VERSION ""

NS_ :

BS_:

BU_:

BO_ 2364677630 HVESP7MS1: 8 Vector__XXX
 SG_ Hvesp7Module1OperationalStatus : 0|2@1+ (1,0) [0|3] "" Vector__XXX
 SG_ Hvesp7Module2OperationalStatus : 2|2@1+ (1,0) [0|3] "" Vector__XXX
 SG_ Hvesp7Module3OperationalStatus : 4|2@1+ (1,0) [0|3] "" Vector__XXX
 SG_ Hvesp7Module4OperationalStatus : 6|2@1+ (1,0) [0|3] "" Vector__XXX
 SG_ Hvesp7Module5OperationalStatus : 8|2@1+ (1,0) [0|3] "" Vector__XXX
 SG_ Hvesp7Module6OperationalStatus : 10|2@1+ (1,0) [0|3] "" Vector__XXX
 SG_ Hvesp7Module7OperationalStatus : 12|2@1+ (1,0) [0|3] "" Vector__XXX
 SG_ Hvesp7Module8OperationalStatus : 14|2@1+ (1,0) [0|3] "" Vector__XXX
 SG_ Hvesp7Module9OperationalStatus : 16|2@1+ (1,0) [0|3] "" Vector__XXX
 SG_ Hvesp7Module10OperationalStatus : 18|2@1+ (1,0) [0|3] "" Vector__XXX
 SG_ Hvesp7Module11OperationalStatus : 20|2@1+ (1,0) [0|3] "" Vector__XXX
 SG_ Hvesp7Module12OperationalStatus : 22|2@1+ (1,0) [0|3] "" Vector__XXX
 SG_ Hvesp7Module13OperationalStatus : 24|2@1+ (1,0) [0|3] "" Vector__XXX
 SG_ Hvesp7Module14OperationalStatus : 26|2@1+ (1,0) [0|3] "" Vector__XXX
 SG_ Hvesp7Module15OperationalStatus : 28|2@1+ (1,0) [0|3] "" Vector__XXX
 SG_ Hvesp7Module16OperationalStatus : 30|2@1+ (1,0) [0|3] "" Vector__XXX
 SG_ Hvesp7Module17OperationalStatus : 32|2@1+ (1,0) [0|3] "" Vector__XXX
 SG_ Hvesp7Module18OperationalStatus : 34|2@1+ (1,0) [0|3] "" Vector__XXX
 SG_ Hvesp7Module19OperationalStatus : 36|2@1+ (1,0) [0|3] "" Vector__XXX
 SG_ Hvesp7Module20OperationalStatus : 38|2@1+ (1,0) [0|3] "" Vector__XXX
 SG_ Hvesp7Module21OperationalStatus : 40|2@1+ (1,0) [0|3] "" Vector__XXX
 SG_ Hvesp7Module22OperationalStatus : 42|2@1+ (1,0) [0|3] "" Vector__XXX
 SG_ Hvesp7Module23OperationalStatus : 44|2@1+ (1,0) [0|3] "" Vector__XXX
 SG_ Hvesp7Module24OperationalStatus : 46|2@1+ (1,0) [0|3] "" Vector__XXX
 SG_ Hvesp7Module25OperationalStatus : 48|2@1+ (1,0) [0|3] "" Vector__XXX
 SG_ Hvesp7Module26OperationalStatus : 50|2@1+ (1,0) [0|3] "" Vector__XXX
 SG_ Hvesp7Module27OperationalStatus : 52|2@1+ (1,0) [0|3] "" Vector__XXX
 SG_ Hvesp7Module28OperationalStatus : 54|2@1+ (1,0) [0|3] "" Vector__XXX
 SG_ Hvesp7Module29OperationalStatus : 56|2@1+ (1,0) [0|3] "" Vector__XXX
 SG_ Hvesp7Module30OperationalStatus : 58|2@1+ (1,0) [0|3] "" Vector__XXX
 SG_ Hvesp7Module31OperationalStatus : 60|2@1+ (1,0) [0|3] "" Vector__XXX
 SG_ Hvesp7Module32OperationalStatus : 62|2@1+ (1,0) [0|3] "" Vector__XXX

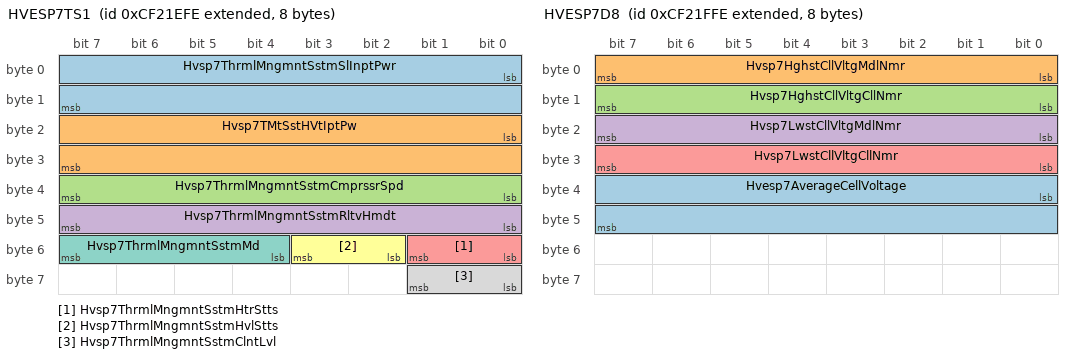
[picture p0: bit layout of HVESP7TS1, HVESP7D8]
BO_ 2364677886 HVESP7TS1: 8 Vector__XXX
 SG_ Hvsp7ThrmlMngmntSstmSlInptPwr : 0|16@1+ (0.5,0) [0|32127.5] "W" Vector__XXX
 SG_ Hvsp7TMtSstHVtIptPw : 16|16@1+ (0.5,0) [0|32127.5] "W" Vector__XXX
 SG_ Hvsp7ThrmlMngmntSstmCmprssrSpd : 32|8@1+ (32,0) [0|8000] "rpm" Vector__XXX
 SG_ Hvsp7ThrmlMngmntSstmRltvHmdt : 40|8@1+ (0.4,0) [0|100] "%" Vector__XXX
 SG_ Hvsp7ThrmlMngmntSstmHtrStts : 48|2@1+ (1,0) [0|3] "" Vector__XXX
 SG_ Hvsp7ThrmlMngmntSstmHvlStts : 50|2@1+ (1,0) [0|3] "" Vector__XXX
 SG_ Hvsp7ThrmlMngmntSstmMd : 52|4@1+ (1,0) [0|15] "" Vector__XXX
 SG_ Hvsp7ThrmlMngmntSstmClntLvl : 56|2@1+ (1,0) [0|3] "" Vector__XXX

BO_ 2364678142 HVESP7D8: 8 Vector__XXX
 SG_ Hvesp7AverageCellVoltage : 32|16@1+ (0.001,0) [0|64.255] "V" Vector__XXX
 SG_ Hvsp7HghstCllVltgMdlNmr : 0|8@1+ (1,0) [0|250] "count" Vector__XXX
 SG_ Hvsp7HghstCllVltgCllNmr : 8|8@1+ (1,0) [0|250] "count" Vector__XXX
 SG_ Hvsp7LwstCllVltgMdlNmr : 16|8@1+ (1,0) [0|250] "count" Vector__XXX
 SG_ Hvsp7LwstCllVltgCllNmr : 24|8@1+ (1,0) [0|250] "count" Vector__XXX

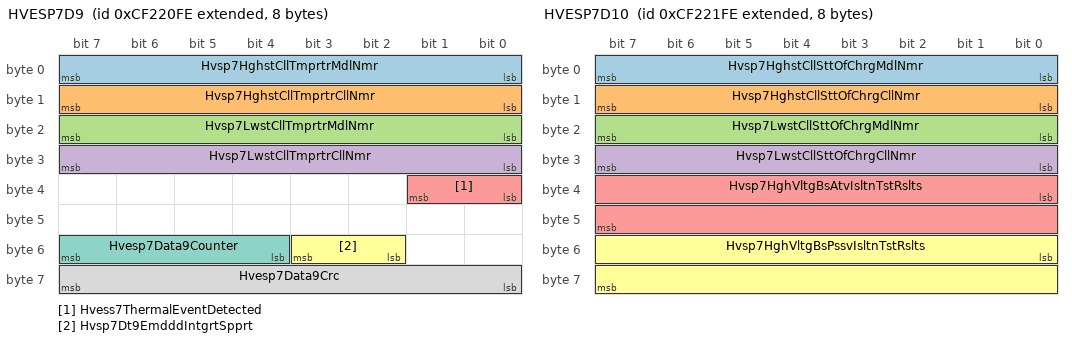
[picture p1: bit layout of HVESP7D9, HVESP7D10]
BO_ 2364678398 HVESP7D9: 8 Vector__XXX
 SG_ Hvsp7HghstCllTmprtrMdlNmr : 0|8@1+ (1,0) [0|250] "count" Vector__XXX
 SG_ Hvsp7HghstCllTmprtrCllNmr : 8|8@1+ (1,0) [0|250] "count" Vector__XXX
 SG_ Hvsp7LwstCllTmprtrMdlNmr : 16|8@1+ (1,0) [0|250] "count" Vector__XXX
 SG_ Hvsp7LwstCllTmprtrCllNmr : 24|8@1+ (1,0) [0|250] "count" Vector__XXX
 SG_ Hvess7ThermalEventDetected : 32|2@1+ (1,0) [0|3] "" Vector__XXX
 SG_ Hvsp7Dt9EmdddIntgrtSpprt : 50|2@1+ (1,0) [0|3] "" Vector__XXX
 SG_ Hvesp7Data9Counter : 52|4@1+ (1,0) [0|15] "" Vector__XXX
 SG_ Hvesp7Data9Crc : 56|8@1+ (1,0) [0|250] "count" Vector__XXX

BO_ 2364678654 HVESP7D10: 8 Vector__XXX
 SG_ Hvsp7HghstCllSttOfChrgMdlNmr : 0|8@1+ (1,0) [0|250] "count" Vector__XXX
 SG_ Hvsp7HghstCllSttOfChrgCllNmr : 8|8@1+ (1,0) [0|250] "count" Vector__XXX
 SG_ Hvsp7LwstCllSttOfChrgMdlNmr : 16|8@1+ (1,0) [0|250] "count" Vector__XXX
 SG_ Hvsp7LwstCllSttOfChrgCllNmr : 24|8@1+ (1,0) [0|250] "count" Vector__XXX
 SG_ Hvsp7HghVltgBsAtvIsltnTstRslts : 32|16@1+ (0.1,0) [0|6425.5] "OhmPerV" Vector__XXX
 SG_ Hvsp7HghVltgBsPssvIsltnTstRslts : 48|16@1+ (0.1,0) [0|6425.5] "OhmPerV" Vector__XXX

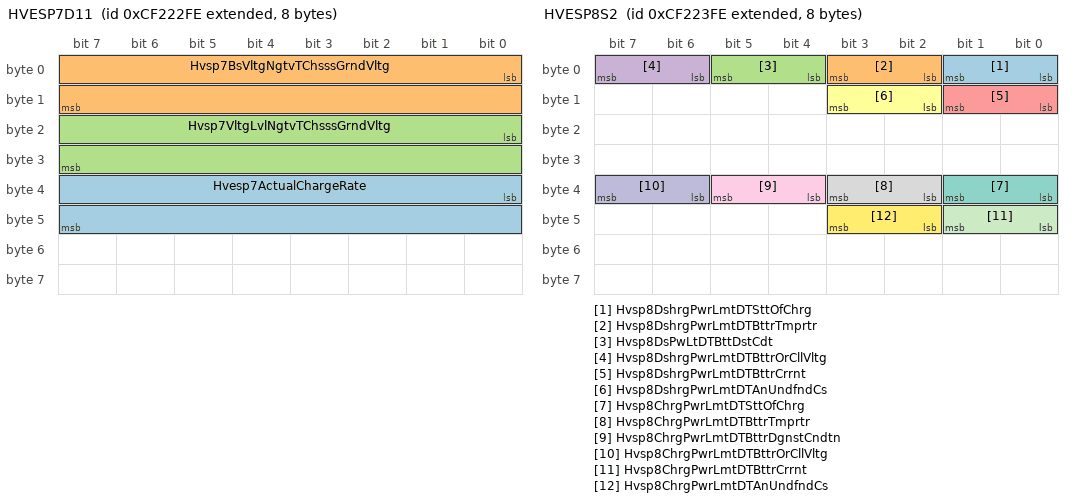
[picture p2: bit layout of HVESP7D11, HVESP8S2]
BO_ 2364678910 HVESP7D11: 8 Vector__XXX
 SG_ Hvesp7ActualChargeRate : 32|16@1+ (0.05,0) [0|3212.75] "kW" Vector__XXX
 SG_ Hvsp7BsVltgNgtvTChsssGrndVltg : 0|16@1+ (0.05,0) [0|3212.75] "V" Vector__XXX
 SG_ Hvsp7VltgLvlNgtvTChsssGrndVltg : 16|16@1+ (0.05,0) [0|3212.75] "V" Vector__XXX

BO_ 2364679166 HVESP8S2: 8 Vector__XXX
 SG_ Hvsp8DshrgPwrLmtDTSttOfChrg : 0|2@1+ (1,0) [0|3] "" Vector__XXX
 SG_ Hvsp8DshrgPwrLmtDTBttrTmprtr : 2|2@1+ (1,0) [0|3] "" Vector__XXX
 SG_ Hvsp8DsPwLtDTBttDstCdt : 4|2@1+ (1,0) [0|3] "" Vector__XXX
 SG_ Hvsp8DshrgPwrLmtDTBttrOrCllVltg : 6|2@1+ (1,0) [0|3] "" Vector__XXX
 SG_ Hvsp8DshrgPwrLmtDTBttrCrrnt : 8|2@1+ (1,0) [0|3] "" Vector__XXX
 SG_ Hvsp8DshrgPwrLmtDTAnUndfndCs : 10|2@1+ (1,0) [0|3] "" Vector__XXX
 SG_ Hvsp8ChrgPwrLmtDTSttOfChrg : 32|2@1+ (1,0) [0|3] "" Vector__XXX
 SG_ Hvsp8ChrgPwrLmtDTBttrTmprtr : 34|2@1+ (1,0) [0|3] "" Vector__XXX
 SG_ Hvsp8ChrgPwrLmtDTBttrDgnstCndtn : 36|2@1+ (1,0) [0|3] "" Vector__XXX
 SG_ Hvsp8ChrgPwrLmtDTBttrOrCllVltg : 38|2@1+ (1,0) [0|3] "" Vector__XXX
 SG_ Hvsp8ChrgPwrLmtDTBttrCrrnt : 40|2@1+ (1,0) [0|3] "" Vector__XXX
 SG_ Hvsp8ChrgPwrLmtDTAnUndfndCs : 42|2@1+ (1,0) [0|3] "" Vector__XXX

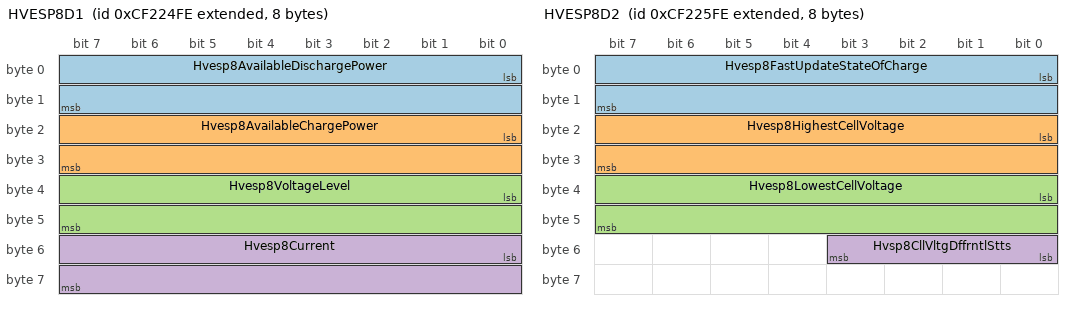
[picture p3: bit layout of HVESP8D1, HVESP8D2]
BO_ 2364679422 HVESP8D1: 8 Vector__XXX
 SG_ Hvesp8AvailableDischargePower : 0|16@1+ (0.05,0) [0|3212.75] "kW" Vector__XXX
 SG_ Hvesp8AvailableChargePower : 16|16@1+ (0.05,0) [0|3212.75] "kW" Vector__XXX
 SG_ Hvesp8VoltageLevel : 32|16@1+ (0.05,0) [0|3212.75] "V" Vector__XXX
 SG_ Hvesp8Current : 48|16@1+ (0.05,-1600) [-1600|1612.75] "A" Vector__XXX

BO_ 2364679678 HVESP8D2: 8 Vector__XXX
 SG_ Hvesp8FastUpdateStateOfCharge : 0|16@1+ (0.0015625,0) [0|100.3984375] "%" Vector__XXX
 SG_ Hvesp8HighestCellVoltage : 16|16@1+ (0.001,0) [0|64.255] "V" Vector__XXX
 SG_ Hvesp8LowestCellVoltage : 32|16@1+ (0.001,0) [0|64.255] "V" Vector__XXX
 SG_ Hvsp8CllVltgDffrntlStts : 48|4@1+ (1,0) [0|15] "" Vector__XXX

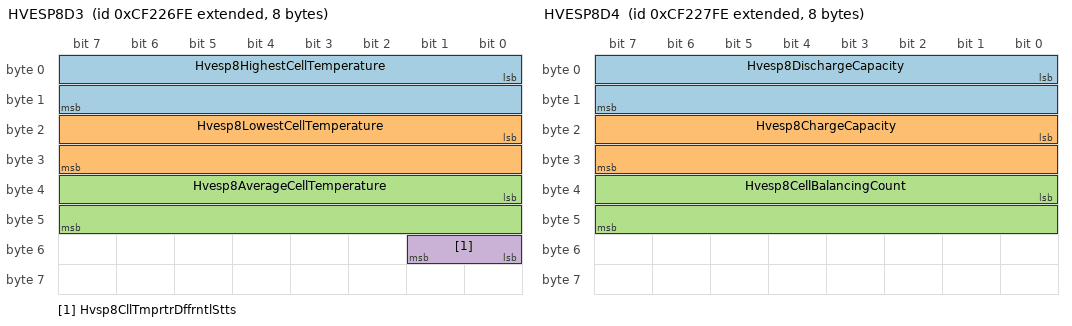
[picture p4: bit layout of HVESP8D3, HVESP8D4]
BO_ 2364679934 HVESP8D3: 8 Vector__XXX
 SG_ Hvesp8HighestCellTemperature : 0|16@1+ (0.03125,-273) [-273|1734.96875] "degC" Vector__XXX
 SG_ Hvesp8LowestCellTemperature : 16|16@1+ (0.03125,-273) [-273|1734.96875] "degC" Vector__XXX
 SG_ Hvesp8AverageCellTemperature : 32|16@1+ (0.03125,-273) [-273|1734.96875] "degC" Vector__XXX
 SG_ Hvsp8CllTmprtrDffrntlStts : 48|2@1+ (1,0) [0|3] "" Vector__XXX

BO_ 2364680190 HVESP8D4: 8 Vector__XXX
 SG_ Hvesp8DischargeCapacity : 0|16@1+ (0.01,0) [0|642.55] "Ah" Vector__XXX
 SG_ Hvesp8ChargeCapacity : 16|16@1+ (0.01,0) [0|642.55] "Ah" Vector__XXX
 SG_ Hvesp8CellBalancingCount : 32|16@1+ (1,0) [0|64255] "count" Vector__XXX

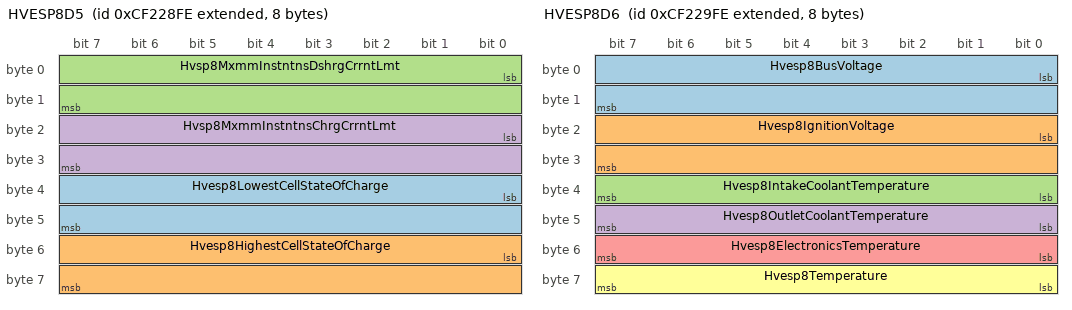
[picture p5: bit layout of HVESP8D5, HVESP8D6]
BO_ 2364680446 HVESP8D5: 8 Vector__XXX
 SG_ Hvesp8LowestCellStateOfCharge : 32|16@1+ (0.0015625,0) [0|100.3984375] "%" Vector__XXX
 SG_ Hvesp8HighestCellStateOfCharge : 48|16@1+ (0.0015625,0) [0|100.3984375] "%" Vector__XXX
 SG_ Hvsp8MxmmInstntnsDshrgCrrntLmt : 0|16@1+ (0.05,-1600) [-1600|0] "A" Vector__XXX
 SG_ Hvsp8MxmmInstntnsChrgCrrntLmt : 16|16@1+ (0.05,-1600) [0|1612.75] "A" Vector__XXX

BO_ 2364680702 HVESP8D6: 8 Vector__XXX
 SG_ Hvesp8BusVoltage : 0|16@1+ (0.05,0) [0|3212.75] "V" Vector__XXX
 SG_ Hvesp8IgnitionVoltage : 16|16@1+ (0.01,0) [0|642.55] "V" Vector__XXX
 SG_ Hvesp8IntakeCoolantTemperature : 32|8@1+ (1,-40) [-40|210] "degC" Vector__XXX
 SG_ Hvesp8OutletCoolantTemperature : 40|8@1+ (1,-40) [-40|210] "degC" Vector__XXX
 SG_ Hvesp8ElectronicsTemperature : 48|8@1+ (1,-40) [-40|210] "degC" Vector__XXX
 SG_ Hvesp8Temperature : 56|8@1+ (1,-40) [-40|210] "degC" Vector__XXX

BO_ 2364680958 HVESP8S1: 8 Vector__XXX
 SG_ Hvesp8HvilStatus : 20|2@1+ (1,0) [0|3] "" Vector__XXX
 SG_ Hvesp8InertiaSwitchStatus : 22|2@1+ (1,0) [0|3] "" Vector__XXX
 SG_ Hvesp8StateOfChargeStatus : 24|4@1+ (1,0) [0|15] "" Vector__XXX
 SG_ Hvesp8CellBalanceStatus : 28|2@1+ (1,0) [0|3] "" Vector__XXX
 SG_ Hvesp8CellBalancingActive : 30|2@1+ (1,0) [0|3] "" Vector__XXX
 SG_ Hvesp8InternalChargerStatus : 32|2@1+ (1,0) [0|3] "" Vector__XXX
 SG_ Hvesp8OperationalStatus : 44|4@1+ (1,0) [0|15] "" Vector__XXX
 SG_ Hvesp8Status1Counter : 52|4@1+ (1,0) [0|15] "" Vector__XXX
 SG_ Hvesp8Status1Crc : 56|8@1+ (1,0) [0|250] "count" Vector__XXX
 SG_ Hvsp8HghVltgBsPstvCnttrStt : 0|2@1+ (1,0) [0|3] "" Vector__XXX
 SG_ Hvsp8HghVltgBsNgtvCnttrStt : 2|2@1+ (1,0) [0|3] "" Vector__XXX
 SG_ Hvsp8HghVltgBsDsnntFrwrnng : 4|4@1+ (1,0) [0|15] "" Vector__XXX
 SG_ Hvsp8HghVltgBsPrChrgRlStt : 8|2@1+ (1,0) [0|3] "" Vector__XXX
 SG_ Hvsp8CntrOfPkCnttrStt : 10|2@1+ (1,0) [0|3] "" Vector__XXX
 SG_ Hvsp8HghVltgBsAtvIsltnTstStts : 12|4@1+ (1,0) [0|15] "" Vector__XXX
 SG_ Hvsp8HghVltgBsPssvIsltnTstStts : 16|4@1+ (1,0) [0|15] "" Vector__XXX
 SG_ Hvsp8HghVltgBsCnntnStts : 40|4@1+ (1,0) [0|15] "" Vector__XXX

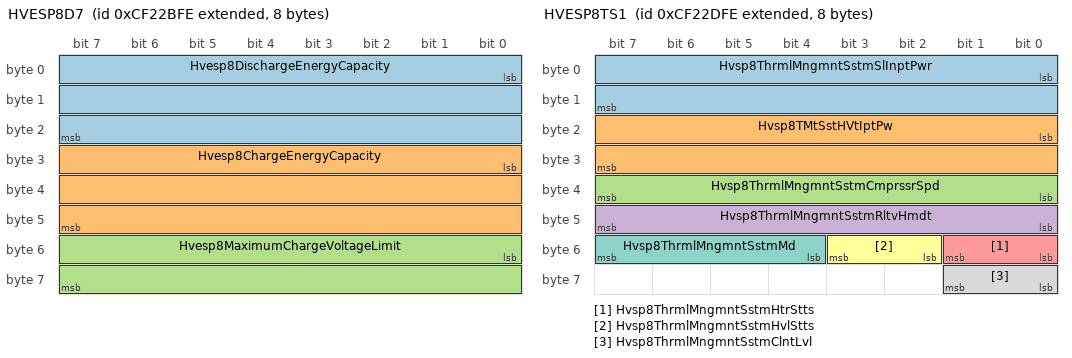
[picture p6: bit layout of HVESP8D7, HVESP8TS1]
BO_ 2364681214 HVESP8D7: 8 Vector__XXX
 SG_ Hvesp8DischargeEnergyCapacity : 0|24@1+ (0.001,0) [0|16449.535] "kWh" Vector__XXX
 SG_ Hvesp8ChargeEnergyCapacity : 24|24@1+ (0.001,0) [0|16449.535] "kWh" Vector__XXX
 SG_ Hvesp8MaximumChargeVoltageLimit : 48|16@1+ (0.05,0) [0|3212.75] "V" Vector__XXX

BO_ 2364681470 HVESP8MS1: 8 Vector__XXX
 SG_ Hvesp8Module1OperationalStatus : 0|2@1+ (1,0) [0|3] "" Vector__XXX
 SG_ Hvesp8Module2OperationalStatus : 2|2@1+ (1,0) [0|3] "" Vector__XXX
 SG_ Hvesp8Module3OperationalStatus : 4|2@1+ (1,0) [0|3] "" Vector__XXX
 SG_ Hvesp8Module4OperationalStatus : 6|2@1+ (1,0) [0|3] "" Vector__XXX
 SG_ Hvesp8Module5OperationalStatus : 8|2@1+ (1,0) [0|3] "" Vector__XXX
 SG_ Hvesp8Module6OperationalStatus : 10|2@1+ (1,0) [0|3] "" Vector__XXX
 SG_ Hvesp8Module7OperationalStatus : 12|2@1+ (1,0) [0|3] "" Vector__XXX
 SG_ Hvesp8Module8OperationalStatus : 14|2@1+ (1,0) [0|3] "" Vector__XXX
 SG_ Hvesp8Module9OperationalStatus : 16|2@1+ (1,0) [0|3] "" Vector__XXX
 SG_ Hvesp8Module10OperationalStatus : 18|2@1+ (1,0) [0|3] "" Vector__XXX
 SG_ Hvesp8Module11OperationalStatus : 20|2@1+ (1,0) [0|3] "" Vector__XXX
 SG_ Hvesp8Module12OperationalStatus : 22|2@1+ (1,0) [0|3] "" Vector__XXX
 SG_ Hvesp8Module13OperationalStatus : 24|2@1+ (1,0) [0|3] "" Vector__XXX
 SG_ Hvesp8Module14OperationalStatus : 26|2@1+ (1,0) [0|3] "" Vector__XXX
 SG_ Hvesp8Module15OperationalStatus : 28|2@1+ (1,0) [0|3] "" Vector__XXX
 SG_ Hvesp8Module16OperationalStatus : 30|2@1+ (1,0) [0|3] "" Vector__XXX
 SG_ Hvesp8Module17OperationalStatus : 32|2@1+ (1,0) [0|3] "" Vector__XXX
 SG_ Hvesp8Module18OperationalStatus : 34|2@1+ (1,0) [0|3] "" Vector__XXX
 SG_ Hvesp8Module19OperationalStatus : 36|2@1+ (1,0) [0|3] "" Vector__XXX
 SG_ Hvesp8Module20OperationalStatus : 38|2@1+ (1,0) [0|3] "" Vector__XXX
 SG_ Hvesp8Module21OperationalStatus : 40|2@1+ (1,0) [0|3] "" Vector__XXX
 SG_ Hvesp8Module22OperationalStatus : 42|2@1+ (1,0) [0|3] "" Vector__XXX
 SG_ Hvesp8Module23OperationalStatus : 44|2@1+ (1,0) [0|3] "" Vector__XXX
 SG_ Hvesp8Module24OperationalStatus : 46|2@1+ (1,0) [0|3] "" Vector__XXX
 SG_ Hvesp8Module25OperationalStatus : 48|2@1+ (1,0) [0|3] "" Vector__XXX
 SG_ Hvesp8Module26OperationalStatus : 50|2@1+ (1,0) [0|3] "" Vector__XXX
 SG_ Hvesp8Module27OperationalStatus : 52|2@1+ (1,0) [0|3] "" Vector__XXX
 SG_ Hvesp8Module28OperationalStatus : 54|2@1+ (1,0) [0|3] "" Vector__XXX
 SG_ Hvesp8Module29OperationalStatus : 56|2@1+ (1,0) [0|3] "" Vector__XXX
 SG_ Hvesp8Module30OperationalStatus : 58|2@1+ (1,0) [0|3] "" Vector__XXX
 SG_ Hvesp8Module31OperationalStatus : 60|2@1+ (1,0) [0|3] "" Vector__XXX
 SG_ Hvesp8Module32OperationalStatus : 62|2@1+ (1,0) [0|3] "" Vector__XXX

BO_ 2364681726 HVESP8TS1: 8 Vector__XXX
 SG_ Hvsp8ThrmlMngmntSstmSlInptPwr : 0|16@1+ (0.5,0) [0|32127.5] "W" Vector__XXX
 SG_ Hvsp8TMtSstHVtIptPw : 16|16@1+ (0.5,0) [0|32127.5] "W" Vector__XXX
 SG_ Hvsp8ThrmlMngmntSstmCmprssrSpd : 32|8@1+ (32,0) [0|8000] "rpm" Vector__XXX
 SG_ Hvsp8ThrmlMngmntSstmRltvHmdt : 40|8@1+ (0.4,0) [0|100] "%" Vector__XXX
 SG_ Hvsp8ThrmlMngmntSstmHtrStts : 48|2@1+ (1,0) [0|3] "" Vector__XXX
 SG_ Hvsp8ThrmlMngmntSstmHvlStts : 50|2@1+ (1,0) [0|3] "" Vector__XXX
 SG_ Hvsp8ThrmlMngmntSstmMd : 52|4@1+ (1,0) [0|15] "" Vector__XXX
 SG_ Hvsp8ThrmlMngmntSstmClntLvl : 56|2@1+ (1,0) [0|3] "" Vector__XXX

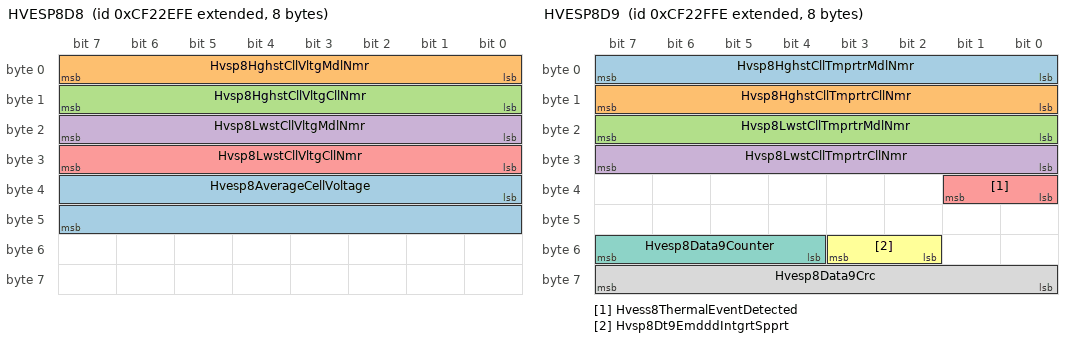
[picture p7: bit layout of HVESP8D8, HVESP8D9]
BO_ 2364681982 HVESP8D8: 8 Vector__XXX
 SG_ Hvesp8AverageCellVoltage : 32|16@1+ (0.001,0) [0|64.255] "V" Vector__XXX
 SG_ Hvsp8HghstCllVltgMdlNmr : 0|8@1+ (1,0) [0|250] "count" Vector__XXX
 SG_ Hvsp8HghstCllVltgCllNmr : 8|8@1+ (1,0) [0|250] "count" Vector__XXX
 SG_ Hvsp8LwstCllVltgMdlNmr : 16|8@1+ (1,0) [0|250] "count" Vector__XXX
 SG_ Hvsp8LwstCllVltgCllNmr : 24|8@1+ (1,0) [0|250] "count" Vector__XXX

BO_ 2364682238 HVESP8D9: 8 Vector__XXX
 SG_ Hvsp8HghstCllTmprtrMdlNmr : 0|8@1+ (1,0) [0|250] "count" Vector__XXX
 SG_ Hvsp8HghstCllTmprtrCllNmr : 8|8@1+ (1,0) [0|250] "count" Vector__XXX
 SG_ Hvsp8LwstCllTmprtrMdlNmr : 16|8@1+ (1,0) [0|250] "count" Vector__XXX
 SG_ Hvsp8LwstCllTmprtrCllNmr : 24|8@1+ (1,0) [0|250] "count" Vector__XXX
 SG_ Hvess8ThermalEventDetected : 32|2@1+ (1,0) [0|3] "" Vector__XXX
 SG_ Hvsp8Dt9EmdddIntgrtSpprt : 50|2@1+ (1,0) [0|3] "" Vector__XXX
 SG_ Hvesp8Data9Counter : 52|4@1+ (1,0) [0|15] "" Vector__XXX
 SG_ Hvesp8Data9Crc : 56|8@1+ (1,0) [0|250] "count" Vector__XXX

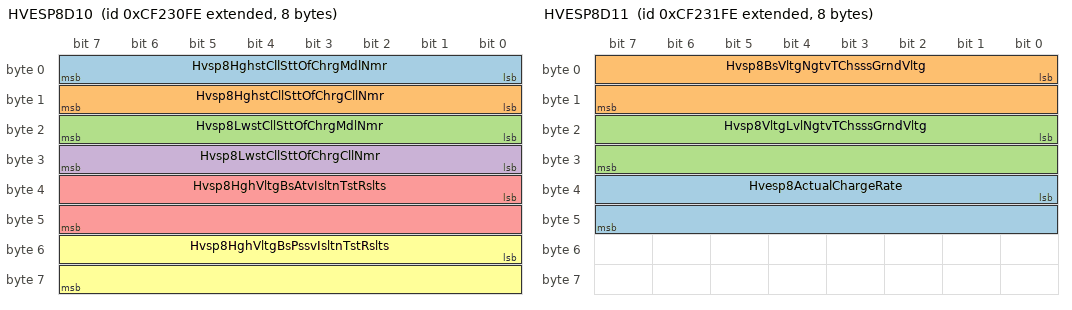
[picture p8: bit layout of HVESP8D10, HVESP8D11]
BO_ 2364682494 HVESP8D10: 8 Vector__XXX
 SG_ Hvsp8HghstCllSttOfChrgMdlNmr : 0|8@1+ (1,0) [0|250] "count" Vector__XXX
 SG_ Hvsp8HghstCllSttOfChrgCllNmr : 8|8@1+ (1,0) [0|250] "count" Vector__XXX
 SG_ Hvsp8LwstCllSttOfChrgMdlNmr : 16|8@1+ (1,0) [0|250] "count" Vector__XXX
 SG_ Hvsp8LwstCllSttOfChrgCllNmr : 24|8@1+ (1,0) [0|250] "count" Vector__XXX
 SG_ Hvsp8HghVltgBsAtvIsltnTstRslts : 32|16@1+ (0.1,0) [0|6425.5] "OhmPerV" Vector__XXX
 SG_ Hvsp8HghVltgBsPssvIsltnTstRslts : 48|16@1+ (0.1,0) [0|6425.5] "OhmPerV" Vector__XXX

BO_ 2364682750 HVESP8D11: 8 Vector__XXX
 SG_ Hvesp8ActualChargeRate : 32|16@1+ (0.05,0) [0|3212.75] "kW" Vector__XXX
 SG_ Hvsp8BsVltgNgtvTChsssGrndVltg : 0|16@1+ (0.05,0) [0|3212.75] "V" Vector__XXX
 SG_ Hvsp8VltgLvlNgtvTChsssGrndVltg : 16|16@1+ (0.05,0) [0|3212.75] "V" Vector__XXX

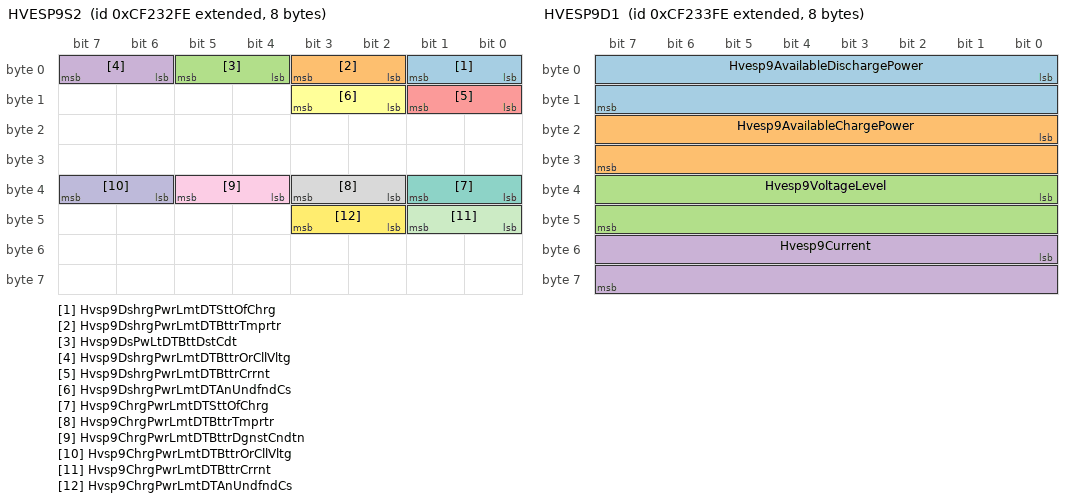
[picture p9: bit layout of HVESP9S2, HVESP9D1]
BO_ 2364683006 HVESP9S2: 8 Vector__XXX
 SG_ Hvsp9DshrgPwrLmtDTSttOfChrg : 0|2@1+ (1,0) [0|3] "" Vector__XXX
 SG_ Hvsp9DshrgPwrLmtDTBttrTmprtr : 2|2@1+ (1,0) [0|3] "" Vector__XXX
 SG_ Hvsp9DsPwLtDTBttDstCdt : 4|2@1+ (1,0) [0|3] "" Vector__XXX
 SG_ Hvsp9DshrgPwrLmtDTBttrOrCllVltg : 6|2@1+ (1,0) [0|3] "" Vector__XXX
 SG_ Hvsp9DshrgPwrLmtDTBttrCrrnt : 8|2@1+ (1,0) [0|3] "" Vector__XXX
 SG_ Hvsp9DshrgPwrLmtDTAnUndfndCs : 10|2@1+ (1,0) [0|3] "" Vector__XXX
 SG_ Hvsp9ChrgPwrLmtDTSttOfChrg : 32|2@1+ (1,0) [0|3] "" Vector__XXX
 SG_ Hvsp9ChrgPwrLmtDTBttrTmprtr : 34|2@1+ (1,0) [0|3] "" Vector__XXX
 SG_ Hvsp9ChrgPwrLmtDTBttrDgnstCndtn : 36|2@1+ (1,0) [0|3] "" Vector__XXX
 SG_ Hvsp9ChrgPwrLmtDTBttrOrCllVltg : 38|2@1+ (1,0) [0|3] "" Vector__XXX
 SG_ Hvsp9ChrgPwrLmtDTBttrCrrnt : 40|2@1+ (1,0) [0|3] "" Vector__XXX
 SG_ Hvsp9ChrgPwrLmtDTAnUndfndCs : 42|2@1+ (1,0) [0|3] "" Vector__XXX

BO_ 2364683262 HVESP9D1: 8 Vector__XXX
 SG_ Hvesp9AvailableDischargePower : 0|16@1+ (0.05,0) [0|3212.75] "kW" Vector__XXX
 SG_ Hvesp9AvailableChargePower : 16|16@1+ (0.05,0) [0|3212.75] "kW" Vector__XXX
 SG_ Hvesp9VoltageLevel : 32|16@1+ (0.05,0) [0|3212.75] "V" Vector__XXX
 SG_ Hvesp9Current : 48|16@1+ (0.05,-1600) [-1600|1612.75] "A" Vector__XXX

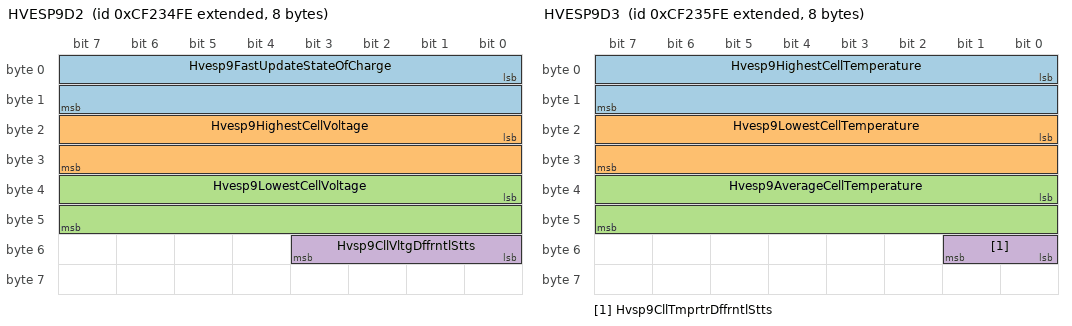
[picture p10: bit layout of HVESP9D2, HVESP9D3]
BO_ 2364683518 HVESP9D2: 8 Vector__XXX
 SG_ Hvesp9FastUpdateStateOfCharge : 0|16@1+ (0.0015625,0) [0|100.3984375] "%" Vector__XXX
 SG_ Hvesp9HighestCellVoltage : 16|16@1+ (0.001,0) [0|64.255] "V" Vector__XXX
 SG_ Hvesp9LowestCellVoltage : 32|16@1+ (0.001,0) [0|64.255] "V" Vector__XXX
 SG_ Hvsp9CllVltgDffrntlStts : 48|4@1+ (1,0) [0|15] "" Vector__XXX

BO_ 2364683774 HVESP9D3: 8 Vector__XXX
 SG_ Hvesp9HighestCellTemperature : 0|16@1+ (0.03125,-273) [-273|1734.96875] "degC" Vector__XXX
 SG_ Hvesp9LowestCellTemperature : 16|16@1+ (0.03125,-273) [-273|1734.96875] "degC" Vector__XXX
 SG_ Hvesp9AverageCellTemperature : 32|16@1+ (0.03125,-273) [-273|1734.96875] "degC" Vector__XXX
 SG_ Hvsp9CllTmprtrDffrntlStts : 48|2@1+ (1,0) [0|3] "" Vector__XXX

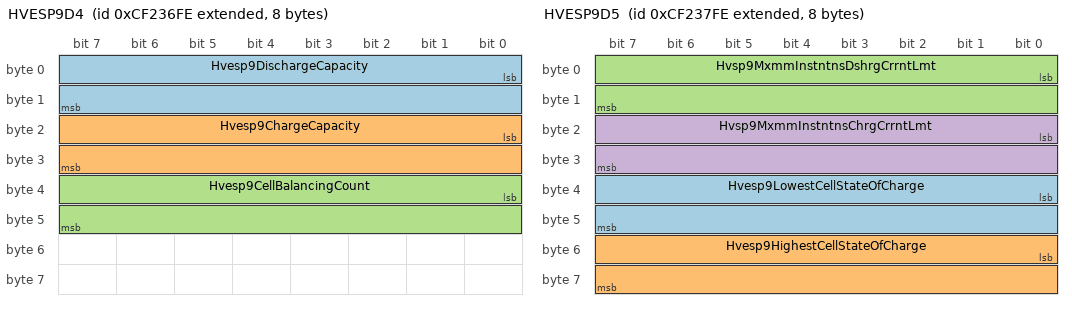
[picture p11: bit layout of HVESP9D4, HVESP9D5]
BO_ 2364684030 HVESP9D4: 8 Vector__XXX
 SG_ Hvesp9DischargeCapacity : 0|16@1+ (0.01,0) [0|642.55] "Ah" Vector__XXX
 SG_ Hvesp9ChargeCapacity : 16|16@1+ (0.01,0) [0|642.55] "Ah" Vector__XXX
 SG_ Hvesp9CellBalancingCount : 32|16@1+ (1,0) [0|64255] "count" Vector__XXX

BO_ 2364684286 HVESP9D5: 8 Vector__XXX
 SG_ Hvesp9LowestCellStateOfCharge : 32|16@1+ (0.0015625,0) [0|100.3984375] "%" Vector__XXX
 SG_ Hvesp9HighestCellStateOfCharge : 48|16@1+ (0.0015625,0) [0|100.3984375] "%" Vector__XXX
 SG_ Hvsp9MxmmInstntnsDshrgCrrntLmt : 0|16@1+ (0.05,-1600) [-1600|0] "A" Vector__XXX
 SG_ Hvsp9MxmmInstntnsChrgCrrntLmt : 16|16@1+ (0.05,-1600) [0|1612.75] "A" Vector__XXX

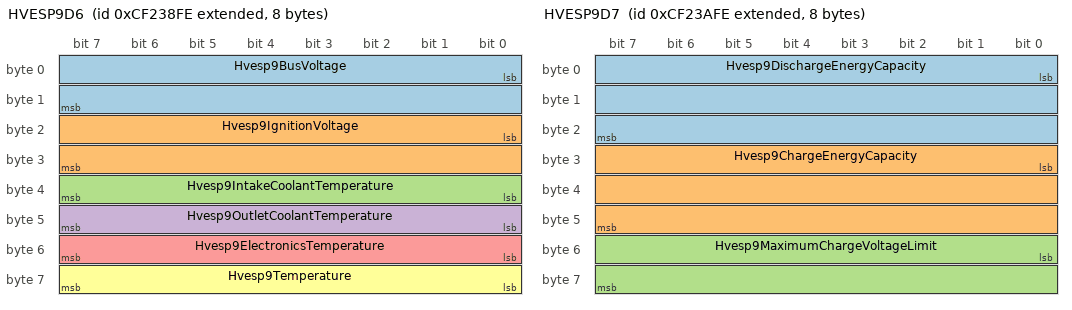
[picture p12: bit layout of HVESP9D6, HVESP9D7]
BO_ 2364684542 HVESP9D6: 8 Vector__XXX
 SG_ Hvesp9BusVoltage : 0|16@1+ (0.05,0) [0|3212.75] "V" Vector__XXX
 SG_ Hvesp9IgnitionVoltage : 16|16@1+ (0.01,0) [0|642.55] "V" Vector__XXX
 SG_ Hvesp9IntakeCoolantTemperature : 32|8@1+ (1,-40) [-40|210] "degC" Vector__XXX
 SG_ Hvesp9OutletCoolantTemperature : 40|8@1+ (1,-40) [-40|210] "degC" Vector__XXX
 SG_ Hvesp9ElectronicsTemperature : 48|8@1+ (1,-40) [-40|210] "degC" Vector__XXX
 SG_ Hvesp9Temperature : 56|8@1+ (1,-40) [-40|210] "degC" Vector__XXX

BO_ 2364684798 HVESP9S1: 8 Vector__XXX
 SG_ Hvesp9HvilStatus : 20|2@1+ (1,0) [0|3] "" Vector__XXX
 SG_ Hvesp9InertiaSwitchStatus : 22|2@1+ (1,0) [0|3] "" Vector__XXX
 SG_ Hvesp9StateOfChargeStatus : 24|4@1+ (1,0) [0|15] "" Vector__XXX
 SG_ Hvesp9CellBalanceStatus : 28|2@1+ (1,0) [0|3] "" Vector__XXX
 SG_ Hvesp9CellBalancingActive : 30|2@1+ (1,0) [0|3] "" Vector__XXX
 SG_ Hvesp9InternalChargerStatus : 32|2@1+ (1,0) [0|3] "" Vector__XXX
 SG_ Hvesp9OperationalStatus : 44|4@1+ (1,0) [0|15] "" Vector__XXX
 SG_ Hvesp9Status1Counter : 52|4@1+ (1,0) [0|15] "" Vector__XXX
 SG_ Hvesp9Status1Crc : 56|8@1+ (1,0) [0|250] "count" Vector__XXX
 SG_ Hvsp9HghVltgBsPstvCnttrStt : 0|2@1+ (1,0) [0|3] "" Vector__XXX
 SG_ Hvsp9HghVltgBsNgtvCnttrStt : 2|2@1+ (1,0) [0|3] "" Vector__XXX
 SG_ Hvsp9HghVltgBsDsnntFrwrnng : 4|4@1+ (1,0) [0|15] "" Vector__XXX
 SG_ Hvsp9HghVltgBsPrChrgRlStt : 8|2@1+ (1,0) [0|3] "" Vector__XXX
 SG_ Hvsp9CntrOfPkCnttrStt : 10|2@1+ (1,0) [0|3] "" Vector__XXX
 SG_ Hvsp9HghVltgBsAtvIsltnTstStts : 12|4@1+ (1,0) [0|15] "" Vector__XXX
 SG_ Hvsp9HghVltgBsPssvIsltnTstStts : 16|4@1+ (1,0) [0|15] "" Vector__XXX
 SG_ Hvsp9HghVltgBsCnntnStts : 40|4@1+ (1,0) [0|15] "" Vector__XXX

BO_ 2364685054 HVESP9D7: 8 Vector__XXX
 SG_ Hvesp9DischargeEnergyCapacity : 0|24@1+ (0.001,0) [0|16449.535] "kWh" Vector__XXX
 SG_ Hvesp9ChargeEnergyCapacity : 24|24@1+ (0.001,0) [0|16449.535] "kWh" Vector__XXX
 SG_ Hvesp9MaximumChargeVoltageLimit : 48|16@1+ (0.05,0) [0|3212.75] "V" Vector__XXX

BO_ 2364685310 HVESP9MS1: 8 Vector__XXX
 SG_ Hvesp9Module1OperationalStatus : 0|2@1+ (1,0) [0|3] "" Vector__XXX
 SG_ Hvesp9Module2OperationalStatus : 2|2@1+ (1,0) [0|3] "" Vector__XXX
 SG_ Hvesp9Module3OperationalStatus : 4|2@1+ (1,0) [0|3] "" Vector__XXX
 SG_ Hvesp9Module4OperationalStatus : 6|2@1+ (1,0) [0|3] "" Vector__XXX
 SG_ Hvesp9Module5OperationalStatus : 8|2@1+ (1,0) [0|3] "" Vector__XXX
 SG_ Hvesp9Module6OperationalStatus : 10|2@1+ (1,0) [0|3] "" Vector__XXX
 SG_ Hvesp9Module7OperationalStatus : 12|2@1+ (1,0) [0|3] "" Vector__XXX
 SG_ Hvesp9Module8OperationalStatus : 14|2@1+ (1,0) [0|3] "" Vector__XXX
 SG_ Hvesp9Module9OperationalStatus : 16|2@1+ (1,0) [0|3] "" Vector__XXX
 SG_ Hvesp9Module10OperationalStatus : 18|2@1+ (1,0) [0|3] "" Vector__XXX
 SG_ Hvesp9Module11OperationalStatus : 20|2@1+ (1,0) [0|3] "" Vector__XXX
 SG_ Hvesp9Module12OperationalStatus : 22|2@1+ (1,0) [0|3] "" Vector__XXX
 SG_ Hvesp9Module13OperationalStatus : 24|2@1+ (1,0) [0|3] "" Vector__XXX
 SG_ Hvesp9Module14OperationalStatus : 26|2@1+ (1,0) [0|3] "" Vector__XXX
 SG_ Hvesp9Module15OperationalStatus : 28|2@1+ (1,0) [0|3] "" Vector__XXX
 SG_ Hvesp9Module16OperationalStatus : 30|2@1+ (1,0) [0|3] "" Vector__XXX
 SG_ Hvesp9Module17OperationalStatus : 32|2@1+ (1,0) [0|3] "" Vector__XXX
 SG_ Hvesp9Module18OperationalStatus : 34|2@1+ (1,0) [0|3] "" Vector__XXX
 SG_ Hvesp9Module19OperationalStatus : 36|2@1+ (1,0) [0|3] "" Vector__XXX
 SG_ Hvesp9Module20OperationalStatus : 38|2@1+ (1,0) [0|3] "" Vector__XXX
 SG_ Hvesp9Module21OperationalStatus : 40|2@1+ (1,0) [0|3] "" Vector__XXX
 SG_ Hvesp9Module22OperationalStatus : 42|2@1+ (1,0) [0|3] "" Vector__XXX
 SG_ Hvesp9Module23OperationalStatus : 44|2@1+ (1,0) [0|3] "" Vector__XXX
 SG_ Hvesp9Module24OperationalStatus : 46|2@1+ (1,0) [0|3] "" Vector__XXX
 SG_ Hvesp9Module25OperationalStatus : 48|2@1+ (1,0) [0|3] "" Vector__XXX
 SG_ Hvesp9Module26OperationalStatus : 50|2@1+ (1,0) [0|3] "" Vector__XXX
 SG_ Hvesp9Module27OperationalStatus : 52|2@1+ (1,0) [0|3] "" Vector__XXX
 SG_ Hvesp9Module28OperationalStatus : 54|2@1+ (1,0) [0|3] "" Vector__XXX
 SG_ Hvesp9Module29OperationalStatus : 56|2@1+ (1,0) [0|3] "" Vector__XXX
 SG_ Hvesp9Module30OperationalStatus : 58|2@1+ (1,0) [0|3] "" Vector__XXX
 SG_ Hvesp9Module31OperationalStatus : 60|2@1+ (1,0) [0|3] "" Vector__XXX
 SG_ Hvesp9Module32OperationalStatus : 62|2@1+ (1,0) [0|3] "" Vector__XXX

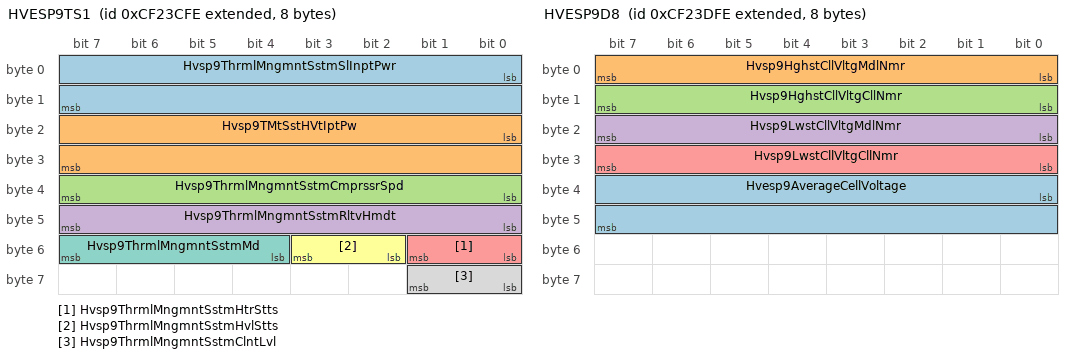
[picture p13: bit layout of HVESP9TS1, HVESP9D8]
BO_ 2364685566 HVESP9TS1: 8 Vector__XXX
 SG_ Hvsp9ThrmlMngmntSstmSlInptPwr : 0|16@1+ (0.5,0) [0|32127.5] "W" Vector__XXX
 SG_ Hvsp9TMtSstHVtIptPw : 16|16@1+ (0.5,0) [0|32127.5] "W" Vector__XXX
 SG_ Hvsp9ThrmlMngmntSstmCmprssrSpd : 32|8@1+ (32,0) [0|8000] "rpm" Vector__XXX
 SG_ Hvsp9ThrmlMngmntSstmRltvHmdt : 40|8@1+ (0.4,0) [0|100] "%" Vector__XXX
 SG_ Hvsp9ThrmlMngmntSstmHtrStts : 48|2@1+ (1,0) [0|3] "" Vector__XXX
 SG_ Hvsp9ThrmlMngmntSstmHvlStts : 50|2@1+ (1,0) [0|3] "" Vector__XXX
 SG_ Hvsp9ThrmlMngmntSstmMd : 52|4@1+ (1,0) [0|15] "" Vector__XXX
 SG_ Hvsp9ThrmlMngmntSstmClntLvl : 56|2@1+ (1,0) [0|3] "" Vector__XXX

BO_ 2364685822 HVESP9D8: 8 Vector__XXX
 SG_ Hvesp9AverageCellVoltage : 32|16@1+ (0.001,0) [0|64.255] "V" Vector__XXX
 SG_ Hvsp9HghstCllVltgMdlNmr : 0|8@1+ (1,0) [0|250] "count" Vector__XXX
 SG_ Hvsp9HghstCllVltgCllNmr : 8|8@1+ (1,0) [0|250] "count" Vector__XXX
 SG_ Hvsp9LwstCllVltgMdlNmr : 16|8@1+ (1,0) [0|250] "count" Vector__XXX
 SG_ Hvsp9LwstCllVltgCllNmr : 24|8@1+ (1,0) [0|250] "count" Vector__XXX

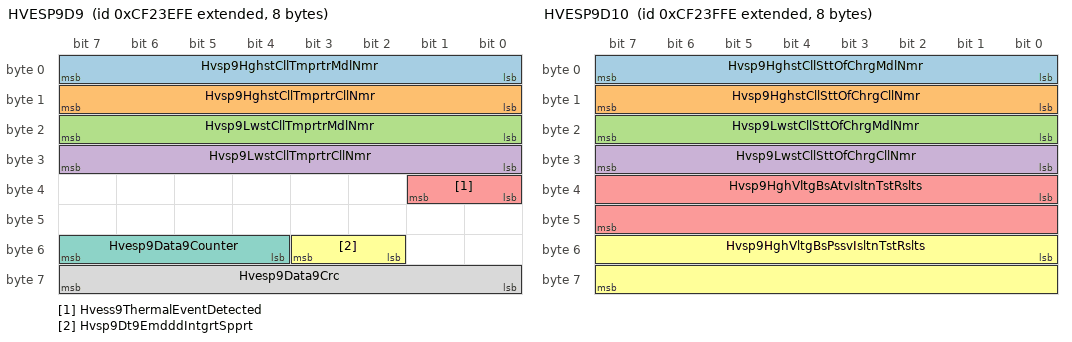
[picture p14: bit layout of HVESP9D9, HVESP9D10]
BO_ 2364686078 HVESP9D9: 8 Vector__XXX
 SG_ Hvsp9HghstCllTmprtrMdlNmr : 0|8@1+ (1,0) [0|250] "count" Vector__XXX
 SG_ Hvsp9HghstCllTmprtrCllNmr : 8|8@1+ (1,0) [0|250] "count" Vector__XXX
 SG_ Hvsp9LwstCllTmprtrMdlNmr : 16|8@1+ (1,0) [0|250] "count" Vector__XXX
 SG_ Hvsp9LwstCllTmprtrCllNmr : 24|8@1+ (1,0) [0|250] "count" Vector__XXX
 SG_ Hvess9ThermalEventDetected : 32|2@1+ (1,0) [0|3] "" Vector__XXX
 SG_ Hvsp9Dt9EmdddIntgrtSpprt : 50|2@1+ (1,0) [0|3] "" Vector__XXX
 SG_ Hvesp9Data9Counter : 52|4@1+ (1,0) [0|15] "" Vector__XXX
 SG_ Hvesp9Data9Crc : 56|8@1+ (1,0) [0|250] "count" Vector__XXX

BO_ 2364686334 HVESP9D10: 8 Vector__XXX
 SG_ Hvsp9HghstCllSttOfChrgMdlNmr : 0|8@1+ (1,0) [0|250] "count" Vector__XXX
 SG_ Hvsp9HghstCllSttOfChrgCllNmr : 8|8@1+ (1,0) [0|250] "count" Vector__XXX
 SG_ Hvsp9LwstCllSttOfChrgMdlNmr : 16|8@1+ (1,0) [0|250] "count" Vector__XXX
 SG_ Hvsp9LwstCllSttOfChrgCllNmr : 24|8@1+ (1,0) [0|250] "count" Vector__XXX
 SG_ Hvsp9HghVltgBsAtvIsltnTstRslts : 32|16@1+ (0.1,0) [0|6425.5] "OhmPerV" Vector__XXX
 SG_ Hvsp9HghVltgBsPssvIsltnTstRslts : 48|16@1+ (0.1,0) [0|6425.5] "OhmPerV" Vector__XXX

BO_ 2364686590 HVESP9D11: 8 Vector__XXX
 SG_ Hvesp9ActualChargeRate : 32|16@1+ (0.05,0) [0|3212.75] "kW" Vector__XXX
 SG_ Hvsp9BsVltgNgtvTChsssGrndVltg : 0|16@1+ (0.05,0) [0|3212.75] "V" Vector__XXX
 SG_ Hvsp9VltgLvlNgtvTChsssGrndVltg : 16|16@1+ (0.05,0) [0|3212.75] "V" Vector__XXX

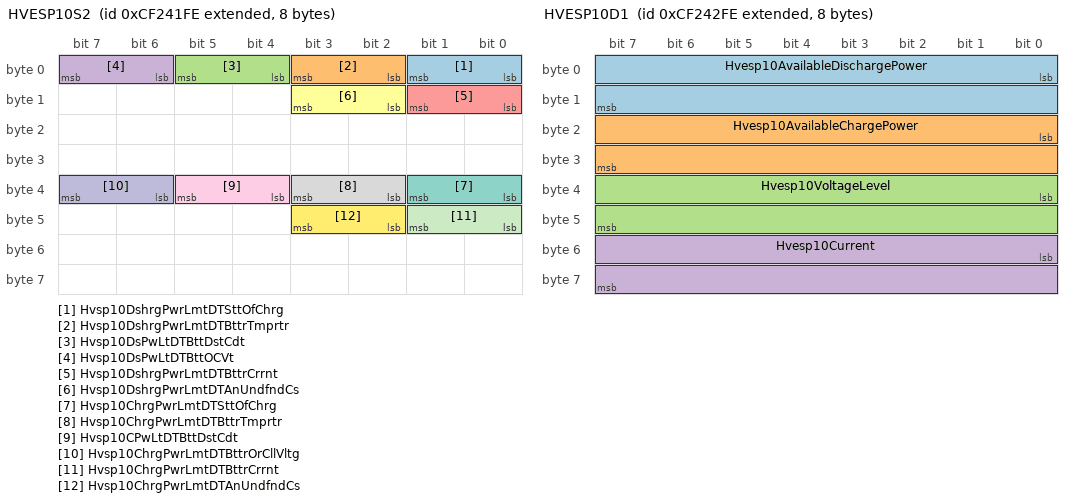
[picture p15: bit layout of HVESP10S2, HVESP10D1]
BO_ 2364686846 HVESP10S2: 8 Vector__XXX
 SG_ Hvsp10DshrgPwrLmtDTSttOfChrg : 0|2@1+ (1,0) [0|3] "" Vector__XXX
 SG_ Hvsp10DshrgPwrLmtDTBttrTmprtr : 2|2@1+ (1,0) [0|3] "" Vector__XXX
 SG_ Hvsp10DsPwLtDTBttDstCdt : 4|2@1+ (1,0) [0|3] "" Vector__XXX
 SG_ Hvsp10DsPwLtDTBttOCVt : 6|2@1+ (1,0) [0|3] "" Vector__XXX
 SG_ Hvsp10DshrgPwrLmtDTBttrCrrnt : 8|2@1+ (1,0) [0|3] "" Vector__XXX
 SG_ Hvsp10DshrgPwrLmtDTAnUndfndCs : 10|2@1+ (1,0) [0|3] "" Vector__XXX
 SG_ Hvsp10ChrgPwrLmtDTSttOfChrg : 32|2@1+ (1,0) [0|3] "" Vector__XXX
 SG_ Hvsp10ChrgPwrLmtDTBttrTmprtr : 34|2@1+ (1,0) [0|3] "" Vector__XXX
 SG_ Hvsp10CPwLtDTBttDstCdt : 36|2@1+ (1,0) [0|3] "" Vector__XXX
 SG_ Hvsp10ChrgPwrLmtDTBttrOrCllVltg : 38|2@1+ (1,0) [0|3] "" Vector__XXX
 SG_ Hvsp10ChrgPwrLmtDTBttrCrrnt : 40|2@1+ (1,0) [0|3] "" Vector__XXX
 SG_ Hvsp10ChrgPwrLmtDTAnUndfndCs : 42|2@1+ (1,0) [0|3] "" Vector__XXX

BO_ 2364687102 HVESP10D1: 8 Vector__XXX
 SG_ Hvesp10AvailableDischargePower : 0|16@1+ (0.05,0) [0|3212.75] "kW" Vector__XXX
 SG_ Hvesp10AvailableChargePower : 16|16@1+ (0.05,0) [0|3212.75] "kW" Vector__XXX
 SG_ Hvesp10VoltageLevel : 32|16@1+ (0.05,0) [0|3212.75] "V" Vector__XXX
 SG_ Hvesp10Current : 48|16@1+ (0.05,-1600) [-1600|1612.75] "A" Vector__XXX

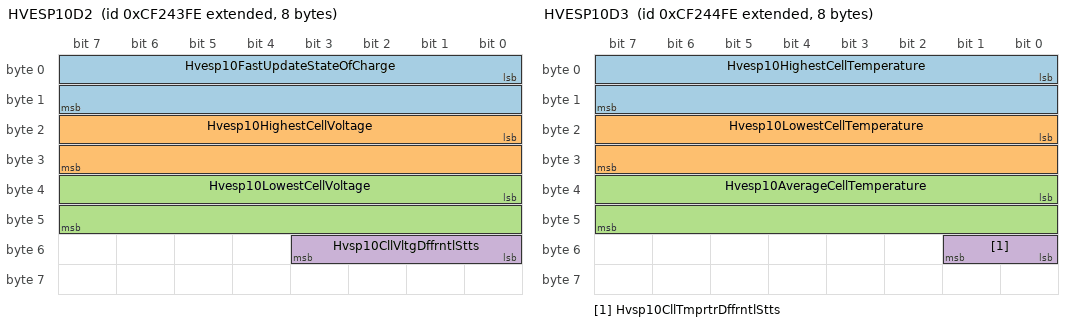
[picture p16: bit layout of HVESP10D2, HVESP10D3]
BO_ 2364687358 HVESP10D2: 8 Vector__XXX
 SG_ Hvesp10FastUpdateStateOfCharge : 0|16@1+ (0.0015625,0) [0|100.3984375] "%" Vector__XXX
 SG_ Hvesp10HighestCellVoltage : 16|16@1+ (0.001,0) [0|64.255] "V" Vector__XXX
 SG_ Hvesp10LowestCellVoltage : 32|16@1+ (0.001,0) [0|64.255] "V" Vector__XXX
 SG_ Hvsp10CllVltgDffrntlStts : 48|4@1+ (1,0) [0|15] "" Vector__XXX

BO_ 2364687614 HVESP10D3: 8 Vector__XXX
 SG_ Hvesp10HighestCellTemperature : 0|16@1+ (0.03125,-273) [-273|1734.96875] "degC" Vector__XXX
 SG_ Hvesp10LowestCellTemperature : 16|16@1+ (0.03125,-273) [-273|1734.96875] "degC" Vector__XXX
 SG_ Hvesp10AverageCellTemperature : 32|16@1+ (0.03125,-273) [-273|1734.96875] "degC" Vector__XXX
 SG_ Hvsp10CllTmprtrDffrntlStts : 48|2@1+ (1,0) [0|3] "" Vector__XXX

BO_ 2364687870 HVESP10D4: 8 Vector__XXX
 SG_ Hvesp10DischargeCapacity : 0|16@1+ (0.01,0) [0|642.55] "Ah" Vector__XXX
 SG_ Hvesp10ChargeCapacity : 16|16@1+ (0.01,0) [0|642.55] "Ah" Vector__XXX
 SG_ Hvesp10CellBalancingCount : 32|16@1+ (1,0) [0|64255] "count" Vector__XXX

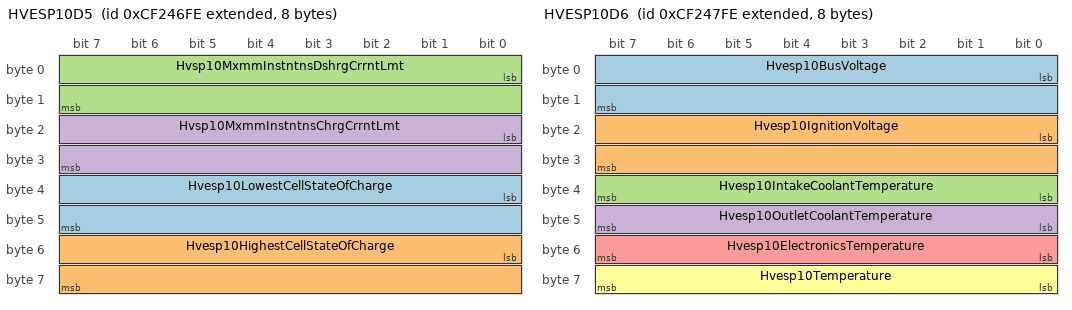
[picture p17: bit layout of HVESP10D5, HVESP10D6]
BO_ 2364688126 HVESP10D5: 8 Vector__XXX
 SG_ Hvesp10LowestCellStateOfCharge : 32|16@1+ (0.0015625,0) [0|100.3984375] "%" Vector__XXX
 SG_ Hvesp10HighestCellStateOfCharge : 48|16@1+ (0.0015625,0) [0|100.3984375] "%" Vector__XXX
 SG_ Hvsp10MxmmInstntnsDshrgCrrntLmt : 0|16@1+ (0.05,-1600) [-1600|0] "A" Vector__XXX
 SG_ Hvsp10MxmmInstntnsChrgCrrntLmt : 16|16@1+ (0.05,-1600) [0|1612.75] "A" Vector__XXX

BO_ 2364688382 HVESP10D6: 8 Vector__XXX
 SG_ Hvesp10BusVoltage : 0|16@1+ (0.05,0) [0|3212.75] "V" Vector__XXX
 SG_ Hvesp10IgnitionVoltage : 16|16@1+ (0.01,0) [0|642.55] "V" Vector__XXX
 SG_ Hvesp10IntakeCoolantTemperature : 32|8@1+ (1,-40) [-40|210] "degC" Vector__XXX
 SG_ Hvesp10OutletCoolantTemperature : 40|8@1+ (1,-40) [-40|210] "degC" Vector__XXX
 SG_ Hvesp10ElectronicsTemperature : 48|8@1+ (1,-40) [-40|210] "degC" Vector__XXX
 SG_ Hvesp10Temperature : 56|8@1+ (1,-40) [-40|210] "degC" Vector__XXX

BO_ 2364688638 HVESP10S1: 8 Vector__XXX
 SG_ Hvesp10HvilStatus : 20|2@1+ (1,0) [0|3] "" Vector__XXX
 SG_ Hvesp10InertiaSwitchStatus : 22|2@1+ (1,0) [0|3] "" Vector__XXX
 SG_ Hvesp10StateOfChargeStatus : 24|4@1+ (1,0) [0|15] "" Vector__XXX
 SG_ Hvesp10CellBalanceStatus : 28|2@1+ (1,0) [0|3] "" Vector__XXX
 SG_ Hvesp10CellBalancingActive : 30|2@1+ (1,0) [0|3] "" Vector__XXX
 SG_ Hvesp10InternalChargerStatus : 32|2@1+ (1,0) [0|3] "" Vector__XXX
 SG_ Hvesp10OperationalStatus : 44|4@1+ (1,0) [0|15] "" Vector__XXX
 SG_ Hvesp10Status1Counter : 52|4@1+ (1,0) [0|15] "" Vector__XXX
 SG_ Hvesp10Status1Crc : 56|8@1+ (1,0) [0|250] "count" Vector__XXX
 SG_ Hvsp10HghVltgBsPstvCnttrStt : 0|2@1+ (1,0) [0|3] "" Vector__XXX
 SG_ Hvsp10HghVltgBsNgtvCnttrStt : 2|2@1+ (1,0) [0|3] "" Vector__XXX
 SG_ Hvsp10HghVltgBsDsnntFrwrnng : 4|4@1+ (1,0) [0|15] "" Vector__XXX
 SG_ Hvsp10HghVltgBsPrChrgRlStt : 8|2@1+ (1,0) [0|3] "" Vector__XXX
 SG_ Hvsp10CntrOfPkCnttrStt : 10|2@1+ (1,0) [0|3] "" Vector__XXX
 SG_ Hvsp10HghVltgBsAtvIsltnTstStts : 12|4@1+ (1,0) [0|15] "" Vector__XXX
 SG_ Hvsp10HghVltgBsPssvIsltnTstStts : 16|4@1+ (1,0) [0|15] "" Vector__XXX
 SG_ Hvsp10HghVltgBsCnntnStts : 40|4@1+ (1,0) [0|15] "" Vector__XXX

BO_ 2364688894 HVESP10D7: 8 Vector__XXX
 SG_ Hvesp10DischargeEnergyCapacity : 0|24@1+ (0.001,0) [0|16449.535] "kWh" Vector__XXX
 SG_ Hvesp10ChargeEnergyCapacity : 24|24@1+ (0.001,0) [0|16449.535] "kWh" Vector__XXX
 SG_ Hvsp10MxmmChrgVltgLmt : 48|16@1+ (0.05,0) [0|3212.75] "V" Vector__XXX

BO_ 2364689150 HVESP10MS1: 8 Vector__XXX
 SG_ Hvesp10Module1OperationalStatus : 0|2@1+ (1,0) [0|3] "" Vector__XXX
 SG_ Hvesp10Module2OperationalStatus : 2|2@1+ (1,0) [0|3] "" Vector__XXX
 SG_ Hvesp10Module3OperationalStatus : 4|2@1+ (1,0) [0|3] "" Vector__XXX
 SG_ Hvesp10Module4OperationalStatus : 6|2@1+ (1,0) [0|3] "" Vector__XXX
 SG_ Hvesp10Module5OperationalStatus : 8|2@1+ (1,0) [0|3] "" Vector__XXX
 SG_ Hvesp10Module6OperationalStatus : 10|2@1+ (1,0) [0|3] "" Vector__XXX
 SG_ Hvesp10Module7OperationalStatus : 12|2@1+ (1,0) [0|3] "" Vector__XXX
 SG_ Hvesp10Module8OperationalStatus : 14|2@1+ (1,0) [0|3] "" Vector__XXX
 SG_ Hvesp10Module9OperationalStatus : 16|2@1+ (1,0) [0|3] "" Vector__XXX
 SG_ Hvsp10Mdl10OprtnlStts : 18|2@1+ (1,0) [0|3] "" Vector__XXX
 SG_ Hvsp10Mdl11OprtnlStts : 20|2@1+ (1,0) [0|3] "" Vector__XXX
 SG_ Hvsp10Mdl12OprtnlStts : 22|2@1+ (1,0) [0|3] "" Vector__XXX
 SG_ Hvsp10Mdl13OprtnlStts : 24|2@1+ (1,0) [0|3] "" Vector__XXX
 SG_ Hvsp10Mdl14OprtnlStts : 26|2@1+ (1,0) [0|3] "" Vector__XXX
 SG_ Hvsp10Mdl15OprtnlStts : 28|2@1+ (1,0) [0|3] "" Vector__XXX
 SG_ Hvsp10Mdl16OprtnlStts : 30|2@1+ (1,0) [0|3] "" Vector__XXX
 SG_ Hvsp10Mdl17OprtnlStts : 32|2@1+ (1,0) [0|3] "" Vector__XXX
 SG_ Hvsp10Mdl18OprtnlStts : 34|2@1+ (1,0) [0|3] "" Vector__XXX
 SG_ Hvsp10Mdl19OprtnlStts : 36|2@1+ (1,0) [0|3] "" Vector__XXX
 SG_ Hvsp10Mdl20OprtnlStts : 38|2@1+ (1,0) [0|3] "" Vector__XXX
 SG_ Hvsp10Mdl21OprtnlStts : 40|2@1+ (1,0) [0|3] "" Vector__XXX
 SG_ Hvsp10Mdl22OprtnlStts : 42|2@1+ (1,0) [0|3] "" Vector__XXX
 SG_ Hvsp10Mdl23OprtnlStts : 44|2@1+ (1,0) [0|3] "" Vector__XXX
 SG_ Hvsp10Mdl24OprtnlStts : 46|2@1+ (1,0) [0|3] "" Vector__XXX
 SG_ Hvsp10Mdl25OprtnlStts : 48|2@1+ (1,0) [0|3] "" Vector__XXX
 SG_ Hvsp10Mdl26OprtnlStts : 50|2@1+ (1,0) [0|3] "" Vector__XXX
 SG_ Hvsp10Mdl27OprtnlStts : 52|2@1+ (1,0) [0|3] "" Vector__XXX
 SG_ Hvsp10Mdl28OprtnlStts : 54|2@1+ (1,0) [0|3] "" Vector__XXX
 SG_ Hvsp10Mdl29OprtnlStts : 56|2@1+ (1,0) [0|3] "" Vector__XXX
 SG_ Hvsp10Mdl30OprtnlStts : 58|2@1+ (1,0) [0|3] "" Vector__XXX
 SG_ Hvsp10Mdl31OprtnlStts : 60|2@1+ (1,0) [0|3] "" Vector__XXX
 SG_ Hvsp10Mdl32OprtnlStts : 62|2@1+ (1,0) [0|3] "" Vector__XXX

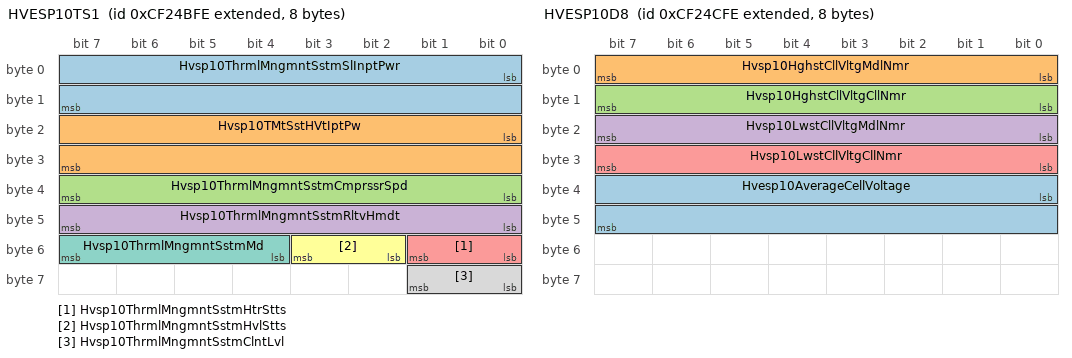
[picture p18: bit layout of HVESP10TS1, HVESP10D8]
BO_ 2364689406 HVESP10TS1: 8 Vector__XXX
 SG_ Hvsp10ThrmlMngmntSstmSlInptPwr : 0|16@1+ (0.5,0) [0|32127.5] "W" Vector__XXX
 SG_ Hvsp10TMtSstHVtIptPw : 16|16@1+ (0.5,0) [0|32127.5] "W" Vector__XXX
 SG_ Hvsp10ThrmlMngmntSstmCmprssrSpd : 32|8@1+ (32,0) [0|8000] "rpm" Vector__XXX
 SG_ Hvsp10ThrmlMngmntSstmRltvHmdt : 40|8@1+ (0.4,0) [0|100] "%" Vector__XXX
 SG_ Hvsp10ThrmlMngmntSstmHtrStts : 48|2@1+ (1,0) [0|3] "" Vector__XXX
 SG_ Hvsp10ThrmlMngmntSstmHvlStts : 50|2@1+ (1,0) [0|3] "" Vector__XXX
 SG_ Hvsp10ThrmlMngmntSstmMd : 52|4@1+ (1,0) [0|15] "" Vector__XXX
 SG_ Hvsp10ThrmlMngmntSstmClntLvl : 56|2@1+ (1,0) [0|3] "" Vector__XXX

BO_ 2364689662 HVESP10D8: 8 Vector__XXX
 SG_ Hvesp10AverageCellVoltage : 32|16@1+ (0.001,0) [0|64.255] "V" Vector__XXX
 SG_ Hvsp10HghstCllVltgMdlNmr : 0|8@1+ (1,0) [0|250] "count" Vector__XXX
 SG_ Hvsp10HghstCllVltgCllNmr : 8|8@1+ (1,0) [0|250] "count" Vector__XXX
 SG_ Hvsp10LwstCllVltgMdlNmr : 16|8@1+ (1,0) [0|250] "count" Vector__XXX
 SG_ Hvsp10LwstCllVltgCllNmr : 24|8@1+ (1,0) [0|250] "count" Vector__XXX

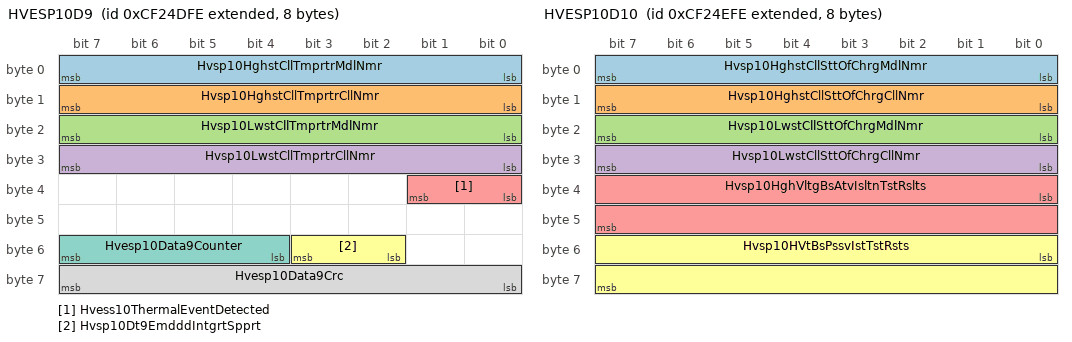
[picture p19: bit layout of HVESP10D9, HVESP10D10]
BO_ 2364689918 HVESP10D9: 8 Vector__XXX
 SG_ Hvsp10HghstCllTmprtrMdlNmr : 0|8@1+ (1,0) [0|250] "count" Vector__XXX
 SG_ Hvsp10HghstCllTmprtrCllNmr : 8|8@1+ (1,0) [0|250] "count" Vector__XXX
 SG_ Hvsp10LwstCllTmprtrMdlNmr : 16|8@1+ (1,0) [0|250] "count" Vector__XXX
 SG_ Hvsp10LwstCllTmprtrCllNmr : 24|8@1+ (1,0) [0|250] "count" Vector__XXX
 SG_ Hvess10ThermalEventDetected : 32|2@1+ (1,0) [0|3] "" Vector__XXX
 SG_ Hvsp10Dt9EmdddIntgrtSpprt : 50|2@1+ (1,0) [0|3] "" Vector__XXX
 SG_ Hvesp10Data9Counter : 52|4@1+ (1,0) [0|15] "" Vector__XXX
 SG_ Hvesp10Data9Crc : 56|8@1+ (1,0) [0|250] "count" Vector__XXX

BO_ 2364690174 HVESP10D10: 8 Vector__XXX
 SG_ Hvsp10HghstCllSttOfChrgMdlNmr : 0|8@1+ (1,0) [0|250] "count" Vector__XXX
 SG_ Hvsp10HghstCllSttOfChrgCllNmr : 8|8@1+ (1,0) [0|250] "count" Vector__XXX
 SG_ Hvsp10LwstCllSttOfChrgMdlNmr : 16|8@1+ (1,0) [0|250] "count" Vector__XXX
 SG_ Hvsp10LwstCllSttOfChrgCllNmr : 24|8@1+ (1,0) [0|250] "count" Vector__XXX
 SG_ Hvsp10HghVltgBsAtvIsltnTstRslts : 32|16@1+ (0.1,0) [0|6425.5] "OhmPerV" Vector__XXX
 SG_ Hvsp10HVtBsPssvIstTstRsts : 48|16@1+ (0.1,0) [0|6425.5] "OhmPerV" Vector__XXX

BO_ 2364690430 HVESP10D11: 8 Vector__XXX
 SG_ Hvesp10ActualChargeRate : 32|16@1+ (0.05,0) [0|3212.75] "kW" Vector__XXX
 SG_ Hvsp10BsVltgNgtvTChsssGrndVltg : 0|16@1+ (0.05,0) [0|3212.75] "V" Vector__XXX
 SG_ Hvsp10VltgLvlNgtvTChsssGrndVltg : 16|16@1+ (0.05,0) [0|3212.75] "V" Vector__XXX

BO_ 2566564862 HVESP10CFG: 19 Vector__XXX
 SG_ Hvesp10NominalVoltage : 0|16@1+ (0.05,0) [0|3212.75] "V" Vector__XXX
 SG_ Hvesp10CellMaximumVoltageLimit : 112|8@1+ (0.02044,0) [0|5.11] "V" Vector__XXX
 SG_ Hvesp10CellMinimumVoltageLimit : 120|8@1+ (0.02044,0) [0|5.11] "V" Vector__XXX
 SG_ Hvsp10RmmnddMnmmOprtngVltg : 16|16@1+ (0.05,0) [0|3212.75] "V" Vector__XXX
 SG_ Hvsp10RmmnddMxmmOprtngVltg : 32|16@1+ (0.05,0) [0|3212.75] "V" Vector__XXX
 SG_ Hvsp10RmmnddMnmmSttOfChrg : 48|16@1+ (0.0015625,0) [0|100.3984375] "%" Vector__XXX
 SG_ Hvsp10RmmnddMxmmSttOfChrg : 64|16@1+ (0.0015625,0) [0|100.3984375] "%" Vector__XXX
 SG_ Hvsp10RmmnddMxmmOprtngTmprtr : 80|16@1+ (0.03125,-273) [-273|1734.96875] "degC" Vector__XXX
 SG_ Hvsp10RmmnddMnmmOprtngTmprtr : 96|16@1+ (0.03125,-273) [-273|1734.96875] "degC" Vector__XXX

BO_ 2633673982 HVESP10HIST: 19 Vector__XXX
 SG_ Hvesp10StateOfHealth : 0|8@1+ (0.4,0) [0|100] "%" Vector__XXX
 SG_ Hvesp10TotalEnergyThroughput : 24|32@1+ (100,0) [0|421108121500] "Watt-hour" Vector__XXX
 SG_ Hvesp10TotalAccumulatedCharge : 56|32@1+ (100,0) [0|421108121500] "Ah" Vector__XXX
 SG_ Hvesp10TotalLifetimeEnergyInput : 88|32@1+ (1,0) [0|4211081215] "kWh" Vector__XXX
 SG_ Hvsp10CnttrOpnUndrLdCnt : 8|16@1+ (1,0) [0|64255] "count" Vector__XXX
 SG_ Hvsp10TtlLftmEnrgOtpt : 120|32@1+ (1,0) [0|4211081215] "kWh" Vector__XXX

CM_ BO_ 2364677630 "High Voltage Energy Storage Pack 7 Module Status 1";
CM_ SG_ 2364677630 Hvesp7Module1OperationalStatus "HVESP7 Module 1 Operational Status: Operational Status of Module 1 in this High Voltage Energy Storage Pack Instance.  Not Operational is used when the module is initializing or not able to function (e.g. internal module level monitors have failed). ...";
CM_ SG_ 2364677630 Hvesp7Module2OperationalStatus "HVESP7 Module 2 Operational Status: Operational Status of Module 2 in this High Voltage Energy Storage Pack Instance.  Not Operational is used when the module is initializing or not able to function (e.g. internal module level monitors have failed). ...";
CM_ SG_ 2364677630 Hvesp7Module3OperationalStatus "HVESP7 Module 3 Operational Status: Operational Status of Module 3 in this High Voltage Energy Storage Pack Instance.  Not Operational is used when the module is initializing or not able to function (e.g. internal module level monitors have failed). ...";
CM_ SG_ 2364677630 Hvesp7Module4OperationalStatus "HVESP7 Module 4 Operational Status: Operational Status of Module 4 in this High Voltage Energy Storage Pack Instance.  Not Operational is used when the module is initializing or not able to function (e.g. internal module level monitors have failed). ...";
CM_ SG_ 2364677630 Hvesp7Module5OperationalStatus "HVESP7 Module 5 Operational Status: Operational Status of Module 5 in this High Voltage Energy Storage Pack Instance.  Not Operational is used when the module is initializing or not able to function (e.g. internal module level monitors have failed). ...";
CM_ SG_ 2364677630 Hvesp7Module6OperationalStatus "HVESP7 Module 6 Operational Status: Operational Status of Module 6 in this High Voltage Energy Storage Pack Instance.  Not Operational is used when the module is initializing or not able to function (e.g. internal module level monitors have failed). ...";
CM_ SG_ 2364677630 Hvesp7Module7OperationalStatus "HVESP7 Module 7 Operational Status: Operational Status of Module 7 in this High Voltage Energy Storage Pack Instance.  Not Operational is used when the module is initializing or not able to function (e.g. internal module level monitors have failed). ...";
CM_ SG_ 2364677630 Hvesp7Module8OperationalStatus "HVESP7 Module 8 Operational Status: Operational Status of Module 8 in this High Voltage Energy Storage Pack Instance.  Not Operational is used when the module is initializing or not able to function (e.g. internal module level monitors have failed). ...";
CM_ SG_ 2364677630 Hvesp7Module9OperationalStatus "HVESP7 Module 9 Operational Status: Operational Status of Module 9 in this High Voltage Energy Storage Pack Instance.  Not Operational is used when the module is initializing or not able to function (e.g. internal module level monitors have failed). ...";
CM_ SG_ 2364677630 Hvesp7Module10OperationalStatus "HVESP7 Module 10 Operational Status: Operational Status of Module 10 in this High Voltage Energy Storage Pack Instance.  Not Operational is used when the module is initializing or not able to function (e.g. internal module level monitors have failed)...";
CM_ SG_ 2364677630 Hvesp7Module11OperationalStatus "HVESP7 Module 11 Operational Status: Operational Status of Module 11 in this High Voltage Energy Storage Pack Instance.  Not Operational is used when the module is initializing or not able to function (e.g. internal module level monitors have failed)...";
CM_ SG_ 2364677630 Hvesp7Module12OperationalStatus "HVESP7 Module 12 Operational Status: Operational Status of Module 12 in this High Voltage Energy Storage Pack Instance.  Not Operational is used when the module is initializing or not able to function (e.g. internal module level monitors have failed)...";
CM_ SG_ 2364677630 Hvesp7Module13OperationalStatus "HVESP7 Module 13 Operational Status: Operational Status of Module 13 in this High Voltage Energy Storage Pack Instance.  Not Operational is used when the module is initializing or not able to function (e.g. internal module level monitors have failed)...";
CM_ SG_ 2364677630 Hvesp7Module14OperationalStatus "HVESP7 Module 14 Operational Status: Operational Status of Module 14 in this High Voltage Energy Storage Pack Instance.  Not Operational is used when the module is initializing or not able to function (e.g. internal module level monitors have failed)...";
CM_ SG_ 2364677630 Hvesp7Module15OperationalStatus "HVESP7 Module 15 Operational Status: Operational Status of Module 15 in this High Voltage Energy Storage Pack Instance.  Not Operational is used when the module is initializing or not able to function (e.g. internal module level monitors have failed)...";
CM_ SG_ 2364677630 Hvesp7Module16OperationalStatus "HVESP7 Module 16 Operational Status: Operational Status of Module 16 in this High Voltage Energy Storage Pack Instance.  Not Operational is used when the module is initializing or not able to function (e.g. internal module level monitors have failed)...";
CM_ SG_ 2364677630 Hvesp7Module17OperationalStatus "HVESP7 Module 17 Operational Status: Operational Status of Module 17 in this High Voltage Energy Storage Pack Instance.  Not Operational is used when the module is initializing or not able to function (e.g. internal module level monitors have failed)...";
CM_ SG_ 2364677630 Hvesp7Module18OperationalStatus "HVESP7 Module 18 Operational Status: Operational Status of Module 18 in this High Voltage Energy Storage Pack Instance.  Not Operational is used when the module is initializing or not able to function (e.g. internal module level monitors have failed)...";
CM_ SG_ 2364677630 Hvesp7Module19OperationalStatus "HVESP7 Module 19 Operational Status: Operational Status of Module 19 in this High Voltage Energy Storage Pack Instance.  Not Operational is used when the module is initializing or not able to function (e.g. internal module level monitors have failed)...";
CM_ SG_ 2364677630 Hvesp7Module20OperationalStatus "HVESP7 Module 20 Operational Status: Operational Status of Module 20 in this High Voltage Energy Storage Pack Instance.  Not Operational is used when the module is initializing or not able to function (e.g. internal module level monitors have failed)...";
CM_ SG_ 2364677630 Hvesp7Module21OperationalStatus "HVESP7 Module 21 Operational Status: Operational Status of Module 21 in this High Voltage Energy Storage Pack Instance.  Not Operational is used when the module is initializing or not able to function (e.g. internal module level monitors have failed)...";
CM_ SG_ 2364677630 Hvesp7Module22OperationalStatus "HVESP7 Module 22 Operational Status: Operational Status of Module 22 in this High Voltage Energy Storage Pack Instance.  Not Operational is used when the module is initializing or not able to function (e.g. internal module level monitors have failed)...";
CM_ SG_ 2364677630 Hvesp7Module23OperationalStatus "HVESP7 Module 23 Operational Status: Operational Status of Module 23 in this High Voltage Energy Storage Pack Instance.  Not Operational is used when the module is initializing or not able to function (e.g. internal module level monitors have failed)...";
CM_ SG_ 2364677630 Hvesp7Module24OperationalStatus "HVESP7 Module 24 Operational Status: Operational Status of Module 24 in this High Voltage Energy Storage Pack Instance.  Not Operational is used when the module is initializing or not able to function (e.g. internal module level monitors have failed)...";
CM_ SG_ 2364677630 Hvesp7Module25OperationalStatus "HVESP7 Module 25 Operational Status: Operational Status of Module 25 in this High Voltage Energy Storage Pack Instance.  Not Operational is used when the module is initializing or not able to function (e.g. internal module level monitors have failed)...";
CM_ SG_ 2364677630 Hvesp7Module26OperationalStatus "HVESP7 Module 26 Operational Status: Operational Status of Module 26 in this High Voltage Energy Storage Pack Instance.  Not Operational is used when the module is initializing or not able to function (e.g. internal module level monitors have failed)...";
CM_ SG_ 2364677630 Hvesp7Module27OperationalStatus "HVESP7 Module 27 Operational Status: Operational Status of Module 27 in this High Voltage Energy Storage Pack Instance.  Not Operational is used when the module is initializing or not able to function (e.g. internal module level monitors have failed)...";
CM_ SG_ 2364677630 Hvesp7Module28OperationalStatus "HVESP7 Module 28 Operational Status: Operational Status of Module 28 in this High Voltage Energy Storage Pack Instance.  Not Operational is used when the module is initializing or not able to function (e.g. internal module level monitors have failed)...";
CM_ SG_ 2364677630 Hvesp7Module29OperationalStatus "HVESP7 Module 29 Operational Status: Operational Status of Module 29 in this High Voltage Energy Storage Pack Instance.  Not Operational is used when the module is initializing or not able to function (e.g. internal module level monitors have failed)...";
CM_ SG_ 2364677630 Hvesp7Module30OperationalStatus "HVESP7 Module 30 Operational Status: Operational Status of Module 30 in this High Voltage Energy Storage Pack Instance.  Not Operational is used when the module is initializing or not able to function (e.g. internal module level monitors have failed)...";
CM_ SG_ 2364677630 Hvesp7Module31OperationalStatus "HVESP7 Module 31 Operational Status: Operational Status of Module 31 in this High Voltage Energy Storage Pack Instance.  Not Operational is used when the module is initializing or not able to function (e.g. internal module level monitors have failed)...";
CM_ SG_ 2364677630 Hvesp7Module32OperationalStatus "HVESP7 Module 32 Operational Status: Operational Status of Module 32 in this High Voltage Energy Storage Pack Instance.  Not Operational is used when the module is initializing or not able to function (e.g. internal module level monitors have failed)...";
CM_ BO_ 2364677886 "High Voltage Energy Storage Pack 7 Thermal Management System Status 1";
CM_ SG_ 2364677886 Hvsp7ThrmlMngmntSstmSlInptPwr "HVESP7 Thermal Management System SLI Input Power: This is the low-voltage power consumed by this HVES Thermal Management System (TMS).This parameter is for one of multiple packs in an HVESS.  If there is only one pack in the system, the HVESS paramet...";
CM_ SG_ 2364677886 Hvsp7TMtSstHVtIptPw "HVESP7 Thermal Management System High-Voltage Input Power: This is the high-voltage power consumed by this HVES Thermal Management System (TMS).This parameter is for one of multiple packs in an HVESS.  If there is only one pack in the system, the HVE...";
CM_ SG_ 2364677886 Hvsp7ThrmlMngmntSstmCmprssrSpd "HVESP7 Thermal Management System Compressor Speed: When this High Voltage Energy Storage Pack Thermal Management System is equipped with an active cooling system (e.g. air conditioner), this is the Compressor Speed.This parameter is for one of multip...";
CM_ SG_ 2364677886 Hvsp7ThrmlMngmntSstmRltvHmdt "HVESP7 Thermal Management System Relative Humidty: When this High Voltage Energy Storage Pack Thermal Management System is equipped with a relative humidity sensor, this is the  measured Relative Humidity.This parameter is for one of multiple packs i...";
CM_ SG_ 2364677886 Hvsp7ThrmlMngmntSstmHtrStts "HVESP7 Thermal Management System Heater Status: The state of this High Voltage Energy Storage Pack heaterThis parameter is for one of multiple packs in an HVESS.  If there is only one pack in the system, the HVESS parameters should be used. If there ...";
CM_ SG_ 2364677886 Hvsp7ThrmlMngmntSstmHvlStts "HVESP7 Thermal Management System HVIL Status: In multiple HVES configurations, this is the status of the High Voltage Interlock Loop from the viewpoint of this Thermal Management System.00b = HVIL Closed01b = HVIL Open10b = Error11b = Not AvailableTh...";
CM_ SG_ 2364677886 Hvsp7ThrmlMngmntSstmMd "HVESP7 Thermal Management System Mode: Indicates the operating mode of the Thermal Management System.  The heat transfer medium may be (e.g. liquid or air).  The cooling system may be fans, liquid coolant, or a combination of mediums.  The system may...";
CM_ SG_ 2364677886 Hvsp7ThrmlMngmntSstmClntLvl "HVESP7 Thermal Management System Coolant Level: Indicates the coolant level in this HVES Thermal Management System (TMS).This parameter is for one of multiple packs in an HVESS.  If there is only one pack in the system, the HVESS parameters should be...";
CM_ BO_ 2364678142 "High Voltage Energy Storage Pack 7 Data 8";
CM_ SG_ 2364678142 Hvesp7AverageCellVoltage "HVESP7 Average Cell Voltage: The average cell voltage in this High Voltage Energy Storage Pack instance.This parameter is for one of multiple packs in an HVESS.  If there is only one pack in the system, the HVESS parameters should be used. If there a...";
CM_ SG_ 2364678142 Hvsp7HghstCllVltgMdlNmr "HVESP7 Highest Cell Voltage Module Number: Identifies the location of the module containing SPN 14065 (HVESP7 Highest Cell Voltage).This parameter is for one of multiple packs in an HVESS. If there is only one pack in the system, the HVESS parameters...";
CM_ SG_ 2364678142 Hvsp7HghstCllVltgCllNmr "HVESP7 Highest Cell Voltage Cell Number: Identifies the location of SPN 14065 (HVESP7 Highest Cell Voltage) within SPN 14145 (HVESP7 Highest Cell Voltage Module Number).This parameter is for one of multiple packs in an HVESS. If there is only one pac...";
CM_ SG_ 2364678142 Hvsp7LwstCllVltgMdlNmr "HVESP7 Lowest Cell Voltage Module Number: Identifies the location of the module containing SPN 14066 (HVESP7 Lowest Cell Voltage).This parameter is for one of multiple packs in an HVESS. If there is only one pack in the system, the HVESS parameters s...";
CM_ SG_ 2364678142 Hvsp7LwstCllVltgCllNmr "HVESP7 Lowest Cell Voltage Cell Number: Identifies the location of SPN 14066 (HVESP7 Lowest Cell Voltage) within SPN 14147 (HVESP7 Lowest Cell Voltage Module Number).This parameter is for one of multiple packs in an HVESS. If there is only one pack i...";
CM_ BO_ 2364678398 "High Voltage Energy Storage Pack 7 Data 9";
CM_ SG_ 2364678398 Hvsp7HghstCllTmprtrMdlNmr "HVESP7 Highest Cell Temperature Module Number: Identifies the location of the module containing SPN 14068 (HVESP7 Highest Cell Temperature).This parameter is for one of multiple packs in an HVESS. If there is only one pack in the system, the HVESS pa...";
CM_ SG_ 2364678398 Hvsp7HghstCllTmprtrCllNmr "HVESP7 Highest Cell Temperature Cell Number: Identifies the location of SPN 14068 (HVESP7 Highest Cell Temperature) within SPN 14150 (HVESP7 Highest Cell Temperature Module Number).This parameter is for one of multiple packs in an HVESS. If there is ...";
CM_ SG_ 2364678398 Hvsp7LwstCllTmprtrMdlNmr "HVESP7 Lowest Cell Temperature Module Number: Identifies the location of the module containing SPN 14069 (HVESP7 Lowest Cell Temperature).This parameter is for one of multiple packs in an HVESS. If there is only one pack in the system, the HVESS para...";
CM_ SG_ 2364678398 Hvsp7LwstCllTmprtrCllNmr "HVESP7 Lowest Cell Temperature Cell Number: Identifies the location of SPN 14069 (HVESP7 Lowest Cell Temperature) within SPN 14152 (HVESP7 Lowest Cell Temperature Module Number).This parameter is for one of multiple packs in an HVESS. If there is onl...";
CM_ SG_ 2364678398 Hvess7ThermalEventDetected "HVESS7 Thermal Event Detected: A sensor has detected the presence of a thermal event at or near High Voltage Energy Storage Pack instance.00b = No Thermal Event Detected01b = Thermal Event Detected10b = Error11b = Not availableThis parameter is for o...";
CM_ SG_ 2364678398 Hvsp7Dt9EmdddIntgrtSpprt "HVESP7 Data 9 Embedded Integrity Support: Indicates SPN 22994 (HVESP7 Data 9 CRC) and SPN 22993 (HVESP7 Data 9 Counter) are supported by the sender.00b = Embedded CRC and Counter are supported by the sender01b = Protection is provided using an extern...";
CM_ SG_ 2364678398 Hvesp7Data9Counter "HVESP7 Data 9 Counter: The message counter is used to detect situations where the transmitting ECU malfunction repeats the same frame all the time. The receiver of the information may use the counter parameter to detect this situation. The transmitti...";
CM_ SG_ 2364678398 Hvesp7Data9Crc "HVESP7 Data 9 CRC: The CRC is defined as follows: - Length: 8 bits- Polynomial: x^8+x^5+x^3+x^2+x+1- Initial Value: FFh- Input Data Reflection: Not reflected- Result Data Reflection: Not reflected- XOR value: FFh SAE makes no claim of the functional ...";
CM_ BO_ 2364678654 "High Voltage Energy Storage Pack 7 Data 10";
CM_ SG_ 2364678654 Hvsp7HghstCllSttOfChrgMdlNmr "HVESP7 Highest Cell State of Charge Module Number: Identifies the location of the module containing SPN 14078 (HVESP7 Highest Cell State of Charge).This parameter is for one of multiple packs in an HVESS. If there is only one pack in the system, the ...";
CM_ SG_ 2364678654 Hvsp7HghstCllSttOfChrgCllNmr "HVESP7 Highest Cell State of Charge Cell Number: Identifies the location of SPN 14078 (HVESP7 Highest Cell State of Charge) within SPN 14154 (HVESP7 Highest Cell State of Charge Module Number).This parameter is for one of multiple packs in an HVESS. ...";
CM_ SG_ 2364678654 Hvsp7LwstCllSttOfChrgMdlNmr "HVESP7 Lowest Cell State of Charge Module Number: Identifies the location of the module containing SPN 14077 (HVESP7 Lowest Cell State of Charge).This parameter is for one of multiple packs in an HVESS. If there is only one pack in the system, the HV...";
CM_ SG_ 2364678654 Hvsp7LwstCllSttOfChrgCllNmr "HVESP7 Lowest Cell State of Charge Cell Number: Identifies the location of SPN 14077 (HVESP7 Lowest Cell State of Charge) within SPN 14156 (HVESP7 Lowest Cell State of Charge Module Number).This parameter is for one of multiple packs in an HVESS. If ...";
CM_ SG_ 2364678654 Hvsp7HghVltgBsAtvIsltnTstRslts "HVESP7 High-Voltage Bus Active Isolation Test Results: The isolation resistance expressed in Ohms per Volt that resulted from the High-Voltage Bus Active Isolation Test.See SPN 14090 (HVESP7 High-Voltage Bus Active Isolation Test Status) for test sta...";
CM_ SG_ 2364678654 Hvsp7HghVltgBsPssvIsltnTstRslts "HVESP7 High-Voltage Bus Passive Isolation Test Results: The isolation resistance expressed in Ohms per Volt that resulted from the High-Voltage Bus Passive Isolation Test.See SPN 14091 (HVESP7 High-Voltage Bus Passive Isolation Test Status) for test ...";
CM_ BO_ 2364678910 "High Voltage Energy Storage Pack 7 Data 11";
CM_ SG_ 2364678910 Hvesp7ActualChargeRate "HVESP7 Actual Charge Rate: This signal represents the actual present charge rate of this High Voltage Energy Storage Pack instance.This parameter is for one of multiple packs in an HVESS. If there is only one pack in the system, the HVESS parameters ...";
CM_ SG_ 2364678910 Hvsp7BsVltgNgtvTChsssGrndVltg "HVESP7 Bus Voltage Negative to Chassis Ground Voltage: Voltage difference between the most negative terminal of the HVES battery and chassis measured on the hybrid or EV system bus side (not the battery side) of any HVES contained output contactor.  ...";
CM_ SG_ 2364678910 Hvsp7VltgLvlNgtvTChsssGrndVltg "HVESP7 Voltage Level Negative to Chassis Ground Voltage: Voltage difference between the most negative terminal of the HVES battery and chassis measured at the battery side of any HVES contained output contactor.  This voltage may be used for system l...";
CM_ BO_ 2364679166 "High Voltage Energy Storage Pack 8 Status 2";
CM_ SG_ 2364679166 Hvsp8DshrgPwrLmtDTSttOfChrg "HVESP8 Discharge Power Limit Due to State of Charge: Indicates whether or not discharge power of this HVES instance is being limited due to state of charge.This parameter is for one of multiple packs in an HVESS.  If there is only one pack in the sys...";
CM_ SG_ 2364679166 Hvsp8DshrgPwrLmtDTBttrTmprtr "HVESP8 Discharge Power Limit Due to Battery Temperature: Indicates whether or not discharge power of this HVES instance is being limited due to battery temperature.This parameter is for one of multiple packs in an HVESS.  If there is only one pack in...";
CM_ SG_ 2364679166 Hvsp8DsPwLtDTBttDstCdt "HVESP8 Discharge Power Limit Due to Battery Diagnostic Condition: Indicates whether or not discharge power of this HVES instance is being limited due to a battery diagnostic condition.This parameter is for one of multiple packs in an HVESS.  If there...";
CM_ SG_ 2364679166 Hvsp8DshrgPwrLmtDTBttrOrCllVltg "HVESP8 Discharge Power Limit Due to Battery or Cell Voltage: Indicates whether or not discharge power of this HVES instance is being limited due to a battery or cell voltage level.This parameter is for one of multiple packs in an HVESS.  If there is ...";
CM_ SG_ 2364679166 Hvsp8DshrgPwrLmtDTBttrCrrnt "HVESP8 Discharge Power Limit Due to Battery Current: Indicates whether or not discharge power of this HVES instance is being limited due to battery current.This parameter is for one of multiple packs in an HVESS.  If there is only one pack in the sys...";
CM_ SG_ 2364679166 Hvsp8DshrgPwrLmtDTAnUndfndCs "HVESP8 Discharge Power Limit Due to an Undefined Cause: Indicates whether or not discharge power of this HVES instance is being limited due to an undefined cause.This parameter is for one of multiple packs in an HVESS.  If there is only one pack in t...";
CM_ SG_ 2364679166 Hvsp8ChrgPwrLmtDTSttOfChrg "HVESP8 Charge Power Limit Due to State of Charge: Indicates whether or not charge power of this HVES instance is being limited due to state of charge.This parameter is for one of multiple packs in an HVESS.  If there is only one pack in the system, t...";
CM_ SG_ 2364679166 Hvsp8ChrgPwrLmtDTBttrTmprtr "HVESP8 Charge Power Limit Due to Battery Temperature: Indicates whether or not charge power of this HVES instance is being limited due to battery temperature.This parameter is for one of multiple packs in an HVESS.  If there is only one pack in the s...";
CM_ SG_ 2364679166 Hvsp8ChrgPwrLmtDTBttrDgnstCndtn "HVESP8 Charge Power Limit Due to Battery Diagnostic Condition: Indicates whether or not charge power of this HVES instance is being limited due to a battery diagnostic condition.This parameter is for one of multiple packs in an HVESS.  If there is on...";
CM_ SG_ 2364679166 Hvsp8ChrgPwrLmtDTBttrOrCllVltg "HVESP8 Charge Power Limit Due to Battery or Cell Voltage: Indicates whether or not charge power of this HVES instance is being limited due to a battery or cell voltage level.This parameter is for one of multiple packs in an HVESS.  If there is only o...";
CM_ SG_ 2364679166 Hvsp8ChrgPwrLmtDTBttrCrrnt "HVESP8 Charge Power Limit Due to Battery Current: Indicates whether or not charge power of this HVES instance is being limited due to battery current.This parameter is for one of multiple packs in an HVESS.  If there is only one pack in the system, t...";
CM_ SG_ 2364679166 Hvsp8ChrgPwrLmtDTAnUndfndCs "HVESP8 Charge Power Limit Due to an Undefined Cause: Indicates whether or not charge power of this HVES instance is being limited due to an undefined cause.This parameter is for one of multiple packs in an HVESS.  If there is only one pack in the sys...";
CM_ BO_ 2364679422 "High Voltage Energy Storage Pack 8 Data 1";
CM_ SG_ 2364679422 Hvesp8AvailableDischargePower "HVESP8 Available Discharge Power: The rate at which this High Voltage Energy Storage Pack instance can currently provide energy for propulsion or other uses.This parameter is for one of multiple packs in an HVESS.  If there is only one pack in the sy...";
CM_ SG_ 2364679422 Hvesp8AvailableChargePower "HVESP8 Available Charge Power: The rate at which this High Voltage Energy Storage Pack instance can currently receive energy from a regenerative or recharging system.This parameter is for one of multiple packs in an HVESS.  If there is only one pack ...";
CM_ SG_ 2364679422 Hvesp8VoltageLevel "HVESP8 Voltage Level: The voltage level of this High Voltage Energy Storage Pack instance. This parameter should be synchronized with SPN 14206 (HVESP8 Current) such that a realized power value can be calculated. If the HVES component physically cont...";
CM_ SG_ 2364679422 Hvesp8Current "HVESP8 Current: The current in or out of this High Voltage Energy Storage Pack instance. This parameter should be synchronized with SPN 14205 (HVESP8 Voltage Level) such that a realized power value can be calculated. This parameter is defined from th...";
CM_ BO_ 2364679678 "High Voltage Energy Storage Pack 8 Data 2";
CM_ SG_ 2364679678 Hvesp8FastUpdateStateOfCharge "HVESP8 Fast Update State of Charge: Indicates this High Voltage Energy Storage Pack instance state of charge. 0% means no charge remaining, 100% means the system is fully charged in terms of physical limits of this energy storage pack instance. Accep...";
CM_ SG_ 2364679678 Hvesp8HighestCellVoltage "HVESP8 Highest Cell Voltage: The highest voltage level reported by any cell in this High Voltage Energy Storage Pack instance. If a single voltage sensor covers more than one cell, the value in this parameter is for the smallest group of cells measur...";
CM_ SG_ 2364679678 Hvesp8LowestCellVoltage "HVESP8 Lowest Cell Voltage: The lowest voltage level reported by any cell in this High Voltage Energy Storage Pack instance. If a single voltage sensor covers more than one cell, the value in this parameter is for the smallest group of cells measured...";
CM_ SG_ 2364679678 Hvsp8CllVltgDffrntlStts "HVESP8 Cell Voltage Differential Status: Indicates whether or not the differential between the highest and lowest cell voltages are within acceptable limits, according to this High Voltage Energy Storage Pack instance. The actual voltage differential...";
CM_ BO_ 2364679934 "High Voltage Energy Storage Pack 8 Data 3";
CM_ SG_ 2364679934 Hvesp8HighestCellTemperature "HVESP8 Highest Cell Temperature: The highest temperature level reported by any cell in this High Voltage Energy Storage Pack instance. If a single temperature sensor covers more than one cell, the value in this parameter is for the smallest group of ...";
CM_ SG_ 2364679934 Hvesp8LowestCellTemperature "HVESP8 Lowest Cell Temperature: The lowest temperature level reported by any cell in this High Voltage Energy Storage Pack instance. If a single temperature sensor covers more than one cell, the value in this parameter is for the smallest group of ce...";
CM_ SG_ 2364679934 Hvesp8AverageCellTemperature "HVESP8 Average Cell Temperature: The average temperature level of all cells in this High Voltage Energy Storage Pack instance.This parameter is for one of multiple packs in an HVESS.  If there is only one pack in the system, the HVESS parameters shou...";
CM_ SG_ 2364679934 Hvsp8CllTmprtrDffrntlStts "HVESP8 Cell Temperature Differential Status: Indicates whether or not the differential between the highest and lowest cell temperatures are within acceptable limits per this High Voltage Energy Storage Pack instance. The actual temperature differenti...";
CM_ BO_ 2364680190 "High Voltage Energy Storage Pack 8 Data 4";
CM_ SG_ 2364680190 Hvesp8DischargeCapacity "HVESP8 Discharge Capacity: The amount of stored electrical charge in this High Voltage Energy Storage Pack instance that is available for use by the hybrid or EV system, i.e. 'how full is the tank'. See SPN 14245 (HVESP8 Discharge Energy Capacity) fo...";
CM_ SG_ 2364680190 Hvesp8ChargeCapacity "HVESP8 Charge Capacity: The amount of unused electrical charge storage in this High Voltage Energy Storage Pack instance that is available to be filled by charging, i.e. 'how much empty space is remaining in the tank'. See SPN 14246 (HVESP8 Charge En...";
CM_ SG_ 2364680190 Hvesp8CellBalancingCount "HVESP8 Cell Balancing Count: The number of cells that are currently being balanced in this High Voltage Energy Storage Pack instance.This parameter is for one of multiple packs in an HVESS.  If there is only one pack in the system, the HVESS paramete...";
CM_ BO_ 2364680446 "High Voltage Energy Storage Pack 8 Data 5";
CM_ SG_ 2364680446 Hvesp8LowestCellStateOfCharge "HVESP8 Lowest Cell State of Charge: Indicates the state of charge of the lowest-charged cell in this High Voltage Energy Storage Pack instance. 0% means no charge remaining, 100% means the cell is fully charged. If a single state of charge value cove...";
CM_ SG_ 2364680446 Hvesp8HighestCellStateOfCharge "HVESP8 Highest Cell State of Charge: Indicates the state of charge of the highest-charged cell in this High Voltage Energy Storage Pack instance. 0% means no charge remaining, 100% means the cell is fully charged. If a single state of charge value co...";
CM_ SG_ 2364680446 Hvsp8MxmmInstntnsDshrgCrrntLmt "HVESP8 Maximum Instantaneous Discharge Current Limit: The maximum instantaneous current flow limit out of this High Voltage Energy Storage Pack instance. This parameter is defined from the high voltage energy storage pack's point of view and should r...";
CM_ SG_ 2364680446 Hvsp8MxmmInstntnsChrgCrrntLmt "HVESP8 Maximum Instantaneous Charge Current Limit: The maximum instantaneous current flow limit into this High Voltage Energy Storage Pack instance. This parameter is defined from the high voltage energy storage pack's point of view and should reflec...";
CM_ BO_ 2364680702 "High Voltage Energy Storage Pack 8 Data 6";
CM_ SG_ 2364680702 Hvesp8BusVoltage "HVESP8 Bus Voltage: The voltage level of the high voltage bus, as measured by this High Voltage Energy Storage Pack instance on the bus side (not the battery side) of its contactors.This parameter is for one of multiple packs in an HVESS.  If there i...";
CM_ SG_ 2364680702 Hvesp8IgnitionVoltage "HVESP8 Ignition Voltage: The voltage level at the ignition input of this High Voltage Energy Storage Pack controller.This parameter is for one of multiple packs in an HVESS.  If there is only one pack in the system, the HVESS parameters should be use...";
CM_ SG_ 2364680702 Hvesp8IntakeCoolantTemperature "HVESP8 Intake Coolant Temperature: The temperature of liquid coolant as it enters this High Voltage Energy Storage Pack instance.This parameter is for one of multiple packs in an HVESS.  If there is only one pack in the system, the HVESS parameters s...";
CM_ SG_ 2364680702 Hvesp8OutletCoolantTemperature "HVESP8 Outlet Coolant Temperature: The temperature of liquid coolant as it exits this High Voltage Energy Storage Pack instance.This parameter is for one of multiple packs in an HVESS.  If there is only one pack in the system, the HVESS parameters sh...";
CM_ SG_ 2364680702 Hvesp8ElectronicsTemperature "HVESP8 Electronics Temperature: The temperature of the electronics or control modules in this High Voltage Energy Storage Pack instance.  If there are multiple temperature sensors then this parameter would be set to the maximum sensor reading.This pa...";
CM_ SG_ 2364680702 Hvesp8Temperature "HVESP8 Temperature: The temperature of this High Voltage Energy Storage Pack instance. The value may be determined from a unique sensor specifically for this purpose, or by aggregating various temperature sensor readings within the pack.This paramete...";
CM_ BO_ 2364680958 "High Voltage Energy Storage Pack 8 Status 1";
CM_ SG_ 2364680958 Hvesp8HvilStatus "HVESP8 HVIL Status: Status of the High Voltage Interlock Loop from the viewpoint of this High Voltage Energy Storage Pack instance.This parameter is for one of multiple packs in an HVESS. If there is only one pack in the system, the HVESS parameters ...";
CM_ SG_ 2364680958 Hvesp8InertiaSwitchStatus "HVESP8 Inertia Switch Status: Switch indicating that an impact has been sensed by this High Voltage Energy Storage Pack instance. The impact indication may require action by another controller, or by this HVES instance itself.  For example, a control...";
CM_ SG_ 2364680958 Hvesp8StateOfChargeStatus "HVESP8 State of Charge Status: Status of this High Voltage Energy Storage Pack instance State of Charge (SOC).  Note:  A given HVES controller may not support all of the states.This parameter is for one of multiple packs in an HVESS.  If there is onl...";
CM_ SG_ 2364680958 Hvesp8CellBalanceStatus "HVESP8 Cell Balance Status: Indicates whether or not the cells in this High Voltage Energy Storage Pack instance are balanced.This parameter is for one of multiple packs in an HVESS.  If there is only one pack in the system, the HVESS parameters shou...";
CM_ SG_ 2364680958 Hvesp8CellBalancingActive "HVESP8 Cell Balancing Active: Indicates whether or not the cells in this High Voltage Energy Storage Pack instance are currently being balanced.This parameter is for one of multiple packs in an HVESS.  If there is only one pack in the system, the HVE...";
CM_ SG_ 2364680958 Hvesp8InternalChargerStatus "HVESP8 Internal Charger Status: Indicates that the charger in this HVES instance is on.  External chargers may use the External Energy Source Connection Status (SPN 7898) and related SPs.This parameter is for one of multiple packs in an HVESS. If the...";
CM_ SG_ 2364680958 Hvesp8OperationalStatus "HVESP8 Operational Status: Provides feedback on where this High Voltage Energy Storage Pack instance is in its operating spectrum, and includes feedback in response to the Operation Consent [i.e. SPN 14186 (HVESP8 Operation Consent)] and Power Down C...";
CM_ SG_ 2364680958 Hvesp8Status1Counter "HVESP8 Status 1 Counter: The message counter is used to detect situations where the transmitting ECU malfunction repeats the same frame all the time. The receiver of the information may use the counter parameter to detect this situation. The transmit...";
CM_ SG_ 2364680958 Hvesp8Status1Crc "HVESP8 Status 1 CRC: The CRC is defined as follows: - Length: 8 bits- Polynomial: x^8+x^5+x^3+x^2+x+1- Initial Value: FFh- Input Data Reflection: Not reflected- Result Data Reflection: Not reflected- XOR value: FFh SAE makes no claim of the functiona...";
CM_ SG_ 2364680958 Hvsp8HghVltgBsPstvCnttrStt "HVESP8 High-Voltage Bus (Positive) Contactor State: Position of this High Voltage Energy Storage Pack instance positive side bus contactor.  When this contactor is closed, the positive side of this HVES instance is connected to the positive side of t...";
CM_ SG_ 2364680958 Hvsp8HghVltgBsNgtvCnttrStt "HVESP8 High-Voltage Bus (Negative) Contactor State: Position of this High Voltage Energy Storage Pack instance negative side bus contactor. When this contactor is closed, the negative side of this HVES instance is connected to the negative side of th...";
CM_ SG_ 2364680958 Hvsp8HghVltgBsDsnntFrwrnng "HVESP8 High-Voltage Bus Disconnect Forewarning: Indicates that this High Voltage Energy Storage Pack instance is about to disconnect from the high voltage bus due to unacceptable conditions.This parameter is for one of multiple packs in an HVESS. If ...";
CM_ SG_ 2364680958 Hvsp8HghVltgBsPrChrgRlStt "HVESP8 High-Voltage Bus Pre-Charge Relay State: Position of the high-voltage bus contactor pre-charge relay.  When this relay is closed, this High Voltage Energy Storage Pack instance is bringing the high-voltage bus up to its operating level.This pa...";
CM_ SG_ 2364680958 Hvsp8CntrOfPkCnttrStt "HVESP8 Center of Pack Contactor State: Position of the center high-voltage contactor. When this contactor is closed, the positive half of this High Voltage Energy Storage Pack instance is connected to the negative half. If a system controls the posit...";
CM_ SG_ 2364680958 Hvsp8HghVltgBsAtvIsltnTstStts "HVESP8 High-Voltage Bus Active Isolation Test Status: Status of the high-voltage bus electrical active isolation test as performed by this High Voltage Energy Storage Pack instance.This parameter is for one of multiple packs in an HVESS. If there is ...";
CM_ SG_ 2364680958 Hvsp8HghVltgBsPssvIsltnTstStts "HVESP8 High-Voltage Bus Passive Isolation Test Status: Status of the high-voltage bus electrical passive isolation test as performed by this High Voltage Energy Storage Pack instance.This parameter is for one of multiple packs in an HVESS. If there i...";
CM_ SG_ 2364680958 Hvsp8HghVltgBsCnntnStts "HVESP8 High-Voltage Bus Connection Status: This parameter provides high level feedback on this High Voltage Energy Storage Pack instance high voltage bus connection. For specific contactor information, see SPN 14228 (HVESP8 High-Voltage Bus (Positive...";
CM_ BO_ 2364681214 "High Voltage Energy Storage Pack 8 Data 7";
CM_ SG_ 2364681214 Hvesp8DischargeEnergyCapacity "HVESP8 Discharge Energy Capacity: The amount of stored electrical energy in this High Voltage Energy Storage Pack instance that is available for use by the hybrid or EV system, i.e. 'how full is the tank'. See SPN 14215 (HVESP8 Discharge Capacity) fo...";
CM_ SG_ 2364681214 Hvesp8ChargeEnergyCapacity "HVESP8 Charge Energy Capacity: The amount of unused electrical energy storage available to be filled by charging this High Voltage Energy Storage Pack instance, i.e. 'how much empty space is remaining in the tank'. See SPN 14216 (HVESP8 Charge Capaci...";
CM_ SG_ 2364681214 Hvesp8MaximumChargeVoltageLimit "HVESP8 Maximum Charge Voltage Limit: The maximum voltage level not to be exceeded while charging this High Voltage Energy Storage Pack instance. If this parameter is not supported, the maximum charge voltage should be limited to SPN 14316 (HVESP8 Rec...";
CM_ BO_ 2364681470 "High Voltage Energy Storage Pack 8 Module Status 1";
CM_ SG_ 2364681470 Hvesp8Module1OperationalStatus "HVESP8 Module 1 Operational Status: Operational Status of Module 1 in this High Voltage Energy Storage Pack Instance.  Not Operational is used when the module is initializing or not able to function (e.g. internal module level monitors have failed). ...";
CM_ SG_ 2364681470 Hvesp8Module2OperationalStatus "HVESP8 Module 2 Operational Status: Operational Status of Module 2 in this High Voltage Energy Storage Pack Instance.  Not Operational is used when the module is initializing or not able to function (e.g. internal module level monitors have failed). ...";
CM_ SG_ 2364681470 Hvesp8Module3OperationalStatus "HVESP8 Module 3 Operational Status: Operational Status of Module 3 in this High Voltage Energy Storage Pack Instance.  Not Operational is used when the module is initializing or not able to function (e.g. internal module level monitors have failed). ...";
CM_ SG_ 2364681470 Hvesp8Module4OperationalStatus "HVESP8 Module 4 Operational Status: Operational Status of Module 4 in this High Voltage Energy Storage Pack Instance.  Not Operational is used when the module is initializing or not able to function (e.g. internal module level monitors have failed). ...";
CM_ SG_ 2364681470 Hvesp8Module5OperationalStatus "HVESP8 Module 5 Operational Status: Operational Status of Module 5 in this High Voltage Energy Storage Pack Instance.  Not Operational is used when the module is initializing or not able to function (e.g. internal module level monitors have failed). ...";
CM_ SG_ 2364681470 Hvesp8Module6OperationalStatus "HVESP8 Module 6 Operational Status: Operational Status of Module 6 in this High Voltage Energy Storage Pack Instance.  Not Operational is used when the module is initializing or not able to function (e.g. internal module level monitors have failed). ...";
CM_ SG_ 2364681470 Hvesp8Module7OperationalStatus "HVESP8 Module 7 Operational Status: Operational Status of Module 7 in this High Voltage Energy Storage Pack Instance.  Not Operational is used when the module is initializing or not able to function (e.g. internal module level monitors have failed). ...";
CM_ SG_ 2364681470 Hvesp8Module8OperationalStatus "HVESP8 Module 8 Operational Status: Operational Status of Module 8 in this High Voltage Energy Storage Pack Instance.  Not Operational is used when the module is initializing or not able to function (e.g. internal module level monitors have failed). ...";
CM_ SG_ 2364681470 Hvesp8Module9OperationalStatus "HVESP8 Module 9 Operational Status: Operational Status of Module 9 in this High Voltage Energy Storage Pack Instance.  Not Operational is used when the module is initializing or not able to function (e.g. internal module level monitors have failed). ...";
CM_ SG_ 2364681470 Hvesp8Module10OperationalStatus "HVESP8 Module 10 Operational Status: Operational Status of Module 10 in this High Voltage Energy Storage Pack Instance.  Not Operational is used when the module is initializing or not able to function (e.g. internal module level monitors have failed)...";
CM_ SG_ 2364681470 Hvesp8Module11OperationalStatus "HVESP8 Module 11 Operational Status: Operational Status of Module 11 in this High Voltage Energy Storage Pack Instance.  Not Operational is used when the module is initializing or not able to function (e.g. internal module level monitors have failed)...";
CM_ SG_ 2364681470 Hvesp8Module12OperationalStatus "HVESP8 Module 12 Operational Status: Operational Status of Module 12 in this High Voltage Energy Storage Pack Instance.  Not Operational is used when the module is initializing or not able to function (e.g. internal module level monitors have failed)...";
CM_ SG_ 2364681470 Hvesp8Module13OperationalStatus "HVESP8 Module 13 Operational Status: Operational Status of Module 13 in this High Voltage Energy Storage Pack Instance.  Not Operational is used when the module is initializing or not able to function (e.g. internal module level monitors have failed)...";
CM_ SG_ 2364681470 Hvesp8Module14OperationalStatus "HVESP8 Module 14 Operational Status: Operational Status of Module 14 in this High Voltage Energy Storage Pack Instance.  Not Operational is used when the module is initializing or not able to function (e.g. internal module level monitors have failed)...";
CM_ SG_ 2364681470 Hvesp8Module15OperationalStatus "HVESP8 Module 15 Operational Status: Operational Status of Module 15 in this High Voltage Energy Storage Pack Instance.  Not Operational is used when the module is initializing or not able to function (e.g. internal module level monitors have failed)...";
CM_ SG_ 2364681470 Hvesp8Module16OperationalStatus "HVESP8 Module 16 Operational Status: Operational Status of Module 16 in this High Voltage Energy Storage Pack Instance.  Not Operational is used when the module is initializing or not able to function (e.g. internal module level monitors have failed)...";
CM_ SG_ 2364681470 Hvesp8Module17OperationalStatus "HVESP8 Module 17 Operational Status: Operational Status of Module 17 in this High Voltage Energy Storage Pack Instance.  Not Operational is used when the module is initializing or not able to function (e.g. internal module level monitors have failed)...";
CM_ SG_ 2364681470 Hvesp8Module18OperationalStatus "HVESP8 Module 18 Operational Status: Operational Status of Module 18 in this High Voltage Energy Storage Pack Instance.  Not Operational is used when the module is initializing or not able to function (e.g. internal module level monitors have failed)...";
CM_ SG_ 2364681470 Hvesp8Module19OperationalStatus "HVESP8 Module 19 Operational Status: Operational Status of Module 19 in this High Voltage Energy Storage Pack Instance.  Not Operational is used when the module is initializing or not able to function (e.g. internal module level monitors have failed)...";
CM_ SG_ 2364681470 Hvesp8Module20OperationalStatus "HVESP8 Module 20 Operational Status: Operational Status of Module 20 in this High Voltage Energy Storage Pack Instance.  Not Operational is used when the module is initializing or not able to function (e.g. internal module level monitors have failed)...";
CM_ SG_ 2364681470 Hvesp8Module21OperationalStatus "HVESP8 Module 21 Operational Status: Operational Status of Module 21 in this High Voltage Energy Storage Pack Instance.  Not Operational is used when the module is initializing or not able to function (e.g. internal module level monitors have failed)...";
CM_ SG_ 2364681470 Hvesp8Module22OperationalStatus "HVESP8 Module 22 Operational Status: Operational Status of Module 22 in this High Voltage Energy Storage Pack Instance.  Not Operational is used when the module is initializing or not able to function (e.g. internal module level monitors have failed)...";
CM_ SG_ 2364681470 Hvesp8Module23OperationalStatus "HVESP8 Module 23 Operational Status: Operational Status of Module 23 in this High Voltage Energy Storage Pack Instance.  Not Operational is used when the module is initializing or not able to function (e.g. internal module level monitors have failed)...";
CM_ SG_ 2364681470 Hvesp8Module24OperationalStatus "HVESP8 Module 24 Operational Status: Operational Status of Module 24 in this High Voltage Energy Storage Pack Instance.  Not Operational is used when the module is initializing or not able to function (e.g. internal module level monitors have failed)...";
CM_ SG_ 2364681470 Hvesp8Module25OperationalStatus "HVESP8 Module 25 Operational Status: Operational Status of Module 25 in this High Voltage Energy Storage Pack Instance.  Not Operational is used when the module is initializing or not able to function (e.g. internal module level monitors have failed)...";
CM_ SG_ 2364681470 Hvesp8Module26OperationalStatus "HVESP8 Module 26 Operational Status: Operational Status of Module 26 in this High Voltage Energy Storage Pack Instance.  Not Operational is used when the module is initializing or not able to function (e.g. internal module level monitors have failed)...";
CM_ SG_ 2364681470 Hvesp8Module27OperationalStatus "HVESP8 Module 27 Operational Status: Operational Status of Module 27 in this High Voltage Energy Storage Pack Instance.  Not Operational is used when the module is initializing or not able to function (e.g. internal module level monitors have failed)...";
CM_ SG_ 2364681470 Hvesp8Module28OperationalStatus "HVESP8 Module 28 Operational Status: Operational Status of Module 28 in this High Voltage Energy Storage Pack Instance.  Not Operational is used when the module is initializing or not able to function (e.g. internal module level monitors have failed)...";
CM_ SG_ 2364681470 Hvesp8Module29OperationalStatus "HVESP8 Module 29 Operational Status: Operational Status of Module 29 in this High Voltage Energy Storage Pack Instance.  Not Operational is used when the module is initializing or not able to function (e.g. internal module level monitors have failed)...";
CM_ SG_ 2364681470 Hvesp8Module30OperationalStatus "HVESP8 Module 30 Operational Status: Operational Status of Module 30 in this High Voltage Energy Storage Pack Instance.  Not Operational is used when the module is initializing or not able to function (e.g. internal module level monitors have failed)...";
CM_ SG_ 2364681470 Hvesp8Module31OperationalStatus "HVESP8 Module 31 Operational Status: Operational Status of Module 31 in this High Voltage Energy Storage Pack Instance.  Not Operational is used when the module is initializing or not able to function (e.g. internal module level monitors have failed)...";
CM_ SG_ 2364681470 Hvesp8Module32OperationalStatus "HVESP8 Module 32 Operational Status: Operational Status of Module 32 in this High Voltage Energy Storage Pack Instance.  Not Operational is used when the module is initializing or not able to function (e.g. internal module level monitors have failed)...";
CM_ BO_ 2364681726 "High Voltage Energy Storage Pack 8 Thermal Management System Status 1";
CM_ SG_ 2364681726 Hvsp8ThrmlMngmntSstmSlInptPwr "HVESP8 Thermal Management System SLI Input Power: This is the low-voltage power consumed by this HVES Thermal Management System (TMS).This parameter is for one of multiple packs in an HVESS.  If there is only one pack in the system, the HVESS paramet...";
CM_ SG_ 2364681726 Hvsp8TMtSstHVtIptPw "HVESP8 Thermal Management System High-Voltage Input Power: This is the high-voltage power consumed by this HVES Thermal Management System (TMS).This parameter is for one of multiple packs in an HVESS.  If there is only one pack in the system, the HVE...";
CM_ SG_ 2364681726 Hvsp8ThrmlMngmntSstmCmprssrSpd "HVESP8 Thermal Management System Compressor Speed: When this High Voltage Energy Storage Pack Thermal Management System is equipped with an active cooling system (e.g. air conditioner), this is the Compressor Speed.This parameter is for one of multip...";
CM_ SG_ 2364681726 Hvsp8ThrmlMngmntSstmRltvHmdt "HVESP8 Thermal Management System Relative Humidty: When this High Voltage Energy Storage Pack Thermal Management System is equipped with a relative humidity sensor, this is the  measured Relative Humidity.This parameter is for one of multiple packs i...";
CM_ SG_ 2364681726 Hvsp8ThrmlMngmntSstmHtrStts "HVESP8 Thermal Management System Heater Status: The state of this High Voltage Energy Storage Pack heaterThis parameter is for one of multiple packs in an HVESS.  If there is only one pack in the system, the HVESS parameters should be used. If there ...";
CM_ SG_ 2364681726 Hvsp8ThrmlMngmntSstmHvlStts "HVESP8 Thermal Management System HVIL Status: In multiple HVES configurations, this is the status of the High Voltage Interlock Loop from the viewpoint of this Thermal Management System.00b = HVIL Closed01b = HVIL Open10b = Error11b = Not AvailableTh...";
CM_ SG_ 2364681726 Hvsp8ThrmlMngmntSstmMd "HVESP8 Thermal Management System Mode: Indicates the operating mode of the Thermal Management System.  The heat transfer medium may be (e.g. liquid or air).  The cooling system may be fans, liquid coolant, or a combination of mediums.  The system may...";
CM_ SG_ 2364681726 Hvsp8ThrmlMngmntSstmClntLvl "HVESP8 Thermal Management System Coolant Level: Indicates the coolant level in this HVES Thermal Management System (TMS).This parameter is for one of multiple packs in an HVESS.  If there is only one pack in the system, the HVESS parameters should be...";
CM_ BO_ 2364681982 "High Voltage Energy Storage Pack 8 Data 8";
CM_ SG_ 2364681982 Hvesp8AverageCellVoltage "HVESP8 Average Cell Voltage: The average cell voltage in this High Voltage Energy Storage Pack instance.This parameter is for one of multiple packs in an HVESS.  If there is only one pack in the system, the HVESS parameters should be used. If there a...";
CM_ SG_ 2364681982 Hvsp8HghstCllVltgMdlNmr "HVESP8 Highest Cell Voltage Module Number: Identifies the location of the module containing SPN 14208 (HVESP8 Highest Cell Voltage).This parameter is for one of multiple packs in an HVESS. If there is only one pack in the system, the HVESS parameters...";
CM_ SG_ 2364681982 Hvsp8HghstCllVltgCllNmr "HVESP8 Highest Cell Voltage Cell Number: Identifies the location of SPN 14208 (HVESP8 Highest Cell Voltage) within SPN 14288 (HVESP8 Highest Cell Voltage Module Number).This parameter is for one of multiple packs in an HVESS. If there is only one pac...";
CM_ SG_ 2364681982 Hvsp8LwstCllVltgMdlNmr "HVESP8 Lowest Cell Voltage Module Number: Identifies the location of the module containing SPN 14209 (HVESP8 Lowest Cell Voltage).This parameter is for one of multiple packs in an HVESS. If there is only one pack in the system, the HVESS parameters s...";
CM_ SG_ 2364681982 Hvsp8LwstCllVltgCllNmr "HVESP8 Lowest Cell Voltage Cell Number: Identifies the location of SPN 14209 (HVESP8 Lowest Cell Voltage) within SPN 14290 (HVESP8 Lowest Cell Voltage Module Number).This parameter is for one of multiple packs in an HVESS. If there is only one pack i...";
CM_ BO_ 2364682238 "High Voltage Energy Storage Pack 8 Data 9";
CM_ SG_ 2364682238 Hvsp8HghstCllTmprtrMdlNmr "HVESP8 Highest Cell Temperature Module Number: Identifies the location of the module containing SPN 14211 (HVESP8 Highest Cell Temperature).This parameter is for one of multiple packs in an HVESS. If there is only one pack in the system, the HVESS pa...";
CM_ SG_ 2364682238 Hvsp8HghstCllTmprtrCllNmr "HVESP8 Highest Cell Temperature Cell Number: Identifies the location of SPN 14211 (HVESP8 Highest Cell Temperature) within SPN 14293 (HVESP8 Highest Cell Temperature Module Number).This parameter is for one of multiple packs in an HVESS. If there is ...";
CM_ SG_ 2364682238 Hvsp8LwstCllTmprtrMdlNmr "HVESP8 Lowest Cell Temperature Module Number: Identifies the location of the module containing SPN 14212 (HVESP8 Lowest Cell Temperature).This parameter is for one of multiple packs in an HVESS. If there is only one pack in the system, the HVESS para...";
CM_ SG_ 2364682238 Hvsp8LwstCllTmprtrCllNmr "HVESP8 Lowest Cell Temperature Cell Number: Identifies the location of SPN 14212 (HVESP8 Lowest Cell Temperature) within SPN 14295 (HVESP8 Lowest Cell Temperature Module Number).This parameter is for one of multiple packs in an HVESS. If there is onl...";
CM_ SG_ 2364682238 Hvess8ThermalEventDetected "HVESS8 Thermal Event Detected: A sensor has detected the presence of a thermal event at or near High Voltage Energy Storage Pack instance.00b = No Thermal Event Detected01b = Thermal Event Detected10b = Error11b = Not availableThis parameter is for o...";
CM_ SG_ 2364682238 Hvsp8Dt9EmdddIntgrtSpprt "HVESP8 Data 9 Embedded Integrity Support: Indicates SPN 22997 (HVESP8 Data 9 CRC) and SPN 22996 (HVESP8 Data 9 Counter) are supported by the sender.00b = Embedded CRC and Counter are supported by the sender01b = Protection is provided using an extern...";
CM_ SG_ 2364682238 Hvesp8Data9Counter "HVESP8 Data 9 Counter: The message counter is used to detect situations where the transmitting ECU malfunction repeats the same frame all the time. The receiver of the information may use the counter parameter to detect this situation. The transmitti...";
CM_ SG_ 2364682238 Hvesp8Data9Crc "HVESP8 Data 9 CRC: The CRC is defined as follows: - Length: 8 bits- Polynomial: x^8+x^5+x^3+x^2+x+1- Initial Value: FFh- Input Data Reflection: Not reflected- Result Data Reflection: Not reflected- XOR value: FFh SAE makes no claim of the functional ...";
CM_ BO_ 2364682494 "High Voltage Energy Storage Pack 8 Data 10";
CM_ SG_ 2364682494 Hvsp8HghstCllSttOfChrgMdlNmr "HVESP8 Highest Cell State of Charge Module Number: Identifies the location of the module containing SPN 14221 (HVESP8 Highest Cell State of Charge).This parameter is for one of multiple packs in an HVESS. If there is only one pack in the system, the ...";
CM_ SG_ 2364682494 Hvsp8HghstCllSttOfChrgCllNmr "HVESP8 Highest Cell State of Charge Cell Number: Identifies the location of SPN 14221 (HVESP8 Highest Cell State of Charge) within SPN 14297 (HVESP8 Highest Cell State of Charge Module Number).This parameter is for one of multiple packs in an HVESS. ...";
CM_ SG_ 2364682494 Hvsp8LwstCllSttOfChrgMdlNmr "HVESP8 Lowest Cell State of Charge Module Number: Identifies the location of the module containing SPN 14220 (HVESP8 Lowest Cell State of Charge).This parameter is for one of multiple packs in an HVESS. If there is only one pack in the system, the HV...";
CM_ SG_ 2364682494 Hvsp8LwstCllSttOfChrgCllNmr "HVESP8 Lowest Cell State of Charge Cell Number: Identifies the location of SPN 14220 (HVESP8 Lowest Cell State of Charge) within SPN 14299 (HVESP8 Lowest Cell State of Charge Module Number).This parameter is for one of multiple packs in an HVESS. If ...";
CM_ SG_ 2364682494 Hvsp8HghVltgBsAtvIsltnTstRslts "HVESP8 High-Voltage Bus Active Isolation Test Results: The isolation resistance expressed in Ohms per Volt that resulted from the High-Voltage Bus Active Isolation Test.See SPN 14233 (HVESP8 High-Voltage Bus Active Isolation Test Status) for test sta...";
CM_ SG_ 2364682494 Hvsp8HghVltgBsPssvIsltnTstRslts "HVESP8 High-Voltage Bus Passive Isolation Test Results: The isolation resistance expressed in Ohms per Volt that resulted from the High-Voltage Bus Passive Isolation Test.See SPN 14234 (HVESP8 High-Voltage Bus Passive Isolation Test Status) for test ...";
CM_ BO_ 2364682750 "High Voltage Energy Storage Pack 8 Data 11";
CM_ SG_ 2364682750 Hvesp8ActualChargeRate "HVESP8 Actual Charge Rate: This signal represents the actual present charge rate of this High Voltage Energy Storage Pack instance.This parameter is for one of multiple packs in an HVESS. If there is only one pack in the system, the HVESS parameters ...";
CM_ SG_ 2364682750 Hvsp8BsVltgNgtvTChsssGrndVltg "HVESP8 Bus Voltage Negative to Chassis Ground Voltage: Voltage difference between the most negative terminal of the HVES battery and chassis measured on the hybrid or EV system bus side (not the battery side) of any HVES contained output contactor.  ...";
CM_ SG_ 2364682750 Hvsp8VltgLvlNgtvTChsssGrndVltg "HVESP8 Voltage Level Negative to Chassis Ground Voltage: Voltage difference between the most negative terminal of the HVES battery and chassis measured at the battery side of any HVES contained output contactor.  This voltage may be used for system l...";
CM_ BO_ 2364683006 "High Voltage Energy Storage Pack 9 Status 2";
CM_ SG_ 2364683006 Hvsp9DshrgPwrLmtDTSttOfChrg "HVESP9 Discharge Power Limit Due to State of Charge: Indicates whether or not discharge power of this HVES instance is being limited due to state of charge.This parameter is for one of multiple packs in an HVESS.  If there is only one pack in the sys...";
CM_ SG_ 2364683006 Hvsp9DshrgPwrLmtDTBttrTmprtr "HVESP9 Discharge Power Limit Due to Battery Temperature: Indicates whether or not discharge power of this HVES instance is being limited due to battery temperature.This parameter is for one of multiple packs in an HVESS.  If there is only one pack in...";
CM_ SG_ 2364683006 Hvsp9DsPwLtDTBttDstCdt "HVESP9 Discharge Power Limit Due to Battery Diagnostic Condition: Indicates whether or not discharge power of this HVES instance is being limited due to a battery diagnostic condition.This parameter is for one of multiple packs in an HVESS.  If there...";
CM_ SG_ 2364683006 Hvsp9DshrgPwrLmtDTBttrOrCllVltg "HVESP9 Discharge Power Limit Due to Battery or Cell Voltage: Indicates whether or not discharge power of this HVES instance is being limited due to a battery or cell voltage level.This parameter is for one of multiple packs in an HVESS.  If there is ...";
CM_ SG_ 2364683006 Hvsp9DshrgPwrLmtDTBttrCrrnt "HVESP9 Discharge Power Limit Due to Battery Current: Indicates whether or not discharge power of this HVES instance is being limited due to battery current.This parameter is for one of multiple packs in an HVESS.  If there is only one pack in the sys...";
CM_ SG_ 2364683006 Hvsp9DshrgPwrLmtDTAnUndfndCs "HVESP9 Discharge Power Limit Due to an Undefined Cause: Indicates whether or not discharge power of this HVES instance is being limited due to an undefined cause.This parameter is for one of multiple packs in an HVESS.  If there is only one pack in t...";
CM_ SG_ 2364683006 Hvsp9ChrgPwrLmtDTSttOfChrg "HVESP9 Charge Power Limit Due to State of Charge: Indicates whether or not charge power of this HVES instance is being limited due to state of charge.This parameter is for one of multiple packs in an HVESS.  If there is only one pack in the system, t...";
CM_ SG_ 2364683006 Hvsp9ChrgPwrLmtDTBttrTmprtr "HVESP9 Charge Power Limit Due to Battery Temperature: Indicates whether or not charge power of this HVES instance is being limited due to battery temperature.This parameter is for one of multiple packs in an HVESS.  If there is only one pack in the s...";
CM_ SG_ 2364683006 Hvsp9ChrgPwrLmtDTBttrDgnstCndtn "HVESP9 Charge Power Limit Due to Battery Diagnostic Condition: Indicates whether or not charge power of this HVES instance is being limited due to a battery diagnostic condition.This parameter is for one of multiple packs in an HVESS.  If there is on...";
CM_ SG_ 2364683006 Hvsp9ChrgPwrLmtDTBttrOrCllVltg "HVESP9 Charge Power Limit Due to Battery or Cell Voltage: Indicates whether or not charge power of this HVES instance is being limited due to a battery or cell voltage level.This parameter is for one of multiple packs in an HVESS.  If there is only o...";
CM_ SG_ 2364683006 Hvsp9ChrgPwrLmtDTBttrCrrnt "HVESP9 Charge Power Limit Due to Battery Current: Indicates whether or not charge power of this HVES instance is being limited due to battery current.This parameter is for one of multiple packs in an HVESS.  If there is only one pack in the system, t...";
CM_ SG_ 2364683006 Hvsp9ChrgPwrLmtDTAnUndfndCs "HVESP9 Charge Power Limit Due to an Undefined Cause: Indicates whether or not charge power of this HVES instance is being limited due to an undefined cause.This parameter is for one of multiple packs in an HVESS.  If there is only one pack in the sys...";
CM_ BO_ 2364683262 "High Voltage Energy Storage Pack 9 Data 1";
CM_ SG_ 2364683262 Hvesp9AvailableDischargePower "HVESP9 Available Discharge Power: The rate at which this High Voltage Energy Storage Pack instance can currently provide energy for propulsion or other uses.This parameter is for one of multiple packs in an HVESS.  If there is only one pack in the sy...";
CM_ SG_ 2364683262 Hvesp9AvailableChargePower "HVESP9 Available Charge Power: The rate at which this High Voltage Energy Storage Pack instance can currently receive energy from a regenerative or recharging system.This parameter is for one of multiple packs in an HVESS.  If there is only one pack ...";
CM_ SG_ 2364683262 Hvesp9VoltageLevel "HVESP9 Voltage Level: The voltage level of this High Voltage Energy Storage Pack instance. This parameter should be synchronized with SPN 14349 (HVESP9 Current) such that a realized power value can be calculated. If the HVES component physically cont...";
CM_ SG_ 2364683262 Hvesp9Current "HVESP9 Current: The current in or out of this High Voltage Energy Storage Pack instance. This parameter should be synchronized with SPN 14348 (HVESP9 Voltage Level) such that a realized power value can be calculated. This parameter is defined from th...";
CM_ BO_ 2364683518 "High Voltage Energy Storage Pack 9 Data 2";
CM_ SG_ 2364683518 Hvesp9FastUpdateStateOfCharge "HVESP9 Fast Update State of Charge: Indicates this High Voltage Energy Storage Pack instance state of charge. 0% means no charge remaining, 100% means the system is fully charged in terms of physical limits of this energy storage pack instance. Accep...";
CM_ SG_ 2364683518 Hvesp9HighestCellVoltage "HVESP9 Highest Cell Voltage: The highest voltage level reported by any cell in this High Voltage Energy Storage Pack instance. If a single voltage sensor covers more than one cell, the value in this parameter is for the smallest group of cells measur...";
CM_ SG_ 2364683518 Hvesp9LowestCellVoltage "HVESP9 Lowest Cell Voltage: The lowest voltage level reported by any cell in this High Voltage Energy Storage Pack instance. If a single voltage sensor covers more than one cell, the value in this parameter is for the smallest group of cells measured...";
CM_ SG_ 2364683518 Hvsp9CllVltgDffrntlStts "HVESP9 Cell Voltage Differential Status: Indicates whether or not the differential between the highest and lowest cell voltages are within acceptable limits, according to this High Voltage Energy Storage Pack instance. The actual voltage differential...";
CM_ BO_ 2364683774 "High Voltage Energy Storage Pack 9 Data 3";
CM_ SG_ 2364683774 Hvesp9HighestCellTemperature "HVESP9 Highest Cell Temperature: The highest temperature level reported by any cell in this High Voltage Energy Storage Pack instance. If a single temperature sensor covers more than one cell, the value in this parameter is for the smallest group of ...";
CM_ SG_ 2364683774 Hvesp9LowestCellTemperature "HVESP9 Lowest Cell Temperature: The lowest temperature level reported by any cell in this High Voltage Energy Storage Pack instance. If a single temperature sensor covers more than one cell, the value in this parameter is for the smallest group of ce...";
CM_ SG_ 2364683774 Hvesp9AverageCellTemperature "HVESP9 Average Cell Temperature: The average temperature level of all cells in this High Voltage Energy Storage Pack instance.This parameter is for one of multiple packs in an HVESS.  If there is only one pack in the system, the HVESS parameters shou...";
CM_ SG_ 2364683774 Hvsp9CllTmprtrDffrntlStts "HVESP9 Cell Temperature Differential Status: Indicates whether or not the differential between the highest and lowest cell temperatures are within acceptable limits per this High Voltage Energy Storage Pack instance. The actual temperature differenti...";
CM_ BO_ 2364684030 "High Voltage Energy Storage Pack 9 Data 4";
CM_ SG_ 2364684030 Hvesp9DischargeCapacity "HVESP9 Discharge Capacity: The amount of stored electrical charge in this High Voltage Energy Storage Pack instance that is available for use by the hybrid or EV system, i.e. 'how full is the tank'. See SPN 14388 (HVESP9 Discharge Energy Capacity) fo...";
CM_ SG_ 2364684030 Hvesp9ChargeCapacity "HVESP9 Charge Capacity: The amount of unused electrical charge storage in this High Voltage Energy Storage Pack instance that is available to be filled by charging, i.e. 'how much empty space is remaining in the tank'. See SPN 14389 (HVESP9 Charge En...";
CM_ SG_ 2364684030 Hvesp9CellBalancingCount "HVESP9 Cell Balancing Count: The number of cells that are currently being balanced in this High Voltage Energy Storage Pack instance.This parameter is for one of multiple packs in an HVESS.  If there is only one pack in the system, the HVESS paramete...";
CM_ BO_ 2364684286 "High Voltage Energy Storage Pack 9 Data 5";
CM_ SG_ 2364684286 Hvesp9LowestCellStateOfCharge "HVESP9 Lowest Cell State of Charge: Indicates the state of charge of the lowest-charged cell in this High Voltage Energy Storage Pack instance. 0% means no charge remaining, 100% means the cell is fully charged. If a single state of charge value cove...";
CM_ SG_ 2364684286 Hvesp9HighestCellStateOfCharge "HVESP9 Highest Cell State of Charge: Indicates the state of charge of the highest-charged cell in this High Voltage Energy Storage Pack instance. 0% means no charge remaining, 100% means the cell is fully charged. If a single state of charge value co...";
CM_ SG_ 2364684286 Hvsp9MxmmInstntnsDshrgCrrntLmt "HVESP9 Maximum Instantaneous Discharge Current Limit: The maximum instantaneous current flow limit out of this High Voltage Energy Storage Pack instance. This parameter is defined from the high voltage energy storage pack's point of view and should r...";
CM_ SG_ 2364684286 Hvsp9MxmmInstntnsChrgCrrntLmt "HVESP9 Maximum Instantaneous Charge Current Limit: The maximum instantaneous current flow limit into this High Voltage Energy Storage Pack instance. This parameter is defined from the high voltage energy storage pack's point of view and should reflec...";
CM_ BO_ 2364684542 "High Voltage Energy Storage Pack 9 Data 6";
CM_ SG_ 2364684542 Hvesp9BusVoltage "HVESP9 Bus Voltage: The voltage level of the high voltage bus, as measured by this High Voltage Energy Storage Pack instance on the bus side (not the battery side) of its contactors.This parameter is for one of multiple packs in an HVESS.  If there i...";
CM_ SG_ 2364684542 Hvesp9IgnitionVoltage "HVESP9 Ignition Voltage: The voltage level at the ignition input of this High Voltage Energy Storage Pack controller.This parameter is for one of multiple packs in an HVESS.  If there is only one pack in the system, the HVESS parameters should be use...";
CM_ SG_ 2364684542 Hvesp9IntakeCoolantTemperature "HVESP9 Intake Coolant Temperature: The temperature of liquid coolant as it enters this High Voltage Energy Storage Pack instance.This parameter is for one of multiple packs in an HVESS.  If there is only one pack in the system, the HVESS parameters s...";
CM_ SG_ 2364684542 Hvesp9OutletCoolantTemperature "HVESP9 Outlet Coolant Temperature: The temperature of liquid coolant as it exits this High Voltage Energy Storage Pack instance.This parameter is for one of multiple packs in an HVESS.  If there is only one pack in the system, the HVESS parameters sh...";
CM_ SG_ 2364684542 Hvesp9ElectronicsTemperature "HVESP9 Electronics Temperature: The temperature of the electronics or control modules in this High Voltage Energy Storage Pack instance.  If there are multiple temperature sensors then this parameter would be set to the maximum sensor reading.This pa...";
CM_ SG_ 2364684542 Hvesp9Temperature "HVESP9 Temperature: The temperature of this High Voltage Energy Storage Pack instance. The value may be determined from a unique sensor specifically for this purpose, or by aggregating various temperature sensor readings within the pack.This paramete...";
CM_ BO_ 2364684798 "High Voltage Energy Storage Pack 9 Status 1";
CM_ SG_ 2364684798 Hvesp9HvilStatus "HVESP9 HVIL Status: Status of the High Voltage Interlock Loop from the viewpoint of this High Voltage Energy Storage Pack instance.This parameter is for one of multiple packs in an HVESS. If there is only one pack in the system, the HVESS parameters ...";
CM_ SG_ 2364684798 Hvesp9InertiaSwitchStatus "HVESP9 Inertia Switch Status: Switch indicating that an impact has been sensed by this High Voltage Energy Storage Pack instance. The impact indication may require action by another controller, or by this HVES instance itself.  For example, a control...";
CM_ SG_ 2364684798 Hvesp9StateOfChargeStatus "HVESP9 State of Charge Status: Status of this High Voltage Energy Storage Pack instance State of Charge (SOC).  Note:  A given HVES controller may not support all of the states.This parameter is for one of multiple packs in an HVESS.  If there is onl...";
CM_ SG_ 2364684798 Hvesp9CellBalanceStatus "HVESP9 Cell Balance Status: Indicates whether or not the cells in this High Voltage Energy Storage Pack instance are balanced.This parameter is for one of multiple packs in an HVESS.  If there is only one pack in the system, the HVESS parameters shou...";
CM_ SG_ 2364684798 Hvesp9CellBalancingActive "HVESP9 Cell Balancing Active: Indicates whether or not the cells in this High Voltage Energy Storage Pack instance are currently being balanced.This parameter is for one of multiple packs in an HVESS.  If there is only one pack in the system, the HVE...";
CM_ SG_ 2364684798 Hvesp9InternalChargerStatus "HVESP9 Internal Charger Status: Indicates that the charger in this HVES instance is on.  External chargers may use the External Energy Source Connection Status (SPN 7898) and related SPs.This parameter is for one of multiple packs in an HVESS. If the...";
CM_ SG_ 2364684798 Hvesp9OperationalStatus "HVESP9 Operational Status: Provides feedback on where this High Voltage Energy Storage Pack instance is in its operating spectrum, and includes feedback in response to the Operation Consent [i.e. SPN 14329 (HVESP9 Operation Consent)] and Power Down C...";
CM_ SG_ 2364684798 Hvesp9Status1Counter "HVESP9 Status 1 Counter: The message counter is used to detect situations where the transmitting ECU malfunction repeats the same frame all the time. The receiver of the information may use the counter parameter to detect this situation. The transmit...";
CM_ SG_ 2364684798 Hvesp9Status1Crc "HVESP9 Status 1 CRC: The CRC is defined as follows: - Length: 8 bits- Polynomial: x^8+x^5+x^3+x^2+x+1- Initial Value: FFh- Input Data Reflection: Not reflected- Result Data Reflection: Not reflected- XOR value: FFh SAE makes no claim of the functiona...";
CM_ SG_ 2364684798 Hvsp9HghVltgBsPstvCnttrStt "HVESP9 High-Voltage Bus (Positive) Contactor State: Position of this High Voltage Energy Storage Pack instance positive side bus contactor.  When this contactor is closed, the positive side of this HVES instance is connected to the positive side of t...";
CM_ SG_ 2364684798 Hvsp9HghVltgBsNgtvCnttrStt "HVESP9 High-Voltage Bus (Negative) Contactor State: Position of this High Voltage Energy Storage Pack instance negative side bus contactor. When this contactor is closed, the negative side of this HVES instance is connected to the negative side of th...";
CM_ SG_ 2364684798 Hvsp9HghVltgBsDsnntFrwrnng "HVESP9 High-Voltage Bus Disconnect Forewarning: Indicates that this High Voltage Energy Storage Pack instance is about to disconnect from the high voltage bus due to unacceptable conditions.This parameter is for one of multiple packs in an HVESS. If ...";
CM_ SG_ 2364684798 Hvsp9HghVltgBsPrChrgRlStt "HVESP9 High-Voltage Bus Pre-Charge Relay State: Position of the high-voltage bus contactor pre-charge relay.  When this relay is closed, this High Voltage Energy Storage Pack instance is bringing the high-voltage bus up to its operating level.This pa...";
CM_ SG_ 2364684798 Hvsp9CntrOfPkCnttrStt "HVESP9 Center of Pack Contactor State: Position of the center high-voltage contactor. When this contactor is closed, the positive half of this High Voltage Energy Storage Pack instance is connected to the negative half. If a system controls the posit...";
CM_ SG_ 2364684798 Hvsp9HghVltgBsAtvIsltnTstStts "HVESP9 High-Voltage Bus Active Isolation Test Status: Status of the high-voltage bus electrical active isolation test as performed by this High Voltage Energy Storage Pack instance.This parameter is for one of multiple packs in an HVESS. If there is ...";
CM_ SG_ 2364684798 Hvsp9HghVltgBsPssvIsltnTstStts "HVESP9 High-Voltage Bus Passive Isolation Test Status: Status of the high-voltage bus electrical passive isolation test as performed by this High Voltage Energy Storage Pack instance.This parameter is for one of multiple packs in an HVESS. If there i...";
CM_ SG_ 2364684798 Hvsp9HghVltgBsCnntnStts "HVESP9 High-Voltage Bus Connection Status: This parameter provides high level feedback on this High Voltage Energy Storage Pack instance high voltage bus connection. For specific contactor information, see SPN 14371 (HVESP9 High-Voltage Bus (Positive...";
CM_ BO_ 2364685054 "High Voltage Energy Storage Pack 9 Data 7";
CM_ SG_ 2364685054 Hvesp9DischargeEnergyCapacity "HVESP9 Discharge Energy Capacity: The amount of stored electrical energy in this High Voltage Energy Storage Pack instance that is available for use by the hybrid or EV system, i.e. 'how full is the tank'. See SPN 14358 (HVESP9 Discharge Capacity) fo...";
CM_ SG_ 2364685054 Hvesp9ChargeEnergyCapacity "HVESP9 Charge Energy Capacity: The amount of unused electrical energy storage available to be filled by charging this High Voltage Energy Storage Pack instance, i.e. 'how much empty space is remaining in the tank'. See SPN 14359 (HVESP9 Charge Capaci...";
CM_ SG_ 2364685054 Hvesp9MaximumChargeVoltageLimit "HVESP9 Maximum Charge Voltage Limit: The maximum voltage level not to be exceeded while charging this High Voltage Energy Storage Pack instance. If this parameter is not supported, the maximum charge voltage should be limited to SPN 14459 (HVESP9 Rec...";
CM_ BO_ 2364685310 "High Voltage Energy Storage Pack 9 Module Status 1";
CM_ SG_ 2364685310 Hvesp9Module1OperationalStatus "HVESP9 Module 1 Operational Status: Operational Status of Module 1 in this High Voltage Energy Storage Pack Instance.  Not Operational is used when the module is initializing or not able to function (e.g. internal module level monitors have failed). ...";
CM_ SG_ 2364685310 Hvesp9Module2OperationalStatus "HVESP9 Module 2 Operational Status: Operational Status of Module 2 in this High Voltage Energy Storage Pack Instance.  Not Operational is used when the module is initializing or not able to function (e.g. internal module level monitors have failed). ...";
CM_ SG_ 2364685310 Hvesp9Module3OperationalStatus "HVESP9 Module 3 Operational Status: Operational Status of Module 3 in this High Voltage Energy Storage Pack Instance.  Not Operational is used when the module is initializing or not able to function (e.g. internal module level monitors have failed). ...";
CM_ SG_ 2364685310 Hvesp9Module4OperationalStatus "HVESP9 Module 4 Operational Status: Operational Status of Module 4 in this High Voltage Energy Storage Pack Instance.  Not Operational is used when the module is initializing or not able to function (e.g. internal module level monitors have failed). ...";
CM_ SG_ 2364685310 Hvesp9Module5OperationalStatus "HVESP9 Module 5 Operational Status: Operational Status of Module 5 in this High Voltage Energy Storage Pack Instance.  Not Operational is used when the module is initializing or not able to function (e.g. internal module level monitors have failed). ...";
CM_ SG_ 2364685310 Hvesp9Module6OperationalStatus "HVESP9 Module 6 Operational Status: Operational Status of Module 6 in this High Voltage Energy Storage Pack Instance.  Not Operational is used when the module is initializing or not able to function (e.g. internal module level monitors have failed). ...";
CM_ SG_ 2364685310 Hvesp9Module7OperationalStatus "HVESP9 Module 7 Operational Status: Operational Status of Module 7 in this High Voltage Energy Storage Pack Instance.  Not Operational is used when the module is initializing or not able to function (e.g. internal module level monitors have failed). ...";
CM_ SG_ 2364685310 Hvesp9Module8OperationalStatus "HVESP9 Module 8 Operational Status: Operational Status of Module 8 in this High Voltage Energy Storage Pack Instance.  Not Operational is used when the module is initializing or not able to function (e.g. internal module level monitors have failed). ...";
CM_ SG_ 2364685310 Hvesp9Module9OperationalStatus "HVESP9 Module 9 Operational Status: Operational Status of Module 9 in this High Voltage Energy Storage Pack Instance.  Not Operational is used when the module is initializing or not able to function (e.g. internal module level monitors have failed). ...";
CM_ SG_ 2364685310 Hvesp9Module10OperationalStatus "HVESP9 Module 10 Operational Status: Operational Status of Module 10 in this High Voltage Energy Storage Pack Instance.  Not Operational is used when the module is initializing or not able to function (e.g. internal module level monitors have failed)...";
CM_ SG_ 2364685310 Hvesp9Module11OperationalStatus "HVESP9 Module 11 Operational Status: Operational Status of Module 11 in this High Voltage Energy Storage Pack Instance.  Not Operational is used when the module is initializing or not able to function (e.g. internal module level monitors have failed)...";
CM_ SG_ 2364685310 Hvesp9Module12OperationalStatus "HVESP9 Module 12 Operational Status: Operational Status of Module 12 in this High Voltage Energy Storage Pack Instance.  Not Operational is used when the module is initializing or not able to function (e.g. internal module level monitors have failed)...";
CM_ SG_ 2364685310 Hvesp9Module13OperationalStatus "HVESP9 Module 13 Operational Status: Operational Status of Module 13 in this High Voltage Energy Storage Pack Instance.  Not Operational is used when the module is initializing or not able to function (e.g. internal module level monitors have failed)...";
CM_ SG_ 2364685310 Hvesp9Module14OperationalStatus "HVESP9 Module 14 Operational Status: Operational Status of Module 14 in this High Voltage Energy Storage Pack Instance.  Not Operational is used when the module is initializing or not able to function (e.g. internal module level monitors have failed)...";
CM_ SG_ 2364685310 Hvesp9Module15OperationalStatus "HVESP9 Module 15 Operational Status: Operational Status of Module 15 in this High Voltage Energy Storage Pack Instance.  Not Operational is used when the module is initializing or not able to function (e.g. internal module level monitors have failed)...";
CM_ SG_ 2364685310 Hvesp9Module16OperationalStatus "HVESP9 Module 16 Operational Status: Operational Status of Module 16 in this High Voltage Energy Storage Pack Instance.  Not Operational is used when the module is initializing or not able to function (e.g. internal module level monitors have failed)...";
CM_ SG_ 2364685310 Hvesp9Module17OperationalStatus "HVESP9 Module 17 Operational Status: Operational Status of Module 17 in this High Voltage Energy Storage Pack Instance.  Not Operational is used when the module is initializing or not able to function (e.g. internal module level monitors have failed)...";
CM_ SG_ 2364685310 Hvesp9Module18OperationalStatus "HVESP9 Module 18 Operational Status: Operational Status of Module 18 in this High Voltage Energy Storage Pack Instance.  Not Operational is used when the module is initializing or not able to function (e.g. internal module level monitors have failed)...";
CM_ SG_ 2364685310 Hvesp9Module19OperationalStatus "HVESP9 Module 19 Operational Status: Operational Status of Module 19 in this High Voltage Energy Storage Pack Instance.  Not Operational is used when the module is initializing or not able to function (e.g. internal module level monitors have failed)...";
CM_ SG_ 2364685310 Hvesp9Module20OperationalStatus "HVESP9 Module 20 Operational Status: Operational Status of Module 20 in this High Voltage Energy Storage Pack Instance.  Not Operational is used when the module is initializing or not able to function (e.g. internal module level monitors have failed)...";
CM_ SG_ 2364685310 Hvesp9Module21OperationalStatus "HVESP9 Module 21 Operational Status: Operational Status of Module 21 in this High Voltage Energy Storage Pack Instance.  Not Operational is used when the module is initializing or not able to function (e.g. internal module level monitors have failed)...";
CM_ SG_ 2364685310 Hvesp9Module22OperationalStatus "HVESP9 Module 22 Operational Status: Operational Status of Module 22 in this High Voltage Energy Storage Pack Instance.  Not Operational is used when the module is initializing or not able to function (e.g. internal module level monitors have failed)...";
CM_ SG_ 2364685310 Hvesp9Module23OperationalStatus "HVESP9 Module 23 Operational Status: Operational Status of Module 23 in this High Voltage Energy Storage Pack Instance.  Not Operational is used when the module is initializing or not able to function (e.g. internal module level monitors have failed)...";
CM_ SG_ 2364685310 Hvesp9Module24OperationalStatus "HVESP9 Module 24 Operational Status: Operational Status of Module 24 in this High Voltage Energy Storage Pack Instance.  Not Operational is used when the module is initializing or not able to function (e.g. internal module level monitors have failed)...";
CM_ SG_ 2364685310 Hvesp9Module25OperationalStatus "HVESP9 Module 25 Operational Status: Operational Status of Module 25 in this High Voltage Energy Storage Pack Instance.  Not Operational is used when the module is initializing or not able to function (e.g. internal module level monitors have failed)...";
CM_ SG_ 2364685310 Hvesp9Module26OperationalStatus "HVESP9 Module 26 Operational Status: Operational Status of Module 26 in this High Voltage Energy Storage Pack Instance.  Not Operational is used when the module is initializing or not able to function (e.g. internal module level monitors have failed)...";
CM_ SG_ 2364685310 Hvesp9Module27OperationalStatus "HVESP9 Module 27 Operational Status: Operational Status of Module 27 in this High Voltage Energy Storage Pack Instance.  Not Operational is used when the module is initializing or not able to function (e.g. internal module level monitors have failed)...";
CM_ SG_ 2364685310 Hvesp9Module28OperationalStatus "HVESP9 Module 28 Operational Status: Operational Status of Module 28 in this High Voltage Energy Storage Pack Instance.  Not Operational is used when the module is initializing or not able to function (e.g. internal module level monitors have failed)...";
CM_ SG_ 2364685310 Hvesp9Module29OperationalStatus "HVESP9 Module 29 Operational Status: Operational Status of Module 29 in this High Voltage Energy Storage Pack Instance.  Not Operational is used when the module is initializing or not able to function (e.g. internal module level monitors have failed)...";
CM_ SG_ 2364685310 Hvesp9Module30OperationalStatus "HVESP9 Module 30 Operational Status: Operational Status of Module 30 in this High Voltage Energy Storage Pack Instance.  Not Operational is used when the module is initializing or not able to function (e.g. internal module level monitors have failed)...";
CM_ SG_ 2364685310 Hvesp9Module31OperationalStatus "HVESP9 Module 31 Operational Status: Operational Status of Module 31 in this High Voltage Energy Storage Pack Instance.  Not Operational is used when the module is initializing or not able to function (e.g. internal module level monitors have failed)...";
CM_ SG_ 2364685310 Hvesp9Module32OperationalStatus "HVESP9 Module 32 Operational Status: Operational Status of Module 32 in this High Voltage Energy Storage Pack Instance.  Not Operational is used when the module is initializing or not able to function (e.g. internal module level monitors have failed)...";
CM_ BO_ 2364685566 "High Voltage Energy Storage Pack 9 Thermal Management System Status 1";
CM_ SG_ 2364685566 Hvsp9ThrmlMngmntSstmSlInptPwr "HVESP9 Thermal Management System SLI Input Power: This is the low-voltage power consumed by this HVES Thermal Management System (TMS).This parameter is for one of multiple packs in an HVESS.  If there is only one pack in the system, the HVESS paramet...";
CM_ SG_ 2364685566 Hvsp9TMtSstHVtIptPw "HVESP9 Thermal Management System High-Voltage Input Power: This is the high-voltage power consumed by this HVES Thermal Management System (TMS).This parameter is for one of multiple packs in an HVESS.  If there is only one pack in the system, the HVE...";
CM_ SG_ 2364685566 Hvsp9ThrmlMngmntSstmCmprssrSpd "HVESP9 Thermal Management System Compressor Speed: When this High Voltage Energy Storage Pack Thermal Management System is equipped with an active cooling system (e.g. air conditioner), this is the Compressor Speed.This parameter is for one of multip...";
CM_ SG_ 2364685566 Hvsp9ThrmlMngmntSstmRltvHmdt "HVESP9 Thermal Management System Relative Humidty: When this High Voltage Energy Storage Pack Thermal Management System is equipped with a relative humidity sensor, this is the  measured Relative Humidity.This parameter is for one of multiple packs i...";
CM_ SG_ 2364685566 Hvsp9ThrmlMngmntSstmHtrStts "HVESP9 Thermal Management System Heater Status: The state of this High Voltage Energy Storage Pack heaterThis parameter is for one of multiple packs in an HVESS.  If there is only one pack in the system, the HVESS parameters should be used. If there ...";
CM_ SG_ 2364685566 Hvsp9ThrmlMngmntSstmHvlStts "HVESP9 Thermal Management System HVIL Status: In multiple HVES configurations, this is the status of the High Voltage Interlock Loop from the viewpoint of this Thermal Management System.00b = HVIL Closed01b = HVIL Open10b = Error11b = Not AvailableTh...";
CM_ SG_ 2364685566 Hvsp9ThrmlMngmntSstmMd "HVESP9 Thermal Management System Mode: Indicates the operating mode of the Thermal Management System.  The heat transfer medium may be (e.g. liquid or air).  The cooling system may be fans, liquid coolant, or a combination of mediums.  The system may...";
CM_ SG_ 2364685566 Hvsp9ThrmlMngmntSstmClntLvl "HVESP9 Thermal Management System Coolant Level: Indicates the coolant level in this HVES Thermal Management System (TMS).This parameter is for one of multiple packs in an HVESS.  If there is only one pack in the system, the HVESS parameters should be...";
CM_ BO_ 2364685822 "High Voltage Energy Storage Pack 9 Data 8";
CM_ SG_ 2364685822 Hvesp9AverageCellVoltage "HVESP9 Average Cell Voltage: The average cell voltage in this High Voltage Energy Storage Pack instance.This parameter is for one of multiple packs in an HVESS.  If there is only one pack in the system, the HVESS parameters should be used. If there a...";
CM_ SG_ 2364685822 Hvsp9HghstCllVltgMdlNmr "HVESP9 Highest Cell Voltage Module Number: Identifies the location of the module containing SPN 14351 (HVESP9 Highest Cell Voltage).This parameter is for one of multiple packs in an HVESS. If there is only one pack in the system, the HVESS parameters...";
CM_ SG_ 2364685822 Hvsp9HghstCllVltgCllNmr "HVESP9 Highest Cell Voltage Cell Number: Identifies the location of SPN 14351 (HVESP9 Highest Cell Voltage) within SPN 14431 (HVESP9 Highest Cell Voltage Module Number).This parameter is for one of multiple packs in an HVESS. If there is only one pac...";
CM_ SG_ 2364685822 Hvsp9LwstCllVltgMdlNmr "HVESP9 Lowest Cell Voltage Module Number: Identifies the location of the module containing SPN 14352 (HVESP9 Lowest Cell Voltage).This parameter is for one of multiple packs in an HVESS. If there is only one pack in the system, the HVESS parameters s...";
CM_ SG_ 2364685822 Hvsp9LwstCllVltgCllNmr "HVESP9 Lowest Cell Voltage Cell Number: Identifies the location of SPN 14352 (HVESP9 Lowest Cell Voltage) within SPN 14433 (HVESP9 Lowest Cell Voltage Module Number).This parameter is for one of multiple packs in an HVESS. If there is only one pack i...";
CM_ BO_ 2364686078 "High Voltage Energy Storage Pack 9 Data 9";
CM_ SG_ 2364686078 Hvsp9HghstCllTmprtrMdlNmr "HVESP9 Highest Cell Temperature Module Number: Identifies the location of the module containing SPN 14354 (HVESP9 Highest Cell Temperature).This parameter is for one of multiple packs in an HVESS. If there is only one pack in the system, the HVESS pa...";
CM_ SG_ 2364686078 Hvsp9HghstCllTmprtrCllNmr "HVESP9 Highest Cell Temperature Cell Number: Identifies the location of SPN 14354 (HVESP9 Highest Cell Temperature) within SPN 14436 (HVESP9 Highest Cell Temperature Module Number).This parameter is for one of multiple packs in an HVESS. If there is ...";
CM_ SG_ 2364686078 Hvsp9LwstCllTmprtrMdlNmr "HVESP9 Lowest Cell Temperature Module Number: Identifies the location of the module containing SPN 14355 (HVESP9 Lowest Cell Temperature).This parameter is for one of multiple packs in an HVESS. If there is only one pack in the system, the HVESS para...";
CM_ SG_ 2364686078 Hvsp9LwstCllTmprtrCllNmr "HVESP9 Lowest Cell Temperature Cell Number: Identifies the location of SPN 14355 (HVESP9 Lowest Cell Temperature) within SPN 14438 (HVESP9 Lowest Cell Temperature Module Number).This parameter is for one of multiple packs in an HVESS. If there is onl...";
CM_ SG_ 2364686078 Hvess9ThermalEventDetected "HVESS9 Thermal Event Detected: A sensor has detected the presence of a thermal event at or near High Voltage Energy Storage Pack instance.00b = No Thermal Event Detected01b = Thermal Event Detected10b = Error11b = Not availableThis parameter is for o...";
CM_ SG_ 2364686078 Hvsp9Dt9EmdddIntgrtSpprt "HVESP9 Data 9 Embedded Integrity Support: Indicates SPN 23000 (HVESP9 Data 9 CRC) and SPN 22999 (HVESP9 Data 9 Counter) are supported by the sender.00b = Embedded CRC and Counter are supported by the sender01b = Protection is provided using an extern...";
CM_ SG_ 2364686078 Hvesp9Data9Counter "HVESP9 Data 9 Counter: The message counter is used to detect situations where the transmitting ECU malfunction repeats the same frame all the time. The receiver of the information may use the counter parameter to detect this situation. The transmitti...";
CM_ SG_ 2364686078 Hvesp9Data9Crc "HVESP9 Data 9 CRC: The CRC is defined as follows: - Length: 8 bits- Polynomial: x^8+x^5+x^3+x^2+x+1- Initial Value: FFh- Input Data Reflection: Not reflected- Result Data Reflection: Not reflected- XOR value: FFh SAE makes no claim of the functional ...";
CM_ BO_ 2364686334 "High Voltage Energy Storage Pack 9 Data 10";
CM_ SG_ 2364686334 Hvsp9HghstCllSttOfChrgMdlNmr "HVESP9 Highest Cell State of Charge Module Number: Identifies the location of the module containing SPN 14364 (HVESP9 Highest Cell State of Charge).This parameter is for one of multiple packs in an HVESS. If there is only one pack in the system, the ...";
CM_ SG_ 2364686334 Hvsp9HghstCllSttOfChrgCllNmr "HVESP9 Highest Cell State of Charge Cell Number: Identifies the location of SPN 14364 (HVESP9 Highest Cell State of Charge) within SPN 14440 (HVESP9 Highest Cell State of Charge Module Number).This parameter is for one of multiple packs in an HVESS. ...";
CM_ SG_ 2364686334 Hvsp9LwstCllSttOfChrgMdlNmr "HVESP9 Lowest Cell State of Charge Module Number: Identifies the location of the module containing SPN 14363 (HVESP9 Lowest Cell State of Charge).This parameter is for one of multiple packs in an HVESS. If there is only one pack in the system, the HV...";
CM_ SG_ 2364686334 Hvsp9LwstCllSttOfChrgCllNmr "HVESP9 Lowest Cell State of Charge Cell Number: Identifies the location of SPN 14363 (HVESP9 Lowest Cell State of Charge) within SPN 14442 (HVESP9 Lowest Cell State of Charge Module Number).This parameter is for one of multiple packs in an HVESS. If ...";
CM_ SG_ 2364686334 Hvsp9HghVltgBsAtvIsltnTstRslts "HVESP9 High-Voltage Bus Active Isolation Test Results: The isolation resistance expressed in Ohms per Volt that resulted from the High-Voltage Bus Active Isolation Test.See SPN 14376 (HVESP9 High-Voltage Bus Active Isolation Test Status) for test sta...";
CM_ SG_ 2364686334 Hvsp9HghVltgBsPssvIsltnTstRslts "HVESP9 High-Voltage Bus Passive Isolation Test Results: The isolation resistance expressed in Ohms per Volt that resulted from the High-Voltage Bus Passive Isolation Test.See SPN 14377 (HVESP9 High-Voltage Bus Passive Isolation Test Status) for test ...";
CM_ BO_ 2364686590 "High Voltage Energy Storage Pack 9 Data 11";
CM_ SG_ 2364686590 Hvesp9ActualChargeRate "HVESP9 Actual Charge Rate: This signal represents the actual present charge rate of this High Voltage Energy Storage Pack instance.This parameter is for one of multiple packs in an HVESS. If there is only one pack in the system, the HVESS parameters ...";
CM_ SG_ 2364686590 Hvsp9BsVltgNgtvTChsssGrndVltg "HVESP9 Bus Voltage Negative to Chassis Ground Voltage: Voltage difference between the most negative terminal of the HVES battery and chassis measured on the hybrid or EV system bus side (not the battery side) of any HVES contained output contactor.  ...";
CM_ SG_ 2364686590 Hvsp9VltgLvlNgtvTChsssGrndVltg "HVESP9 Voltage Level Negative to Chassis Ground Voltage: Voltage difference between the most negative terminal of the HVES battery and chassis measured at the battery side of any HVES contained output contactor.  This voltage may be used for system l...";
CM_ BO_ 2364686846 "High Voltage Energy Storage Pack 10 Status 2";
CM_ SG_ 2364686846 Hvsp10DshrgPwrLmtDTSttOfChrg "HVESP10 Discharge Power Limit Due to State of Charge: Indicates whether or not discharge power of this HVES instance is being limited due to state of charge.This parameter is for one of multiple packs in an HVESS.  If there is only one pack in the sy...";
CM_ SG_ 2364686846 Hvsp10DshrgPwrLmtDTBttrTmprtr "HVESP10 Discharge Power Limit Due to Battery Temperature: Indicates whether or not discharge power of this HVES instance is being limited due to battery temperature.This parameter is for one of multiple packs in an HVESS.  If there is only one pack i...";
CM_ SG_ 2364686846 Hvsp10DsPwLtDTBttDstCdt "HVESP10 Discharge Power Limit Due to Battery Diagnostic Condition: Indicates whether or not discharge power of this HVES instance is being limited due to a battery diagnostic condition.This parameter is for one of multiple packs in an HVESS.  If ther...";
CM_ SG_ 2364686846 Hvsp10DsPwLtDTBttOCVt "HVESP10 Discharge Power Limit Due to Battery or Cell Voltage: Indicates whether or not discharge power of this HVES instance is being limited due to a battery or cell voltage level.This parameter is for one of multiple packs in an HVESS.  If there is...";
CM_ SG_ 2364686846 Hvsp10DshrgPwrLmtDTBttrCrrnt "HVESP10 Discharge Power Limit Due to Battery Current: Indicates whether or not discharge power of this HVES instance is being limited due to battery current.This parameter is for one of multiple packs in an HVESS.  If there is only one pack in the sy...";
CM_ SG_ 2364686846 Hvsp10DshrgPwrLmtDTAnUndfndCs "HVESP10 Discharge Power Limit Due to an Undefined Cause: Indicates whether or not discharge power of this HVES instance is being limited due to an undefined cause.This parameter is for one of multiple packs in an HVESS.  If there is only one pack in ...";
CM_ SG_ 2364686846 Hvsp10ChrgPwrLmtDTSttOfChrg "HVESP10 Charge Power Limit Due to State of Charge: Indicates whether or not charge power of this HVES instance is being limited due to state of charge.This parameter is for one of multiple packs in an HVESS.  If there is only one pack in the system, ...";
CM_ SG_ 2364686846 Hvsp10ChrgPwrLmtDTBttrTmprtr "HVESP10 Charge Power Limit Due to Battery Temperature: Indicates whether or not charge power of this HVES instance is being limited due to battery temperature.This parameter is for one of multiple packs in an HVESS.  If there is only one pack in the ...";
CM_ SG_ 2364686846 Hvsp10CPwLtDTBttDstCdt "HVESP10 Charge Power Limit Due to Battery Diagnostic Condition: Indicates whether or not charge power of this HVES instance is being limited due to a battery diagnostic condition.This parameter is for one of multiple packs in an HVESS.  If there is o...";
CM_ SG_ 2364686846 Hvsp10ChrgPwrLmtDTBttrOrCllVltg "HVESP10 Charge Power Limit Due to Battery or Cell Voltage: Indicates whether or not charge power of this HVES instance is being limited due to a battery or cell voltage level.This parameter is for one of multiple packs in an HVESS.  If there is only ...";
CM_ SG_ 2364686846 Hvsp10ChrgPwrLmtDTBttrCrrnt "HVESP10 Charge Power Limit Due to Battery Current: Indicates whether or not charge power of this HVES instance is being limited due to battery current.This parameter is for one of multiple packs in an HVESS.  If there is only one pack in the system, ...";
CM_ SG_ 2364686846 Hvsp10ChrgPwrLmtDTAnUndfndCs "HVESP10 Charge Power Limit Due to an Undefined Cause: Indicates whether or not charge power of this HVES instance is being limited due to an undefined cause.This parameter is for one of multiple packs in an HVESS.  If there is only one pack in the sy...";
CM_ BO_ 2364687102 "High Voltage Energy Storage Pack 10 Data 1";
CM_ SG_ 2364687102 Hvesp10AvailableDischargePower "HVESP10 Available Discharge Power: The rate at which this High Voltage Energy Storage Pack instance can currently provide energy for propulsion or other uses.This parameter is for one of multiple packs in an HVESS.  If there is only one pack in the s...";
CM_ SG_ 2364687102 Hvesp10AvailableChargePower "HVESP10 Available Charge Power: The rate at which this High Voltage Energy Storage Pack instance can currently receive energy from a regenerative or recharging system.This parameter is for one of multiple packs in an HVESS.  If there is only one pack...";
CM_ SG_ 2364687102 Hvesp10VoltageLevel "HVESP10 Voltage Level: The voltage level of this High Voltage Energy Storage Pack instance. This parameter should be synchronized with SPN 14492 (HVESP10 Current) such that a realized power value can be calculated. If the HVES component physically co...";
CM_ SG_ 2364687102 Hvesp10Current "HVESP10 Current: The current in or out of this High Voltage Energy Storage Pack instance. This parameter should be synchronized with SPN 14491 (HVESP10 Voltage Level) such that a realized power value can be calculated. This parameter is defined from ...";
CM_ BO_ 2364687358 "High Voltage Energy Storage Pack 10 Data 2";
CM_ SG_ 2364687358 Hvesp10FastUpdateStateOfCharge "HVESP10 Fast Update State of Charge: Indicates this High Voltage Energy Storage Pack instance state of charge. 0% means no charge remaining, 100% means the system is fully charged in terms of physical limits of this energy storage pack instance. Acce...";
CM_ SG_ 2364687358 Hvesp10HighestCellVoltage "HVESP10 Highest Cell Voltage: The highest voltage level reported by any cell in this High Voltage Energy Storage Pack instance. If a single voltage sensor covers more than one cell, the value in this parameter is for the smallest group of cells measu...";
CM_ SG_ 2364687358 Hvesp10LowestCellVoltage "HVESP10 Lowest Cell Voltage: The lowest voltage level reported by any cell in this High Voltage Energy Storage Pack instance. If a single voltage sensor covers more than one cell, the value in this parameter is for the smallest group of cells measure...";
CM_ SG_ 2364687358 Hvsp10CllVltgDffrntlStts "HVESP10 Cell Voltage Differential Status: Indicates whether or not the differential between the highest and lowest cell voltages are within acceptable limits, according to this High Voltage Energy Storage Pack instance. The actual voltage differentia...";
CM_ BO_ 2364687614 "High Voltage Energy Storage Pack 10 Data 3";
CM_ SG_ 2364687614 Hvesp10HighestCellTemperature "HVESP10 Highest Cell Temperature: The highest temperature level reported by any cell in this High Voltage Energy Storage Pack instance. If a single temperature sensor covers more than one cell, the value in this parameter is for the smallest group of...";
CM_ SG_ 2364687614 Hvesp10LowestCellTemperature "HVESP10 Lowest Cell Temperature: The lowest temperature level reported by any cell in this High Voltage Energy Storage Pack instance. If a single temperature sensor covers more than one cell, the value in this parameter is for the smallest group of c...";
CM_ SG_ 2364687614 Hvesp10AverageCellTemperature "HVESP10 Average Cell Temperature: The average temperature level of all cells in this High Voltage Energy Storage Pack instance.This parameter is for one of multiple packs in an HVESS.  If there is only one pack in the system, the HVESS parameters sho...";
CM_ SG_ 2364687614 Hvsp10CllTmprtrDffrntlStts "HVESP10 Cell Temperature Differential Status: Indicates whether or not the differential between the highest and lowest cell temperatures are within acceptable limits per this High Voltage Energy Storage Pack instance. The actual temperature different...";
CM_ BO_ 2364687870 "High Voltage Energy Storage Pack 10 Data 4";
CM_ SG_ 2364687870 Hvesp10DischargeCapacity "HVESP10 Discharge Capacity: The amount of stored electrical charge in this High Voltage Energy Storage Pack instance that is available for use by the hybrid or EV system, i.e. 'how full is the tank'. See SPN 14531 (HVESP10 Discharge Energy Capacity) ...";
CM_ SG_ 2364687870 Hvesp10ChargeCapacity "HVESP10 Charge Capacity: The amount of unused electrical charge storage in this High Voltage Energy Storage Pack instance that is available to be filled by charging, i.e. 'how much empty space is remaining in the tank'. See SPN 14532 (HVESP10 Charge ...";
CM_ SG_ 2364687870 Hvesp10CellBalancingCount "HVESP10 Cell Balancing Count: The number of cells that are currently being balanced in this High Voltage Energy Storage Pack instance.This parameter is for one of multiple packs in an HVESS.  If there is only one pack in the system, the HVESS paramet...";
CM_ BO_ 2364688126 "High Voltage Energy Storage Pack 10 Data 5";
CM_ SG_ 2364688126 Hvesp10LowestCellStateOfCharge "HVESP10 Lowest Cell State of Charge: Indicates the state of charge of the lowest-charged cell in this High Voltage Energy Storage Pack instance. 0% means no charge remaining, 100% means the cell is fully charged. If a single state of charge value cov...";
CM_ SG_ 2364688126 Hvesp10HighestCellStateOfCharge "HVESP10 Highest Cell State of Charge: Indicates the state of charge of the highest-charged cell in this High Voltage Energy Storage Pack instance. 0% means no charge remaining, 100% means the cell is fully charged. If a single state of charge value c...";
CM_ SG_ 2364688126 Hvsp10MxmmInstntnsDshrgCrrntLmt "HVESP10 Maximum Instantaneous Discharge Current Limit: The maximum instantaneous current flow limit out of this High Voltage Energy Storage Pack instance. This parameter is defined from the high voltage energy storage pack's point of view and should ...";
CM_ SG_ 2364688126 Hvsp10MxmmInstntnsChrgCrrntLmt "HVESP10 Maximum Instantaneous Charge Current Limit: The maximum instantaneous current flow limit into this High Voltage Energy Storage Pack instance. This parameter is defined from the high voltage energy storage pack's point of view and should refle...";
CM_ BO_ 2364688382 "High Voltage Energy Storage Pack 10 Data 6";
CM_ SG_ 2364688382 Hvesp10BusVoltage "HVESP10 Bus Voltage: The voltage level of the high voltage bus, as measured by this High Voltage Energy Storage Pack instance on the bus side (not the battery side) of its contactors.This parameter is for one of multiple packs in an HVESS.  If there ...";
CM_ SG_ 2364688382 Hvesp10IgnitionVoltage "HVESP10 Ignition Voltage: The voltage level at the ignition input of this High Voltage Energy Storage Pack controller.This parameter is for one of multiple packs in an HVESS.  If there is only one pack in the system, the HVESS parameters should be us...";
CM_ SG_ 2364688382 Hvesp10IntakeCoolantTemperature "HVESP10 Intake Coolant Temperature: The temperature of liquid coolant as it enters this High Voltage Energy Storage Pack instance.This parameter is for one of multiple packs in an HVESS.  If there is only one pack in the system, the HVESS parameters ...";
CM_ SG_ 2364688382 Hvesp10OutletCoolantTemperature "HVESP10 Outlet Coolant Temperature: The temperature of liquid coolant as it exits this High Voltage Energy Storage Pack instance.This parameter is for one of multiple packs in an HVESS.  If there is only one pack in the system, the HVESS parameters s...";
CM_ SG_ 2364688382 Hvesp10ElectronicsTemperature "HVESP10 Electronics Temperature: The temperature of the electronics or control modules in this High Voltage Energy Storage Pack instance.  If there are multiple temperature sensors then this parameter would be set to the maximum sensor reading.This p...";
CM_ SG_ 2364688382 Hvesp10Temperature "HVESP10 Temperature: The temperature of this High Voltage Energy Storage Pack instance. The value may be determined from a unique sensor specifically for this purpose, or by aggregating various temperature sensor readings within the pack.This paramet...";
CM_ BO_ 2364688638 "High Voltage Energy Storage Pack 10 Status 1";
CM_ SG_ 2364688638 Hvesp10HvilStatus "HVESP10 HVIL Status: Status of the High Voltage Interlock Loop from the viewpoint of this High Voltage Energy Storage Pack instance.This parameter is for one of multiple packs in an HVESS. If there is only one pack in the system, the HVESS parameters...";
CM_ SG_ 2364688638 Hvesp10InertiaSwitchStatus "HVESP10 Inertia Switch Status: Switch indicating that an impact has been sensed by this High Voltage Energy Storage Pack instance. The impact indication may require action by another controller, or by this HVES instance itself.  For example, a contro...";
CM_ SG_ 2364688638 Hvesp10StateOfChargeStatus "HVESP10 State of Charge Status: Status of this High Voltage Energy Storage Pack instance State of Charge (SOC).  Note:  A given HVES controller may not support all of the states.This parameter is for one of multiple packs in an HVESS.  If there is on...";
CM_ SG_ 2364688638 Hvesp10CellBalanceStatus "HVESP10 Cell Balance Status: Indicates whether or not the cells in this High Voltage Energy Storage Pack instance are balanced.This parameter is for one of multiple packs in an HVESS.  If there is only one pack in the system, the HVESS parameters sho...";
CM_ SG_ 2364688638 Hvesp10CellBalancingActive "HVESP10 Cell Balancing Active: Indicates whether or not the cells in this High Voltage Energy Storage Pack instance are currently being balanced.This parameter is for one of multiple packs in an HVESS.  If there is only one pack in the system, the HV...";
CM_ SG_ 2364688638 Hvesp10InternalChargerStatus "HVESP10 Internal Charger Status: Indicates that the charger in this HVES instance is on.  External chargers may use the External Energy Source Connection Status (SPN 7898) and related SPs.This parameter is for one of multiple packs in an HVESS. If th...";
CM_ SG_ 2364688638 Hvesp10OperationalStatus "HVESP10 Operational Status: Provides feedback on where this High Voltage Energy Storage Pack instance is in its operating spectrum, and includes feedback in response to the Operation Consent [i.e. SPN 14472 (HVESP10 Operation Consent)] and Power Down...";
CM_ SG_ 2364688638 Hvesp10Status1Counter "HVESP10 Status 1 Counter: The message counter is used to detect situations where the transmitting ECU malfunction repeats the same frame all the time. The receiver of the information may use the counter parameter to detect this situation. The transmi...";
CM_ SG_ 2364688638 Hvesp10Status1Crc "HVESP10 Status 1 CRC: The CRC is defined as follows: - Length: 8 bits- Polynomial: x^8+x^5+x^3+x^2+x+1- Initial Value: FFh- Input Data Reflection: Not reflected- Result Data Reflection: Not reflected- XOR value: FFh SAE makes no claim of the function...";
CM_ SG_ 2364688638 Hvsp10HghVltgBsPstvCnttrStt "HVESP10 High-Voltage Bus (Positive) Contactor State: Position of this High Voltage Energy Storage Pack instance positive side bus contactor.  When this contactor is closed, the positive side of this HVES instance is connected to the positive side of ...";
CM_ SG_ 2364688638 Hvsp10HghVltgBsNgtvCnttrStt "HVESP10 High-Voltage Bus (Negative) Contactor State: Position of this High Voltage Energy Storage Pack instance negative side bus contactor. When this contactor is closed, the negative side of this HVES instance is connected to the negative side of t...";
CM_ SG_ 2364688638 Hvsp10HghVltgBsDsnntFrwrnng "HVESP10 High-Voltage Bus Disconnect Forewarning: Indicates that this High Voltage Energy Storage Pack instance is about to disconnect from the high voltage bus due to unacceptable conditions.This parameter is for one of multiple packs in an HVESS. If...";
CM_ SG_ 2364688638 Hvsp10HghVltgBsPrChrgRlStt "HVESP10 High-Voltage Bus Pre-Charge Relay State: Position of the high-voltage bus contactor pre-charge relay.  When this relay is closed, this High Voltage Energy Storage Pack instance is bringing the high-voltage bus up to its operating level.This p...";
CM_ SG_ 2364688638 Hvsp10CntrOfPkCnttrStt "HVESP10 Center of Pack Contactor State: Position of the center high-voltage contactor. When this contactor is closed, the positive half of this High Voltage Energy Storage Pack instance is connected to the negative half. If a system controls the posi...";
CM_ SG_ 2364688638 Hvsp10HghVltgBsAtvIsltnTstStts "HVESP10 High-Voltage Bus Active Isolation Test Status: Status of the high-voltage bus electrical active isolation test as performed by this High Voltage Energy Storage Pack instance.This parameter is for one of multiple packs in an HVESS. If there is...";
CM_ SG_ 2364688638 Hvsp10HghVltgBsPssvIsltnTstStts "HVESP10 High-Voltage Bus Passive Isolation Test Status: Status of the high-voltage bus electrical passive isolation test as performed by this High Voltage Energy Storage Pack instance.This parameter is for one of multiple packs in an HVESS. If there ...";
CM_ SG_ 2364688638 Hvsp10HghVltgBsCnntnStts "HVESP10 High-Voltage Bus Connection Status: This parameter provides high level feedback on this High Voltage Energy Storage Pack instance high voltage bus connection. For specific contactor information, see SPN 14514 (HVESP10 High-Voltage Bus (Positi...";
CM_ BO_ 2364688894 "High Voltage Energy Storage Pack 10 Data 7";
CM_ SG_ 2364688894 Hvesp10DischargeEnergyCapacity "HVESP10 Discharge Energy Capacity: The amount of stored electrical energy in this High Voltage Energy Storage Pack instance that is available for use by the hybrid or EV system, i.e. 'how full is the tank'. See SPN 14501 (HVESP10 Discharge Capacity) ...";
CM_ SG_ 2364688894 Hvesp10ChargeEnergyCapacity "HVESP10 Charge Energy Capacity: The amount of unused electrical energy storage available to be filled by charging this High Voltage Energy Storage Pack instance, i.e. 'how much empty space is remaining in the tank'. See SPN 14502 (HVESP10 Charge Capa...";
CM_ SG_ 2364688894 Hvsp10MxmmChrgVltgLmt "HVESP10 Maximum Charge Voltage Limit: The maximum voltage level not to be exceeded while charging this High Voltage Energy Storage Pack instance. If this parameter is not supported, the maximum charge voltage should be limited to SPN 14602 (HVESP10 R...";
CM_ BO_ 2364689150 "High Voltage Energy Storage Pack 10 Module Status 1";
CM_ SG_ 2364689150 Hvesp10Module1OperationalStatus "HVESP10 Module 1 Operational Status: Operational Status of Module 1 in this High Voltage Energy Storage Pack Instance.  Not Operational is used when the module is initializing or not able to function (e.g. internal module level monitors have failed)....";
CM_ SG_ 2364689150 Hvesp10Module2OperationalStatus "HVESP10 Module 2 Operational Status: Operational Status of Module 2 in this High Voltage Energy Storage Pack Instance.  Not Operational is used when the module is initializing or not able to function (e.g. internal module level monitors have failed)....";
CM_ SG_ 2364689150 Hvesp10Module3OperationalStatus "HVESP10 Module 3 Operational Status: Operational Status of Module 3 in this High Voltage Energy Storage Pack Instance.  Not Operational is used when the module is initializing or not able to function (e.g. internal module level monitors have failed)....";
CM_ SG_ 2364689150 Hvesp10Module4OperationalStatus "HVESP10 Module 4 Operational Status: Operational Status of Module 4 in this High Voltage Energy Storage Pack Instance.  Not Operational is used when the module is initializing or not able to function (e.g. internal module level monitors have failed)....";
CM_ SG_ 2364689150 Hvesp10Module5OperationalStatus "HVESP10 Module 5 Operational Status: Operational Status of Module 5 in this High Voltage Energy Storage Pack Instance.  Not Operational is used when the module is initializing or not able to function (e.g. internal module level monitors have failed)....";
CM_ SG_ 2364689150 Hvesp10Module6OperationalStatus "HVESP10 Module 6 Operational Status: Operational Status of Module 6 in this High Voltage Energy Storage Pack Instance.  Not Operational is used when the module is initializing or not able to function (e.g. internal module level monitors have failed)....";
CM_ SG_ 2364689150 Hvesp10Module7OperationalStatus "HVESP10 Module 7 Operational Status: Operational Status of Module 7 in this High Voltage Energy Storage Pack Instance.  Not Operational is used when the module is initializing or not able to function (e.g. internal module level monitors have failed)....";
CM_ SG_ 2364689150 Hvesp10Module8OperationalStatus "HVESP10 Module 8 Operational Status: Operational Status of Module 8 in this High Voltage Energy Storage Pack Instance.  Not Operational is used when the module is initializing or not able to function (e.g. internal module level monitors have failed)....";
CM_ SG_ 2364689150 Hvesp10Module9OperationalStatus "HVESP10 Module 9 Operational Status: Operational Status of Module 9 in this High Voltage Energy Storage Pack Instance.  Not Operational is used when the module is initializing or not able to function (e.g. internal module level monitors have failed)....";
CM_ SG_ 2364689150 Hvsp10Mdl10OprtnlStts "HVESP10 Module 10 Operational Status: Operational Status of Module 10 in this High Voltage Energy Storage Pack Instance.  Not Operational is used when the module is initializing or not able to function (e.g. internal module level monitors have failed...";
CM_ SG_ 2364689150 Hvsp10Mdl11OprtnlStts "HVESP10 Module 11 Operational Status: Operational Status of Module 11 in this High Voltage Energy Storage Pack Instance.  Not Operational is used when the module is initializing or not able to function (e.g. internal module level monitors have failed...";
CM_ SG_ 2364689150 Hvsp10Mdl12OprtnlStts "HVESP10 Module 12 Operational Status: Operational Status of Module 12 in this High Voltage Energy Storage Pack Instance.  Not Operational is used when the module is initializing or not able to function (e.g. internal module level monitors have failed...";
CM_ SG_ 2364689150 Hvsp10Mdl13OprtnlStts "HVESP10 Module 13 Operational Status: Operational Status of Module 13 in this High Voltage Energy Storage Pack Instance.  Not Operational is used when the module is initializing or not able to function (e.g. internal module level monitors have failed...";
CM_ SG_ 2364689150 Hvsp10Mdl14OprtnlStts "HVESP10 Module 14 Operational Status: Operational Status of Module 14 in this High Voltage Energy Storage Pack Instance.  Not Operational is used when the module is initializing or not able to function (e.g. internal module level monitors have failed...";
CM_ SG_ 2364689150 Hvsp10Mdl15OprtnlStts "HVESP10 Module 15 Operational Status: Operational Status of Module 15 in this High Voltage Energy Storage Pack Instance.  Not Operational is used when the module is initializing or not able to function (e.g. internal module level monitors have failed...";
CM_ SG_ 2364689150 Hvsp10Mdl16OprtnlStts "HVESP10 Module 16 Operational Status: Operational Status of Module 16 in this High Voltage Energy Storage Pack Instance.  Not Operational is used when the module is initializing or not able to function (e.g. internal module level monitors have failed...";
CM_ SG_ 2364689150 Hvsp10Mdl17OprtnlStts "HVESP10 Module 17 Operational Status: Operational Status of Module 17 in this High Voltage Energy Storage Pack Instance.  Not Operational is used when the module is initializing or not able to function (e.g. internal module level monitors have failed...";
CM_ SG_ 2364689150 Hvsp10Mdl18OprtnlStts "HVESP10 Module 18 Operational Status: Operational Status of Module 18 in this High Voltage Energy Storage Pack Instance.  Not Operational is used when the module is initializing or not able to function (e.g. internal module level monitors have failed...";
CM_ SG_ 2364689150 Hvsp10Mdl19OprtnlStts "HVESP10 Module 19 Operational Status: Operational Status of Module 19 in this High Voltage Energy Storage Pack Instance.  Not Operational is used when the module is initializing or not able to function (e.g. internal module level monitors have failed...";
CM_ SG_ 2364689150 Hvsp10Mdl20OprtnlStts "HVESP10 Module 20 Operational Status: Operational Status of Module 20 in this High Voltage Energy Storage Pack Instance.  Not Operational is used when the module is initializing or not able to function (e.g. internal module level monitors have failed...";
CM_ SG_ 2364689150 Hvsp10Mdl21OprtnlStts "HVESP10 Module 21 Operational Status: Operational Status of Module 21 in this High Voltage Energy Storage Pack Instance.  Not Operational is used when the module is initializing or not able to function (e.g. internal module level monitors have failed...";
CM_ SG_ 2364689150 Hvsp10Mdl22OprtnlStts "HVESP10 Module 22 Operational Status: Operational Status of Module 22 in this High Voltage Energy Storage Pack Instance.  Not Operational is used when the module is initializing or not able to function (e.g. internal module level monitors have failed...";
CM_ SG_ 2364689150 Hvsp10Mdl23OprtnlStts "HVESP10 Module 23 Operational Status: Operational Status of Module 23 in this High Voltage Energy Storage Pack Instance.  Not Operational is used when the module is initializing or not able to function (e.g. internal module level monitors have failed...";
CM_ SG_ 2364689150 Hvsp10Mdl24OprtnlStts "HVESP10 Module 24 Operational Status: Operational Status of Module 24 in this High Voltage Energy Storage Pack Instance.  Not Operational is used when the module is initializing or not able to function (e.g. internal module level monitors have failed...";
CM_ SG_ 2364689150 Hvsp10Mdl25OprtnlStts "HVESP10 Module 25 Operational Status: Operational Status of Module 25 in this High Voltage Energy Storage Pack Instance.  Not Operational is used when the module is initializing or not able to function (e.g. internal module level monitors have failed...";
CM_ SG_ 2364689150 Hvsp10Mdl26OprtnlStts "HVESP10 Module 26 Operational Status: Operational Status of Module 26 in this High Voltage Energy Storage Pack Instance.  Not Operational is used when the module is initializing or not able to function (e.g. internal module level monitors have failed...";
CM_ SG_ 2364689150 Hvsp10Mdl27OprtnlStts "HVESP10 Module 27 Operational Status: Operational Status of Module 27 in this High Voltage Energy Storage Pack Instance.  Not Operational is used when the module is initializing or not able to function (e.g. internal module level monitors have failed...";
CM_ SG_ 2364689150 Hvsp10Mdl28OprtnlStts "HVESP10 Module 28 Operational Status: Operational Status of Module 28 in this High Voltage Energy Storage Pack Instance.  Not Operational is used when the module is initializing or not able to function (e.g. internal module level monitors have failed...";
CM_ SG_ 2364689150 Hvsp10Mdl29OprtnlStts "HVESP10 Module 29 Operational Status: Operational Status of Module 29 in this High Voltage Energy Storage Pack Instance.  Not Operational is used when the module is initializing or not able to function (e.g. internal module level monitors have failed...";
CM_ SG_ 2364689150 Hvsp10Mdl30OprtnlStts "HVESP10 Module 30 Operational Status: Operational Status of Module 30 in this High Voltage Energy Storage Pack Instance.  Not Operational is used when the module is initializing or not able to function (e.g. internal module level monitors have failed...";
CM_ SG_ 2364689150 Hvsp10Mdl31OprtnlStts "HVESP10 Module 31 Operational Status: Operational Status of Module 31 in this High Voltage Energy Storage Pack Instance.  Not Operational is used when the module is initializing or not able to function (e.g. internal module level monitors have failed...";
CM_ SG_ 2364689150 Hvsp10Mdl32OprtnlStts "HVESP10 Module 32 Operational Status: Operational Status of Module 32 in this High Voltage Energy Storage Pack Instance.  Not Operational is used when the module is initializing or not able to function (e.g. internal module level monitors have failed...";
CM_ BO_ 2364689406 "High Voltage Energy Storage Pack 10 Thermal Management System Status 1";
CM_ SG_ 2364689406 Hvsp10ThrmlMngmntSstmSlInptPwr "HVESP10 Thermal Management System SLI Input Power: This is the low-voltage power consumed by this HVES Thermal Management System (TMS).This parameter is for one of multiple packs in an HVESS.  If there is only one pack in the system, the HVESS parame...";
CM_ SG_ 2364689406 Hvsp10TMtSstHVtIptPw "HVESP10 Thermal Management System High-Voltage Input Power: This is the high-voltage power consumed by this HVES Thermal Management System (TMS).This parameter is for one of multiple packs in an HVESS.  If there is only one pack in the system, the HV...";
CM_ SG_ 2364689406 Hvsp10ThrmlMngmntSstmCmprssrSpd "HVESP10 Thermal Management System Compressor Speed: When this High Voltage Energy Storage Pack Thermal Management System is equipped with an active cooling system (e.g. air conditioner), this is the Compressor Speed.This parameter is for one of multi...";
CM_ SG_ 2364689406 Hvsp10ThrmlMngmntSstmRltvHmdt "HVESP10 Thermal Management System Relative Humidty: When this High Voltage Energy Storage Pack Thermal Management System is equipped with a relative humidity sensor, this is the  measured Relative Humidity.This parameter is for one of multiple packs ...";
CM_ SG_ 2364689406 Hvsp10ThrmlMngmntSstmHtrStts "HVESP10 Thermal Management System Heater Status: The state of this High Voltage Energy Storage Pack heaterThis parameter is for one of multiple packs in an HVESS.  If there is only one pack in the system, the HVESS parameters should be used. If there...";
CM_ SG_ 2364689406 Hvsp10ThrmlMngmntSstmHvlStts "HVESP10 Thermal Management System HVIL Status: In multiple HVES configurations, this is the status of the High Voltage Interlock Loop from the viewpoint of this Thermal Management System.00b = HVIL Closed01b = HVIL Open10b = Error11b = Not AvailableT...";
CM_ SG_ 2364689406 Hvsp10ThrmlMngmntSstmMd "HVESP10 Thermal Management System Mode: Indicates the operating mode of the Thermal Management System.  The heat transfer medium may be (e.g. liquid or air).  The cooling system may be fans, liquid coolant, or a combination of mediums.  The system ma...";
CM_ SG_ 2364689406 Hvsp10ThrmlMngmntSstmClntLvl "HVESP10 Thermal Management System Coolant Level: Indicates the coolant level in this HVES Thermal Management System (TMS).This parameter is for one of multiple packs in an HVESS.  If there is only one pack in the system, the HVESS parameters should b...";
CM_ BO_ 2364689662 "High Voltage Energy Storage Pack 10 Data 8";
CM_ SG_ 2364689662 Hvesp10AverageCellVoltage "HVESP10 Average Cell Voltage: The average cell voltage in this High Voltage Energy Storage Pack instance.This parameter is for one of multiple packs in an HVESS.  If there is only one pack in the system, the HVESS parameters should be used. If there ...";
CM_ SG_ 2364689662 Hvsp10HghstCllVltgMdlNmr "HVESP10 Highest Cell Voltage Module Number: Identifies the location of the module containing SPN 14494 (HVESP10 Highest Cell Voltage).This parameter is for one of multiple packs in an HVESS. If there is only one pack in the system, the HVESS paramete...";
CM_ SG_ 2364689662 Hvsp10HghstCllVltgCllNmr "HVESP10 Highest Cell Voltage Cell Number: Identifies the location of SPN 14494 (HVESP10 Highest Cell Voltage) within SPN 14574 (HVESP10 Highest Cell Voltage Module Number).This parameter is for one of multiple packs in an HVESS. If there is only one ...";
CM_ SG_ 2364689662 Hvsp10LwstCllVltgMdlNmr "HVESP10 Lowest Cell Voltage Module Number: Identifies the location of the module containing SPN 14495 (HVESP10 Lowest Cell Voltage).This parameter is for one of multiple packs in an HVESS. If there is only one pack in the system, the HVESS parameters...";
CM_ SG_ 2364689662 Hvsp10LwstCllVltgCllNmr "HVESP10 Lowest Cell Voltage Cell Number: Identifies the location of SPN 14495 (HVESP10 Lowest Cell Voltage) within SPN 14576 (HVESP10 Lowest Cell Voltage Module Number).This parameter is for one of multiple packs in an HVESS. If there is only one pac...";
CM_ BO_ 2364689918 "High Voltage Energy Storage Pack 10 Data 9";
CM_ SG_ 2364689918 Hvsp10HghstCllTmprtrMdlNmr "HVESP10 Highest Cell Temperature Module Number: Identifies the location of the module containing SPN 14497 (HVESP10 Highest Cell Temperature).This parameter is for one of multiple packs in an HVESS. If there is only one pack in the system, the HVESS ...";
CM_ SG_ 2364689918 Hvsp10HghstCllTmprtrCllNmr "HVESP10 Highest Cell Temperature Cell Number: Identifies the location of SPN 14497 (HVESP10 Highest Cell Temperature) within SPN 14579 (HVESP10 Highest Cell Temperature Module Number).This parameter is for one of multiple packs in an HVESS. If there ...";
CM_ SG_ 2364689918 Hvsp10LwstCllTmprtrMdlNmr "HVESP10 Lowest Cell Temperature Module Number: Identifies the location of the module containing SPN 14498 (HVESP10 Lowest Cell Temperature).This parameter is for one of multiple packs in an HVESS. If there is only one pack in the system, the HVESS pa...";
CM_ SG_ 2364689918 Hvsp10LwstCllTmprtrCllNmr "HVESP10 Lowest Cell Temperature Cell Number: Identifies the location of SPN 14498 (HVESP10 Lowest Cell Temperature) within SPN 14581 (HVESP10 Lowest Cell Temperature Module Number).This parameter is for one of multiple packs in an HVESS. If there is ...";
CM_ SG_ 2364689918 Hvess10ThermalEventDetected "HVESS10 Thermal Event Detected: A sensor has detected the presence of a thermal event at or near High Voltage Energy Storage Pack instance.00b = No Thermal Event Detected01b = Thermal Event Detected10b = Error11b = Not availableThis parameter is for ...";
CM_ SG_ 2364689918 Hvsp10Dt9EmdddIntgrtSpprt "HVESP10 Data 9 Embedded Integrity Support: Indicates SPN 23003 (HVESP10 Data 9 CRC) and SPN 23002 (HVESP10 Data 9 Counter) are supported by the sender.00b = Embedded CRC and Counter are supported by the sender01b = Protection is provided using an ext...";
CM_ SG_ 2364689918 Hvesp10Data9Counter "HVESP10 Data 9 Counter: The message counter is used to detect situations where the transmitting ECU malfunction repeats the same frame all the time. The receiver of the information may use the counter parameter to detect this situation. The transmitt...";
CM_ SG_ 2364689918 Hvesp10Data9Crc "HVESP10 Data 9 CRC: The CRC is defined as follows: - Length: 8 bits- Polynomial: x^8+x^5+x^3+x^2+x+1- Initial Value: FFh- Input Data Reflection: Not reflected- Result Data Reflection: Not reflected- XOR value: FFh SAE makes no claim of the functional...";
CM_ BO_ 2364690174 "High Voltage Energy Storage Pack 10 Data 10";
CM_ SG_ 2364690174 Hvsp10HghstCllSttOfChrgMdlNmr "HVESP10 Highest Cell State of Charge Module Number: Identifies the location of the module containing SPN 14507 (HVESP10 Highest Cell State of Charge).This parameter is for one of multiple packs in an HVESS. If there is only one pack in the system, th...";
CM_ SG_ 2364690174 Hvsp10HghstCllSttOfChrgCllNmr "HVESP10 Highest Cell State of Charge Cell Number: Identifies the location of SPN 14507 (HVESP10 Highest Cell State of Charge) within SPN 14583 (HVESP10 Highest Cell State of Charge Module Number).This parameter is for one of multiple packs in an HVES...";
CM_ SG_ 2364690174 Hvsp10LwstCllSttOfChrgMdlNmr "HVESP10 Lowest Cell State of Charge Module Number: Identifies the location of the module containing SPN 14506 (HVESP10 Lowest Cell State of Charge).This parameter is for one of multiple packs in an HVESS. If there is only one pack in the system, the ...";
CM_ SG_ 2364690174 Hvsp10LwstCllSttOfChrgCllNmr "HVESP10 Lowest Cell State of Charge Cell Number: Identifies the location of SPN 14506 (HVESP10 Lowest Cell State of Charge) within SPN 14585 (HVESP10 Lowest Cell State of Charge Module Number).This parameter is for one of multiple packs in an HVESS. ...";
CM_ SG_ 2364690174 Hvsp10HghVltgBsAtvIsltnTstRslts "HVESP10 High-Voltage Bus Active Isolation Test Results: The isolation resistance expressed in Ohms per Volt that resulted from the High-Voltage Bus Active Isolation Test.See SPN 14519 (HVESP10 High-Voltage Bus Active Isolation Test Status) for test s...";
CM_ SG_ 2364690174 Hvsp10HVtBsPssvIstTstRsts "HVESP10 High-Voltage Bus Passive Isolation Test Results: The isolation resistance expressed in Ohms per Volt that resulted from the High-Voltage Bus Passive Isolation Test.See SPN 14520 (HVESP10 High-Voltage Bus Passive Isolation Test Status) for tes...";
CM_ BO_ 2364690430 "High Voltage Energy Storage Pack 10 Data 11";
CM_ SG_ 2364690430 Hvesp10ActualChargeRate "HVESP10 Actual Charge Rate: This signal represents the actual present charge rate of this High Voltage Energy Storage Pack instance.This parameter is for one of multiple packs in an HVESS. If there is only one pack in the system, the HVESS parameters...";
CM_ SG_ 2364690430 Hvsp10BsVltgNgtvTChsssGrndVltg "HVESP10 Bus Voltage Negative to Chassis Ground Voltage: Voltage difference between the most negative terminal of the HVES battery and chassis measured on the hybrid or EV system bus side (not the battery side) of any HVES contained output contactor. ...";
CM_ SG_ 2364690430 Hvsp10VltgLvlNgtvTChsssGrndVltg "HVESP10 Voltage Level Negative to Chassis Ground Voltage: Voltage difference between the most negative terminal of the HVES battery and chassis measured at the battery side of any HVES contained output contactor.  This voltage may be used for system ...";
CM_ BO_ 2566564862 "High Voltage Energy Storage Pack 10 Configuration";
CM_ SG_ 2566564862 Hvesp10NominalVoltage "HVESP10 Nominal Voltage: Per the HVES manufacturer, this is the nominal operating voltage of this High Voltage Energy Storage Pack instance, e.g. '300V' or '600V'.This parameter is for one of multiple packs in an HVESS.  If there is only one pack in ...";
CM_ SG_ 2566564862 Hvesp10CellMaximumVoltageLimit "HVESP10 Cell Maximum Voltage Limit: Per the HVES manufacturer, this is the maximum cell voltage for this High Voltage Energy Storage Pack instance operation.  Operating above this value may damage HVES hardware, or compromise HVES life.This parameter...";
CM_ SG_ 2566564862 Hvesp10CellMinimumVoltageLimit "HVESP10 Cell Minimum Voltage Limit: Per the HVES manufacturer, this is the minimum cell voltage for this High Voltage Energy Storage Pack instance operation.  Operating below this value may damage HVES hardware, or compromise HVES life.This parameter...";
CM_ SG_ 2566564862 Hvsp10RmmnddMnmmOprtngVltg "HVESP10 Recommended Minimum Operating Voltage: Per the HVES manufacturer, this is the minimum recommended voltage level for this High Voltage Energy Storage Pack instance operation.  Operating below this value may compromise HVES life.This parameter ...";
CM_ SG_ 2566564862 Hvsp10RmmnddMxmmOprtngVltg "HVESP10 Recommended Maximum Operating Voltage: Per the HVES manufacturer, this is the maximum recommended voltage level for this High Voltage Energy Storage Pack instance operation.  Operating above this value may compromise HVES life.This parameter ...";
CM_ SG_ 2566564862 Hvsp10RmmnddMnmmSttOfChrg "HVESP10 Recommended Minimum State Of Charge: Per the HVES manufacturer, this is the recommended minimum state of charge for this High Voltage Energy Storage Pack instance operation.  Operating below this value may compromise HVES life.This parameter ...";
CM_ SG_ 2566564862 Hvsp10RmmnddMxmmSttOfChrg "HVESP10 Recommended Maximum State Of Charge: Per the HVES manufacturer, this is the recommended maximum state of charge for this High Voltage Energy Storage Pack instance operation.  Operating above this value may compromise HVES life.This parameter ...";
CM_ SG_ 2566564862 Hvsp10RmmnddMxmmOprtngTmprtr "HVESP10 Recommended Maximum Operating Temperature: Per the HVES manufacturer, this is the recommended maximum temperature for this High Voltage Energy Storage Pack instance operation.  Operating above this value may damage HVES hardware, or compromis...";
CM_ SG_ 2566564862 Hvsp10RmmnddMnmmOprtngTmprtr "HVESP10 Recommended Minimum Operating Temperature: Per the HVES manufacturer, this is the recommended minimum temperature for this High Voltage Energy Storage Pack instance operation.  Operating below this value may damage HVES hardware, or compromis...";
CM_ BO_ 2633673982 "High Voltage Energy Storage Pack 10 History";
CM_ SG_ 2633673982 Hvesp10StateOfHealth "HVESP10 State of Health: This signal represents the expected remaining Life of this High Voltage Energy Storage Pack instance, in percent.  Battery life is a manufacturer-specific measure of how well the energy storage system is functioning relative ...";
CM_ SG_ 2633673982 Hvesp10TotalEnergyThroughput "HVESP10 Total Energy Throughput: The total energy throughput which has flowed through this High Voltage Energy Storage Pack instance.  This parameter is the sum of the absolute values of the Energy into and out of this HVES instance.  This parameter ...";
CM_ SG_ 2633673982 Hvesp10TotalAccumulatedCharge "HVESP10 Total Accumulated Charge: The total accumulated amp hours which have flowed through this High Voltage Energy Storage Pack instance.  This parameter is the sum of the absolute values of the Ampere hours into and out of this HVES instance.  Thi...";
CM_ SG_ 2633673982 Hvesp10TotalLifetimeEnergyInput "HVESP10 Total Lifetime Energy Input: The cumulative energy which has flowed into this High Voltage Energy Storage Pack instance over the lifetime of the battery pack. This parameter is the sum of the Energy into this HVES instance. This value is rese...";
CM_ SG_ 2633673982 Hvsp10CnttrOpnUndrLdCnt "HVESP10 Contactor Open Under Load Count: This signal represents the number of times the contactors inside this High Voltage Energy Storage Pack instance have opened while current is flowing through them.  The current level (that determines if an open...";
CM_ SG_ 2633673982 Hvsp10TtlLftmEnrgOtpt "HVESP10 Total Lifetime Energy Output: The cumulative energy which has flowed out of this High Voltage Energy Storage Pack instance over the lifetime of the battery pack. This parameter is the sum of the Energy out of this HVES instance. This value is...";
BA_DEF_ SG_  "SPN" INT 0 524287;
BA_DEF_ BO_  "VFrameFormat" ENUM  "StandardCAN","ExtendedCAN","reserved","J1939PG";
BA_DEF_DEF_  "SPN" 0;
BA_DEF_DEF_  "VFrameFormat" "J1939PG";
BA_ "SPN" SG_ 2364677630 Hvesp7Module1OperationalStatus 14105;
BA_ "SPN" SG_ 2364677630 Hvesp7Module2OperationalStatus 14106;
BA_ "SPN" SG_ 2364677630 Hvesp7Module3OperationalStatus 14107;
BA_ "SPN" SG_ 2364677630 Hvesp7Module4OperationalStatus 14108;
BA_ "SPN" SG_ 2364677630 Hvesp7Module5OperationalStatus 14109;
BA_ "SPN" SG_ 2364677630 Hvesp7Module6OperationalStatus 14110;
BA_ "SPN" SG_ 2364677630 Hvesp7Module7OperationalStatus 14111;
BA_ "SPN" SG_ 2364677630 Hvesp7Module8OperationalStatus 14112;
BA_ "SPN" SG_ 2364677630 Hvesp7Module9OperationalStatus 14113;
BA_ "SPN" SG_ 2364677630 Hvesp7Module10OperationalStatus 14114;
BA_ "SPN" SG_ 2364677630 Hvesp7Module11OperationalStatus 14115;
BA_ "SPN" SG_ 2364677630 Hvesp7Module12OperationalStatus 14116;
BA_ "SPN" SG_ 2364677630 Hvesp7Module13OperationalStatus 14117;
BA_ "SPN" SG_ 2364677630 Hvesp7Module14OperationalStatus 14118;
BA_ "SPN" SG_ 2364677630 Hvesp7Module15OperationalStatus 14119;
BA_ "SPN" SG_ 2364677630 Hvesp7Module16OperationalStatus 14120;
BA_ "SPN" SG_ 2364677630 Hvesp7Module17OperationalStatus 14121;
BA_ "SPN" SG_ 2364677630 Hvesp7Module18OperationalStatus 14122;
BA_ "SPN" SG_ 2364677630 Hvesp7Module19OperationalStatus 14123;
BA_ "SPN" SG_ 2364677630 Hvesp7Module20OperationalStatus 14124;
BA_ "SPN" SG_ 2364677630 Hvesp7Module21OperationalStatus 14125;
BA_ "SPN" SG_ 2364677630 Hvesp7Module22OperationalStatus 14126;
BA_ "SPN" SG_ 2364677630 Hvesp7Module23OperationalStatus 14127;
BA_ "SPN" SG_ 2364677630 Hvesp7Module24OperationalStatus 14128;
BA_ "SPN" SG_ 2364677630 Hvesp7Module25OperationalStatus 14129;
BA_ "SPN" SG_ 2364677630 Hvesp7Module26OperationalStatus 14130;
BA_ "SPN" SG_ 2364677630 Hvesp7Module27OperationalStatus 14131;
BA_ "SPN" SG_ 2364677630 Hvesp7Module28OperationalStatus 14132;
BA_ "SPN" SG_ 2364677630 Hvesp7Module29OperationalStatus 14133;
BA_ "SPN" SG_ 2364677630 Hvesp7Module30OperationalStatus 14134;
BA_ "SPN" SG_ 2364677630 Hvesp7Module31OperationalStatus 14135;
BA_ "SPN" SG_ 2364677630 Hvesp7Module32OperationalStatus 14136;
BA_ "SPN" SG_ 2364677886 Hvsp7ThrmlMngmntSstmSlInptPwr 14137;
BA_ "SPN" SG_ 2364677886 Hvsp7TMtSstHVtIptPw 14138;
BA_ "SPN" SG_ 2364677886 Hvsp7ThrmlMngmntSstmCmprssrSpd 14139;
BA_ "SPN" SG_ 2364677886 Hvsp7ThrmlMngmntSstmRltvHmdt 14140;
BA_ "SPN" SG_ 2364677886 Hvsp7ThrmlMngmntSstmHtrStts 14141;
BA_ "SPN" SG_ 2364677886 Hvsp7ThrmlMngmntSstmHvlStts 14142;
BA_ "SPN" SG_ 2364677886 Hvsp7ThrmlMngmntSstmMd 14143;
BA_ "SPN" SG_ 2364677886 Hvsp7ThrmlMngmntSstmClntLvl 14144;
BA_ "SPN" SG_ 2364678142 Hvesp7AverageCellVoltage 14149;
BA_ "SPN" SG_ 2364678142 Hvsp7HghstCllVltgMdlNmr 14145;
BA_ "SPN" SG_ 2364678142 Hvsp7HghstCllVltgCllNmr 14146;
BA_ "SPN" SG_ 2364678142 Hvsp7LwstCllVltgMdlNmr 14147;
BA_ "SPN" SG_ 2364678142 Hvsp7LwstCllVltgCllNmr 14148;
BA_ "SPN" SG_ 2364678398 Hvsp7HghstCllTmprtrMdlNmr 14150;
BA_ "SPN" SG_ 2364678398 Hvsp7HghstCllTmprtrCllNmr 14151;
BA_ "SPN" SG_ 2364678398 Hvsp7LwstCllTmprtrMdlNmr 14152;
BA_ "SPN" SG_ 2364678398 Hvsp7LwstCllTmprtrCllNmr 14153;
BA_ "SPN" SG_ 2364678398 Hvess7ThermalEventDetected 21294;
BA_ "SPN" SG_ 2364678398 Hvsp7Dt9EmdddIntgrtSpprt 22992;
BA_ "SPN" SG_ 2364678398 Hvesp7Data9Counter 22993;
BA_ "SPN" SG_ 2364678398 Hvesp7Data9Crc 22994;
BA_ "SPN" SG_ 2364678654 Hvsp7HghstCllSttOfChrgMdlNmr 14154;
BA_ "SPN" SG_ 2364678654 Hvsp7HghstCllSttOfChrgCllNmr 14155;
BA_ "SPN" SG_ 2364678654 Hvsp7LwstCllSttOfChrgMdlNmr 14156;
BA_ "SPN" SG_ 2364678654 Hvsp7LwstCllSttOfChrgCllNmr 14157;
BA_ "SPN" SG_ 2364678654 Hvsp7HghVltgBsAtvIsltnTstRslts 14158;
BA_ "SPN" SG_ 2364678654 Hvsp7HghVltgBsPssvIsltnTstRslts 14159;
BA_ "SPN" SG_ 2364678910 Hvesp7ActualChargeRate 14162;
BA_ "SPN" SG_ 2364678910 Hvsp7BsVltgNgtvTChsssGrndVltg 14160;
BA_ "SPN" SG_ 2364678910 Hvsp7VltgLvlNgtvTChsssGrndVltg 14161;
BA_ "SPN" SG_ 2364679166 Hvsp8DshrgPwrLmtDTSttOfChrg 14191;
BA_ "SPN" SG_ 2364679166 Hvsp8DshrgPwrLmtDTBttrTmprtr 14192;
BA_ "SPN" SG_ 2364679166 Hvsp8DsPwLtDTBttDstCdt 14193;
BA_ "SPN" SG_ 2364679166 Hvsp8DshrgPwrLmtDTBttrOrCllVltg 14194;
BA_ "SPN" SG_ 2364679166 Hvsp8DshrgPwrLmtDTBttrCrrnt 14195;
BA_ "SPN" SG_ 2364679166 Hvsp8DshrgPwrLmtDTAnUndfndCs 14196;
BA_ "SPN" SG_ 2364679166 Hvsp8ChrgPwrLmtDTSttOfChrg 14197;
BA_ "SPN" SG_ 2364679166 Hvsp8ChrgPwrLmtDTBttrTmprtr 14198;
BA_ "SPN" SG_ 2364679166 Hvsp8ChrgPwrLmtDTBttrDgnstCndtn 14199;
BA_ "SPN" SG_ 2364679166 Hvsp8ChrgPwrLmtDTBttrOrCllVltg 14200;
BA_ "SPN" SG_ 2364679166 Hvsp8ChrgPwrLmtDTBttrCrrnt 14201;
BA_ "SPN" SG_ 2364679166 Hvsp8ChrgPwrLmtDTAnUndfndCs 14202;
BA_ "SPN" SG_ 2364679422 Hvesp8AvailableDischargePower 14203;
BA_ "SPN" SG_ 2364679422 Hvesp8AvailableChargePower 14204;
BA_ "SPN" SG_ 2364679422 Hvesp8VoltageLevel 14205;
BA_ "SPN" SG_ 2364679422 Hvesp8Current 14206;
BA_ "SPN" SG_ 2364679678 Hvesp8FastUpdateStateOfCharge 14207;
BA_ "SPN" SG_ 2364679678 Hvesp8HighestCellVoltage 14208;
BA_ "SPN" SG_ 2364679678 Hvesp8LowestCellVoltage 14209;
BA_ "SPN" SG_ 2364679678 Hvsp8CllVltgDffrntlStts 14210;
BA_ "SPN" SG_ 2364679934 Hvesp8HighestCellTemperature 14211;
BA_ "SPN" SG_ 2364679934 Hvesp8LowestCellTemperature 14212;
BA_ "SPN" SG_ 2364679934 Hvesp8AverageCellTemperature 14213;
BA_ "SPN" SG_ 2364679934 Hvsp8CllTmprtrDffrntlStts 14214;
BA_ "SPN" SG_ 2364680190 Hvesp8DischargeCapacity 14215;
BA_ "SPN" SG_ 2364680190 Hvesp8ChargeCapacity 14216;
BA_ "SPN" SG_ 2364680190 Hvesp8CellBalancingCount 14217;
BA_ "SPN" SG_ 2364680446 Hvesp8LowestCellStateOfCharge 14220;
BA_ "SPN" SG_ 2364680446 Hvesp8HighestCellStateOfCharge 14221;
BA_ "SPN" SG_ 2364680446 Hvsp8MxmmInstntnsDshrgCrrntLmt 14218;
BA_ "SPN" SG_ 2364680446 Hvsp8MxmmInstntnsChrgCrrntLmt 14219;
BA_ "SPN" SG_ 2364680702 Hvesp8BusVoltage 14222;
BA_ "SPN" SG_ 2364680702 Hvesp8IgnitionVoltage 14223;
BA_ "SPN" SG_ 2364680702 Hvesp8IntakeCoolantTemperature 14224;
BA_ "SPN" SG_ 2364680702 Hvesp8OutletCoolantTemperature 14225;
BA_ "SPN" SG_ 2364680702 Hvesp8ElectronicsTemperature 14226;
BA_ "SPN" SG_ 2364680702 Hvesp8Temperature 14227;
BA_ "SPN" SG_ 2364680958 Hvesp8HvilStatus 14235;
BA_ "SPN" SG_ 2364680958 Hvesp8InertiaSwitchStatus 14236;
BA_ "SPN" SG_ 2364680958 Hvesp8StateOfChargeStatus 14237;
BA_ "SPN" SG_ 2364680958 Hvesp8CellBalanceStatus 14238;
BA_ "SPN" SG_ 2364680958 Hvesp8CellBalancingActive 14239;
BA_ "SPN" SG_ 2364680958 Hvesp8InternalChargerStatus 14240;
BA_ "SPN" SG_ 2364680958 Hvesp8OperationalStatus 14242;
BA_ "SPN" SG_ 2364680958 Hvesp8Status1Counter 14243;
BA_ "SPN" SG_ 2364680958 Hvesp8Status1Crc 14244;
BA_ "SPN" SG_ 2364680958 Hvsp8HghVltgBsPstvCnttrStt 14228;
BA_ "SPN" SG_ 2364680958 Hvsp8HghVltgBsNgtvCnttrStt 14229;
BA_ "SPN" SG_ 2364680958 Hvsp8HghVltgBsDsnntFrwrnng 14230;
BA_ "SPN" SG_ 2364680958 Hvsp8HghVltgBsPrChrgRlStt 14231;
BA_ "SPN" SG_ 2364680958 Hvsp8CntrOfPkCnttrStt 14232;
BA_ "SPN" SG_ 2364680958 Hvsp8HghVltgBsAtvIsltnTstStts 14233;
BA_ "SPN" SG_ 2364680958 Hvsp8HghVltgBsPssvIsltnTstStts 14234;
BA_ "SPN" SG_ 2364680958 Hvsp8HghVltgBsCnntnStts 14241;
BA_ "SPN" SG_ 2364681214 Hvesp8DischargeEnergyCapacity 14245;
BA_ "SPN" SG_ 2364681214 Hvesp8ChargeEnergyCapacity 14246;
BA_ "SPN" SG_ 2364681214 Hvesp8MaximumChargeVoltageLimit 14247;
BA_ "SPN" SG_ 2364681470 Hvesp8Module1OperationalStatus 14248;
BA_ "SPN" SG_ 2364681470 Hvesp8Module2OperationalStatus 14249;
BA_ "SPN" SG_ 2364681470 Hvesp8Module3OperationalStatus 14250;
BA_ "SPN" SG_ 2364681470 Hvesp8Module4OperationalStatus 14251;
BA_ "SPN" SG_ 2364681470 Hvesp8Module5OperationalStatus 14252;
BA_ "SPN" SG_ 2364681470 Hvesp8Module6OperationalStatus 14253;
BA_ "SPN" SG_ 2364681470 Hvesp8Module7OperationalStatus 14254;
BA_ "SPN" SG_ 2364681470 Hvesp8Module8OperationalStatus 14255;
BA_ "SPN" SG_ 2364681470 Hvesp8Module9OperationalStatus 14256;
BA_ "SPN" SG_ 2364681470 Hvesp8Module10OperationalStatus 14257;
BA_ "SPN" SG_ 2364681470 Hvesp8Module11OperationalStatus 14258;
BA_ "SPN" SG_ 2364681470 Hvesp8Module12OperationalStatus 14259;
BA_ "SPN" SG_ 2364681470 Hvesp8Module13OperationalStatus 14260;
BA_ "SPN" SG_ 2364681470 Hvesp8Module14OperationalStatus 14261;
BA_ "SPN" SG_ 2364681470 Hvesp8Module15OperationalStatus 14262;
BA_ "SPN" SG_ 2364681470 Hvesp8Module16OperationalStatus 14263;
BA_ "SPN" SG_ 2364681470 Hvesp8Module17OperationalStatus 14264;
BA_ "SPN" SG_ 2364681470 Hvesp8Module18OperationalStatus 14265;
BA_ "SPN" SG_ 2364681470 Hvesp8Module19OperationalStatus 14266;
BA_ "SPN" SG_ 2364681470 Hvesp8Module20OperationalStatus 14267;
BA_ "SPN" SG_ 2364681470 Hvesp8Module21OperationalStatus 14268;
BA_ "SPN" SG_ 2364681470 Hvesp8Module22OperationalStatus 14269;
BA_ "SPN" SG_ 2364681470 Hvesp8Module23OperationalStatus 14270;
BA_ "SPN" SG_ 2364681470 Hvesp8Module24OperationalStatus 14271;
BA_ "SPN" SG_ 2364681470 Hvesp8Module25OperationalStatus 14272;
BA_ "SPN" SG_ 2364681470 Hvesp8Module26OperationalStatus 14273;
BA_ "SPN" SG_ 2364681470 Hvesp8Module27OperationalStatus 14274;
BA_ "SPN" SG_ 2364681470 Hvesp8Module28OperationalStatus 14275;
BA_ "SPN" SG_ 2364681470 Hvesp8Module29OperationalStatus 14276;
BA_ "SPN" SG_ 2364681470 Hvesp8Module30OperationalStatus 14277;
BA_ "SPN" SG_ 2364681470 Hvesp8Module31OperationalStatus 14278;
BA_ "SPN" SG_ 2364681470 Hvesp8Module32OperationalStatus 14279;
BA_ "SPN" SG_ 2364681726 Hvsp8ThrmlMngmntSstmSlInptPwr 14280;
BA_ "SPN" SG_ 2364681726 Hvsp8TMtSstHVtIptPw 14281;
BA_ "SPN" SG_ 2364681726 Hvsp8ThrmlMngmntSstmCmprssrSpd 14282;
BA_ "SPN" SG_ 2364681726 Hvsp8ThrmlMngmntSstmRltvHmdt 14283;
BA_ "SPN" SG_ 2364681726 Hvsp8ThrmlMngmntSstmHtrStts 14284;
BA_ "SPN" SG_ 2364681726 Hvsp8ThrmlMngmntSstmHvlStts 14285;
BA_ "SPN" SG_ 2364681726 Hvsp8ThrmlMngmntSstmMd 14286;
BA_ "SPN" SG_ 2364681726 Hvsp8ThrmlMngmntSstmClntLvl 14287;
BA_ "SPN" SG_ 2364681982 Hvesp8AverageCellVoltage 14292;
BA_ "SPN" SG_ 2364681982 Hvsp8HghstCllVltgMdlNmr 14288;
BA_ "SPN" SG_ 2364681982 Hvsp8HghstCllVltgCllNmr 14289;
BA_ "SPN" SG_ 2364681982 Hvsp8LwstCllVltgMdlNmr 14290;
BA_ "SPN" SG_ 2364681982 Hvsp8LwstCllVltgCllNmr 14291;
BA_ "SPN" SG_ 2364682238 Hvsp8HghstCllTmprtrMdlNmr 14293;
BA_ "SPN" SG_ 2364682238 Hvsp8HghstCllTmprtrCllNmr 14294;
BA_ "SPN" SG_ 2364682238 Hvsp8LwstCllTmprtrMdlNmr 14295;
BA_ "SPN" SG_ 2364682238 Hvsp8LwstCllTmprtrCllNmr 14296;
BA_ "SPN" SG_ 2364682238 Hvess8ThermalEventDetected 21295;
BA_ "SPN" SG_ 2364682238 Hvsp8Dt9EmdddIntgrtSpprt 22995;
BA_ "SPN" SG_ 2364682238 Hvesp8Data9Counter 22996;
BA_ "SPN" SG_ 2364682238 Hvesp8Data9Crc 22997;
BA_ "SPN" SG_ 2364682494 Hvsp8HghstCllSttOfChrgMdlNmr 14297;
BA_ "SPN" SG_ 2364682494 Hvsp8HghstCllSttOfChrgCllNmr 14298;
BA_ "SPN" SG_ 2364682494 Hvsp8LwstCllSttOfChrgMdlNmr 14299;
BA_ "SPN" SG_ 2364682494 Hvsp8LwstCllSttOfChrgCllNmr 14300;
BA_ "SPN" SG_ 2364682494 Hvsp8HghVltgBsAtvIsltnTstRslts 14301;
BA_ "SPN" SG_ 2364682494 Hvsp8HghVltgBsPssvIsltnTstRslts 14302;
BA_ "SPN" SG_ 2364682750 Hvesp8ActualChargeRate 14305;
BA_ "SPN" SG_ 2364682750 Hvsp8BsVltgNgtvTChsssGrndVltg 14303;
BA_ "SPN" SG_ 2364682750 Hvsp8VltgLvlNgtvTChsssGrndVltg 14304;
BA_ "SPN" SG_ 2364683006 Hvsp9DshrgPwrLmtDTSttOfChrg 14334;
BA_ "SPN" SG_ 2364683006 Hvsp9DshrgPwrLmtDTBttrTmprtr 14335;
BA_ "SPN" SG_ 2364683006 Hvsp9DsPwLtDTBttDstCdt 14336;
BA_ "SPN" SG_ 2364683006 Hvsp9DshrgPwrLmtDTBttrOrCllVltg 14337;
BA_ "SPN" SG_ 2364683006 Hvsp9DshrgPwrLmtDTBttrCrrnt 14338;
BA_ "SPN" SG_ 2364683006 Hvsp9DshrgPwrLmtDTAnUndfndCs 14339;
BA_ "SPN" SG_ 2364683006 Hvsp9ChrgPwrLmtDTSttOfChrg 14340;
BA_ "SPN" SG_ 2364683006 Hvsp9ChrgPwrLmtDTBttrTmprtr 14341;
BA_ "SPN" SG_ 2364683006 Hvsp9ChrgPwrLmtDTBttrDgnstCndtn 14342;
BA_ "SPN" SG_ 2364683006 Hvsp9ChrgPwrLmtDTBttrOrCllVltg 14343;
BA_ "SPN" SG_ 2364683006 Hvsp9ChrgPwrLmtDTBttrCrrnt 14344;
BA_ "SPN" SG_ 2364683006 Hvsp9ChrgPwrLmtDTAnUndfndCs 14345;
BA_ "SPN" SG_ 2364683262 Hvesp9AvailableDischargePower 14346;
BA_ "SPN" SG_ 2364683262 Hvesp9AvailableChargePower 14347;
BA_ "SPN" SG_ 2364683262 Hvesp9VoltageLevel 14348;
BA_ "SPN" SG_ 2364683262 Hvesp9Current 14349;
BA_ "SPN" SG_ 2364683518 Hvesp9FastUpdateStateOfCharge 14350;
BA_ "SPN" SG_ 2364683518 Hvesp9HighestCellVoltage 14351;
BA_ "SPN" SG_ 2364683518 Hvesp9LowestCellVoltage 14352;
BA_ "SPN" SG_ 2364683518 Hvsp9CllVltgDffrntlStts 14353;
BA_ "SPN" SG_ 2364683774 Hvesp9HighestCellTemperature 14354;
BA_ "SPN" SG_ 2364683774 Hvesp9LowestCellTemperature 14355;
BA_ "SPN" SG_ 2364683774 Hvesp9AverageCellTemperature 14356;
BA_ "SPN" SG_ 2364683774 Hvsp9CllTmprtrDffrntlStts 14357;
BA_ "SPN" SG_ 2364684030 Hvesp9DischargeCapacity 14358;
BA_ "SPN" SG_ 2364684030 Hvesp9ChargeCapacity 14359;
BA_ "SPN" SG_ 2364684030 Hvesp9CellBalancingCount 14360;
BA_ "SPN" SG_ 2364684286 Hvesp9LowestCellStateOfCharge 14363;
BA_ "SPN" SG_ 2364684286 Hvesp9HighestCellStateOfCharge 14364;
BA_ "SPN" SG_ 2364684286 Hvsp9MxmmInstntnsDshrgCrrntLmt 14361;
BA_ "SPN" SG_ 2364684286 Hvsp9MxmmInstntnsChrgCrrntLmt 14362;
BA_ "SPN" SG_ 2364684542 Hvesp9BusVoltage 14365;
BA_ "SPN" SG_ 2364684542 Hvesp9IgnitionVoltage 14366;
BA_ "SPN" SG_ 2364684542 Hvesp9IntakeCoolantTemperature 14367;
BA_ "SPN" SG_ 2364684542 Hvesp9OutletCoolantTemperature 14368;
BA_ "SPN" SG_ 2364684542 Hvesp9ElectronicsTemperature 14369;
BA_ "SPN" SG_ 2364684542 Hvesp9Temperature 14370;
BA_ "SPN" SG_ 2364684798 Hvesp9HvilStatus 14378;
BA_ "SPN" SG_ 2364684798 Hvesp9InertiaSwitchStatus 14379;
BA_ "SPN" SG_ 2364684798 Hvesp9StateOfChargeStatus 14380;
BA_ "SPN" SG_ 2364684798 Hvesp9CellBalanceStatus 14381;
BA_ "SPN" SG_ 2364684798 Hvesp9CellBalancingActive 14382;
BA_ "SPN" SG_ 2364684798 Hvesp9InternalChargerStatus 14383;
BA_ "SPN" SG_ 2364684798 Hvesp9OperationalStatus 14385;
BA_ "SPN" SG_ 2364684798 Hvesp9Status1Counter 14386;
BA_ "SPN" SG_ 2364684798 Hvesp9Status1Crc 14387;
BA_ "SPN" SG_ 2364684798 Hvsp9HghVltgBsPstvCnttrStt 14371;
BA_ "SPN" SG_ 2364684798 Hvsp9HghVltgBsNgtvCnttrStt 14372;
BA_ "SPN" SG_ 2364684798 Hvsp9HghVltgBsDsnntFrwrnng 14373;
BA_ "SPN" SG_ 2364684798 Hvsp9HghVltgBsPrChrgRlStt 14374;
BA_ "SPN" SG_ 2364684798 Hvsp9CntrOfPkCnttrStt 14375;
BA_ "SPN" SG_ 2364684798 Hvsp9HghVltgBsAtvIsltnTstStts 14376;
BA_ "SPN" SG_ 2364684798 Hvsp9HghVltgBsPssvIsltnTstStts 14377;
BA_ "SPN" SG_ 2364684798 Hvsp9HghVltgBsCnntnStts 14384;
BA_ "SPN" SG_ 2364685054 Hvesp9DischargeEnergyCapacity 14388;
BA_ "SPN" SG_ 2364685054 Hvesp9ChargeEnergyCapacity 14389;
BA_ "SPN" SG_ 2364685054 Hvesp9MaximumChargeVoltageLimit 14390;
BA_ "SPN" SG_ 2364685310 Hvesp9Module1OperationalStatus 14391;
BA_ "SPN" SG_ 2364685310 Hvesp9Module2OperationalStatus 14392;
BA_ "SPN" SG_ 2364685310 Hvesp9Module3OperationalStatus 14393;
BA_ "SPN" SG_ 2364685310 Hvesp9Module4OperationalStatus 14394;
BA_ "SPN" SG_ 2364685310 Hvesp9Module5OperationalStatus 14395;
BA_ "SPN" SG_ 2364685310 Hvesp9Module6OperationalStatus 14396;
BA_ "SPN" SG_ 2364685310 Hvesp9Module7OperationalStatus 14397;
BA_ "SPN" SG_ 2364685310 Hvesp9Module8OperationalStatus 14398;
BA_ "SPN" SG_ 2364685310 Hvesp9Module9OperationalStatus 14399;
BA_ "SPN" SG_ 2364685310 Hvesp9Module10OperationalStatus 14400;
BA_ "SPN" SG_ 2364685310 Hvesp9Module11OperationalStatus 14401;
BA_ "SPN" SG_ 2364685310 Hvesp9Module12OperationalStatus 14402;
BA_ "SPN" SG_ 2364685310 Hvesp9Module13OperationalStatus 14403;
BA_ "SPN" SG_ 2364685310 Hvesp9Module14OperationalStatus 14404;
BA_ "SPN" SG_ 2364685310 Hvesp9Module15OperationalStatus 14405;
BA_ "SPN" SG_ 2364685310 Hvesp9Module16OperationalStatus 14406;
BA_ "SPN" SG_ 2364685310 Hvesp9Module17OperationalStatus 14407;
BA_ "SPN" SG_ 2364685310 Hvesp9Module18OperationalStatus 14408;
BA_ "SPN" SG_ 2364685310 Hvesp9Module19OperationalStatus 14409;
BA_ "SPN" SG_ 2364685310 Hvesp9Module20OperationalStatus 14410;
BA_ "SPN" SG_ 2364685310 Hvesp9Module21OperationalStatus 14411;
BA_ "SPN" SG_ 2364685310 Hvesp9Module22OperationalStatus 14412;
BA_ "SPN" SG_ 2364685310 Hvesp9Module23OperationalStatus 14413;
BA_ "SPN" SG_ 2364685310 Hvesp9Module24OperationalStatus 14414;
BA_ "SPN" SG_ 2364685310 Hvesp9Module25OperationalStatus 14415;
BA_ "SPN" SG_ 2364685310 Hvesp9Module26OperationalStatus 14416;
BA_ "SPN" SG_ 2364685310 Hvesp9Module27OperationalStatus 14417;
BA_ "SPN" SG_ 2364685310 Hvesp9Module28OperationalStatus 14418;
BA_ "SPN" SG_ 2364685310 Hvesp9Module29OperationalStatus 14419;
BA_ "SPN" SG_ 2364685310 Hvesp9Module30OperationalStatus 14420;
BA_ "SPN" SG_ 2364685310 Hvesp9Module31OperationalStatus 14421;
BA_ "SPN" SG_ 2364685310 Hvesp9Module32OperationalStatus 14422;
BA_ "SPN" SG_ 2364685566 Hvsp9ThrmlMngmntSstmSlInptPwr 14423;
BA_ "SPN" SG_ 2364685566 Hvsp9TMtSstHVtIptPw 14424;
BA_ "SPN" SG_ 2364685566 Hvsp9ThrmlMngmntSstmCmprssrSpd 14425;
BA_ "SPN" SG_ 2364685566 Hvsp9ThrmlMngmntSstmRltvHmdt 14426;
BA_ "SPN" SG_ 2364685566 Hvsp9ThrmlMngmntSstmHtrStts 14427;
BA_ "SPN" SG_ 2364685566 Hvsp9ThrmlMngmntSstmHvlStts 14428;
BA_ "SPN" SG_ 2364685566 Hvsp9ThrmlMngmntSstmMd 14429;
BA_ "SPN" SG_ 2364685566 Hvsp9ThrmlMngmntSstmClntLvl 14430;
BA_ "SPN" SG_ 2364685822 Hvesp9AverageCellVoltage 14435;
BA_ "SPN" SG_ 2364685822 Hvsp9HghstCllVltgMdlNmr 14431;
BA_ "SPN" SG_ 2364685822 Hvsp9HghstCllVltgCllNmr 14432;
BA_ "SPN" SG_ 2364685822 Hvsp9LwstCllVltgMdlNmr 14433;
BA_ "SPN" SG_ 2364685822 Hvsp9LwstCllVltgCllNmr 14434;
BA_ "SPN" SG_ 2364686078 Hvsp9HghstCllTmprtrMdlNmr 14436;
BA_ "SPN" SG_ 2364686078 Hvsp9HghstCllTmprtrCllNmr 14437;
BA_ "SPN" SG_ 2364686078 Hvsp9LwstCllTmprtrMdlNmr 14438;
BA_ "SPN" SG_ 2364686078 Hvsp9LwstCllTmprtrCllNmr 14439;
BA_ "SPN" SG_ 2364686078 Hvess9ThermalEventDetected 21296;
BA_ "SPN" SG_ 2364686078 Hvsp9Dt9EmdddIntgrtSpprt 22998;
BA_ "SPN" SG_ 2364686078 Hvesp9Data9Counter 22999;
BA_ "SPN" SG_ 2364686078 Hvesp9Data9Crc 23000;
BA_ "SPN" SG_ 2364686334 Hvsp9HghstCllSttOfChrgMdlNmr 14440;
BA_ "SPN" SG_ 2364686334 Hvsp9HghstCllSttOfChrgCllNmr 14441;
BA_ "SPN" SG_ 2364686334 Hvsp9LwstCllSttOfChrgMdlNmr 14442;
BA_ "SPN" SG_ 2364686334 Hvsp9LwstCllSttOfChrgCllNmr 14443;
BA_ "SPN" SG_ 2364686334 Hvsp9HghVltgBsAtvIsltnTstRslts 14444;
BA_ "SPN" SG_ 2364686334 Hvsp9HghVltgBsPssvIsltnTstRslts 14445;
BA_ "SPN" SG_ 2364686590 Hvesp9ActualChargeRate 14448;
BA_ "SPN" SG_ 2364686590 Hvsp9BsVltgNgtvTChsssGrndVltg 14446;
BA_ "SPN" SG_ 2364686590 Hvsp9VltgLvlNgtvTChsssGrndVltg 14447;
BA_ "SPN" SG_ 2364686846 Hvsp10DshrgPwrLmtDTSttOfChrg 14477;
BA_ "SPN" SG_ 2364686846 Hvsp10DshrgPwrLmtDTBttrTmprtr 14478;
BA_ "SPN" SG_ 2364686846 Hvsp10DsPwLtDTBttDstCdt 14479;
BA_ "SPN" SG_ 2364686846 Hvsp10DsPwLtDTBttOCVt 14480;
BA_ "SPN" SG_ 2364686846 Hvsp10DshrgPwrLmtDTBttrCrrnt 14481;
BA_ "SPN" SG_ 2364686846 Hvsp10DshrgPwrLmtDTAnUndfndCs 14482;
BA_ "SPN" SG_ 2364686846 Hvsp10ChrgPwrLmtDTSttOfChrg 14483;
BA_ "SPN" SG_ 2364686846 Hvsp10ChrgPwrLmtDTBttrTmprtr 14484;
BA_ "SPN" SG_ 2364686846 Hvsp10CPwLtDTBttDstCdt 14485;
BA_ "SPN" SG_ 2364686846 Hvsp10ChrgPwrLmtDTBttrOrCllVltg 14486;
BA_ "SPN" SG_ 2364686846 Hvsp10ChrgPwrLmtDTBttrCrrnt 14487;
BA_ "SPN" SG_ 2364686846 Hvsp10ChrgPwrLmtDTAnUndfndCs 14488;
BA_ "SPN" SG_ 2364687102 Hvesp10AvailableDischargePower 14489;
BA_ "SPN" SG_ 2364687102 Hvesp10AvailableChargePower 14490;
BA_ "SPN" SG_ 2364687102 Hvesp10VoltageLevel 14491;
BA_ "SPN" SG_ 2364687102 Hvesp10Current 14492;
BA_ "SPN" SG_ 2364687358 Hvesp10FastUpdateStateOfCharge 14493;
BA_ "SPN" SG_ 2364687358 Hvesp10HighestCellVoltage 14494;
BA_ "SPN" SG_ 2364687358 Hvesp10LowestCellVoltage 14495;
BA_ "SPN" SG_ 2364687358 Hvsp10CllVltgDffrntlStts 14496;
BA_ "SPN" SG_ 2364687614 Hvesp10HighestCellTemperature 14497;
BA_ "SPN" SG_ 2364687614 Hvesp10LowestCellTemperature 14498;
BA_ "SPN" SG_ 2364687614 Hvesp10AverageCellTemperature 14499;
BA_ "SPN" SG_ 2364687614 Hvsp10CllTmprtrDffrntlStts 14500;
BA_ "SPN" SG_ 2364687870 Hvesp10DischargeCapacity 14501;
BA_ "SPN" SG_ 2364687870 Hvesp10ChargeCapacity 14502;
BA_ "SPN" SG_ 2364687870 Hvesp10CellBalancingCount 14503;
BA_ "SPN" SG_ 2364688126 Hvesp10LowestCellStateOfCharge 14506;
BA_ "SPN" SG_ 2364688126 Hvesp10HighestCellStateOfCharge 14507;
BA_ "SPN" SG_ 2364688126 Hvsp10MxmmInstntnsDshrgCrrntLmt 14504;
BA_ "SPN" SG_ 2364688126 Hvsp10MxmmInstntnsChrgCrrntLmt 14505;
BA_ "SPN" SG_ 2364688382 Hvesp10BusVoltage 14508;
BA_ "SPN" SG_ 2364688382 Hvesp10IgnitionVoltage 14509;
BA_ "SPN" SG_ 2364688382 Hvesp10IntakeCoolantTemperature 14510;
BA_ "SPN" SG_ 2364688382 Hvesp10OutletCoolantTemperature 14511;
BA_ "SPN" SG_ 2364688382 Hvesp10ElectronicsTemperature 14512;
BA_ "SPN" SG_ 2364688382 Hvesp10Temperature 14513;
BA_ "SPN" SG_ 2364688638 Hvesp10HvilStatus 14521;
BA_ "SPN" SG_ 2364688638 Hvesp10InertiaSwitchStatus 14522;
BA_ "SPN" SG_ 2364688638 Hvesp10StateOfChargeStatus 14523;
BA_ "SPN" SG_ 2364688638 Hvesp10CellBalanceStatus 14524;
BA_ "SPN" SG_ 2364688638 Hvesp10CellBalancingActive 14525;
BA_ "SPN" SG_ 2364688638 Hvesp10InternalChargerStatus 14526;
BA_ "SPN" SG_ 2364688638 Hvesp10OperationalStatus 14528;
BA_ "SPN" SG_ 2364688638 Hvesp10Status1Counter 14529;
BA_ "SPN" SG_ 2364688638 Hvesp10Status1Crc 14530;
BA_ "SPN" SG_ 2364688638 Hvsp10HghVltgBsPstvCnttrStt 14514;
BA_ "SPN" SG_ 2364688638 Hvsp10HghVltgBsNgtvCnttrStt 14515;
BA_ "SPN" SG_ 2364688638 Hvsp10HghVltgBsDsnntFrwrnng 14516;
BA_ "SPN" SG_ 2364688638 Hvsp10HghVltgBsPrChrgRlStt 14517;
BA_ "SPN" SG_ 2364688638 Hvsp10CntrOfPkCnttrStt 14518;
BA_ "SPN" SG_ 2364688638 Hvsp10HghVltgBsAtvIsltnTstStts 14519;
BA_ "SPN" SG_ 2364688638 Hvsp10HghVltgBsPssvIsltnTstStts 14520;
BA_ "SPN" SG_ 2364688638 Hvsp10HghVltgBsCnntnStts 14527;
BA_ "SPN" SG_ 2364688894 Hvesp10DischargeEnergyCapacity 14531;
BA_ "SPN" SG_ 2364688894 Hvesp10ChargeEnergyCapacity 14532;
BA_ "SPN" SG_ 2364688894 Hvsp10MxmmChrgVltgLmt 14533;
BA_ "SPN" SG_ 2364689150 Hvesp10Module1OperationalStatus 14534;
BA_ "SPN" SG_ 2364689150 Hvesp10Module2OperationalStatus 14535;
BA_ "SPN" SG_ 2364689150 Hvesp10Module3OperationalStatus 14536;
BA_ "SPN" SG_ 2364689150 Hvesp10Module4OperationalStatus 14537;
BA_ "SPN" SG_ 2364689150 Hvesp10Module5OperationalStatus 14538;
BA_ "SPN" SG_ 2364689150 Hvesp10Module6OperationalStatus 14539;
BA_ "SPN" SG_ 2364689150 Hvesp10Module7OperationalStatus 14540;
BA_ "SPN" SG_ 2364689150 Hvesp10Module8OperationalStatus 14541;
BA_ "SPN" SG_ 2364689150 Hvesp10Module9OperationalStatus 14542;
BA_ "SPN" SG_ 2364689150 Hvsp10Mdl10OprtnlStts 14543;
BA_ "SPN" SG_ 2364689150 Hvsp10Mdl11OprtnlStts 14544;
BA_ "SPN" SG_ 2364689150 Hvsp10Mdl12OprtnlStts 14545;
BA_ "SPN" SG_ 2364689150 Hvsp10Mdl13OprtnlStts 14546;
BA_ "SPN" SG_ 2364689150 Hvsp10Mdl14OprtnlStts 14547;
BA_ "SPN" SG_ 2364689150 Hvsp10Mdl15OprtnlStts 14548;
BA_ "SPN" SG_ 2364689150 Hvsp10Mdl16OprtnlStts 14549;
BA_ "SPN" SG_ 2364689150 Hvsp10Mdl17OprtnlStts 14550;
BA_ "SPN" SG_ 2364689150 Hvsp10Mdl18OprtnlStts 14551;
BA_ "SPN" SG_ 2364689150 Hvsp10Mdl19OprtnlStts 14552;
BA_ "SPN" SG_ 2364689150 Hvsp10Mdl20OprtnlStts 14553;
BA_ "SPN" SG_ 2364689150 Hvsp10Mdl21OprtnlStts 14554;
BA_ "SPN" SG_ 2364689150 Hvsp10Mdl22OprtnlStts 14555;
BA_ "SPN" SG_ 2364689150 Hvsp10Mdl23OprtnlStts 14556;
BA_ "SPN" SG_ 2364689150 Hvsp10Mdl24OprtnlStts 14557;
BA_ "SPN" SG_ 2364689150 Hvsp10Mdl25OprtnlStts 14558;
BA_ "SPN" SG_ 2364689150 Hvsp10Mdl26OprtnlStts 14559;
BA_ "SPN" SG_ 2364689150 Hvsp10Mdl27OprtnlStts 14560;
BA_ "SPN" SG_ 2364689150 Hvsp10Mdl28OprtnlStts 14561;
BA_ "SPN" SG_ 2364689150 Hvsp10Mdl29OprtnlStts 14562;
BA_ "SPN" SG_ 2364689150 Hvsp10Mdl30OprtnlStts 14563;
BA_ "SPN" SG_ 2364689150 Hvsp10Mdl31OprtnlStts 14564;
BA_ "SPN" SG_ 2364689150 Hvsp10Mdl32OprtnlStts 14565;
BA_ "SPN" SG_ 2364689406 Hvsp10ThrmlMngmntSstmSlInptPwr 14566;
BA_ "SPN" SG_ 2364689406 Hvsp10TMtSstHVtIptPw 14567;
BA_ "SPN" SG_ 2364689406 Hvsp10ThrmlMngmntSstmCmprssrSpd 14568;
BA_ "SPN" SG_ 2364689406 Hvsp10ThrmlMngmntSstmRltvHmdt 14569;
BA_ "SPN" SG_ 2364689406 Hvsp10ThrmlMngmntSstmHtrStts 14570;
BA_ "SPN" SG_ 2364689406 Hvsp10ThrmlMngmntSstmHvlStts 14571;
BA_ "SPN" SG_ 2364689406 Hvsp10ThrmlMngmntSstmMd 14572;
BA_ "SPN" SG_ 2364689406 Hvsp10ThrmlMngmntSstmClntLvl 14573;
BA_ "SPN" SG_ 2364689662 Hvesp10AverageCellVoltage 14578;
BA_ "SPN" SG_ 2364689662 Hvsp10HghstCllVltgMdlNmr 14574;
BA_ "SPN" SG_ 2364689662 Hvsp10HghstCllVltgCllNmr 14575;
BA_ "SPN" SG_ 2364689662 Hvsp10LwstCllVltgMdlNmr 14576;
BA_ "SPN" SG_ 2364689662 Hvsp10LwstCllVltgCllNmr 14577;
BA_ "SPN" SG_ 2364689918 Hvsp10HghstCllTmprtrMdlNmr 14579;
BA_ "SPN" SG_ 2364689918 Hvsp10HghstCllTmprtrCllNmr 14580;
BA_ "SPN" SG_ 2364689918 Hvsp10LwstCllTmprtrMdlNmr 14581;
BA_ "SPN" SG_ 2364689918 Hvsp10LwstCllTmprtrCllNmr 14582;
BA_ "SPN" SG_ 2364689918 Hvess10ThermalEventDetected 21297;
BA_ "SPN" SG_ 2364689918 Hvsp10Dt9EmdddIntgrtSpprt 23001;
BA_ "SPN" SG_ 2364689918 Hvesp10Data9Counter 23002;
BA_ "SPN" SG_ 2364689918 Hvesp10Data9Crc 23003;
BA_ "SPN" SG_ 2364690174 Hvsp10HghstCllSttOfChrgMdlNmr 14583;
BA_ "SPN" SG_ 2364690174 Hvsp10HghstCllSttOfChrgCllNmr 14584;
BA_ "SPN" SG_ 2364690174 Hvsp10LwstCllSttOfChrgMdlNmr 14585;
BA_ "SPN" SG_ 2364690174 Hvsp10LwstCllSttOfChrgCllNmr 14586;
BA_ "SPN" SG_ 2364690174 Hvsp10HghVltgBsAtvIsltnTstRslts 14587;
BA_ "SPN" SG_ 2364690174 Hvsp10HVtBsPssvIstTstRsts 14588;
BA_ "SPN" SG_ 2364690430 Hvesp10ActualChargeRate 14591;
BA_ "SPN" SG_ 2364690430 Hvsp10BsVltgNgtvTChsssGrndVltg 14589;
BA_ "SPN" SG_ 2364690430 Hvsp10VltgLvlNgtvTChsssGrndVltg 14590;
BA_ "SPN" SG_ 2566564862 Hvesp10NominalVoltage 14600;
BA_ "SPN" SG_ 2566564862 Hvesp10CellMaximumVoltageLimit 14607;
BA_ "SPN" SG_ 2566564862 Hvesp10CellMinimumVoltageLimit 14608;
BA_ "SPN" SG_ 2566564862 Hvsp10RmmnddMnmmOprtngVltg 14601;
BA_ "SPN" SG_ 2566564862 Hvsp10RmmnddMxmmOprtngVltg 14602;
BA_ "SPN" SG_ 2566564862 Hvsp10RmmnddMnmmSttOfChrg 14603;
BA_ "SPN" SG_ 2566564862 Hvsp10RmmnddMxmmSttOfChrg 14604;
BA_ "SPN" SG_ 2566564862 Hvsp10RmmnddMxmmOprtngTmprtr 14605;
BA_ "SPN" SG_ 2566564862 Hvsp10RmmnddMnmmOprtngTmprtr 14606;
BA_ "SPN" SG_ 2633673982 Hvesp10StateOfHealth 14592;
BA_ "SPN" SG_ 2633673982 Hvesp10TotalEnergyThroughput 14594;
BA_ "SPN" SG_ 2633673982 Hvesp10TotalAccumulatedCharge 14595;
BA_ "SPN" SG_ 2633673982 Hvesp10TotalLifetimeEnergyInput 14596;
BA_ "SPN" SG_ 2633673982 Hvsp10CnttrOpnUndrLdCnt 14593;
BA_ "SPN" SG_ 2633673982 Hvsp10TtlLftmEnrgOtpt 14597;
